VERSION ""

NS_ :

BS_:

BU_: Vector__XXX

BO_ 2365402110 EJM6: 8 Vector__XXX
SG_ Jystck6GrpXAxsNtrlPositionStatus : 0|2@1+ (1,0) [0|3] "" Vector__XXX
SG_ Jystck6GrpXAxsLvrLftNegPosStatus : 2|2@1+ (1,0) [0|3] "" Vector__XXX
SG_ Jystck6GrpXAxsLvrRghtPstvPosStat : 4|2@1+ (1,0) [0|3] "" Vector__XXX
SG_ Joystick6GripXAxisPosition : 6|10@1+ (0.1,0) [0|102] "%" Vector__XXX
SG_ Jystck6GrpYAxsNtrlPositionStatus : 16|2@1+ (1,0) [0|3] "" Vector__XXX
SG_ Jystck6GrpYAxsLvrBackNegPosStat : 18|2@1+ (1,0) [0|3] "" Vector__XXX
SG_ Jystck6GrpYAxsLvrFrwdPstvPosStat : 20|2@1+ (1,0) [0|3] "" Vector__XXX
SG_ Joystick6GripYAxisPosition : 22|10@1+ (0.1,0) [0|102] "%" Vector__XXX
SG_ Jystck6ThetaAxsNtrlPosStatus : 32|2@1+ (1,0) [0|3] "" Vector__XXX
SG_ Jystck6ThtAxsCntrClckwsNegPsStat : 34|2@1+ (1,0) [0|3] "" Vector__XXX
SG_ Jystck6ThetaAxsClckwsPstvPosStat : 36|2@1+ (1,0) [0|3] "" Vector__XXX
SG_ Joystick6ThetaAxisPosition : 38|10@1+ (0.1,0) [0|102] "%" Vector__XXX
SG_ Jystck6ThetaAxsDetentPosStatus : 50|2@1+ (1,0) [0|3] "" Vector__XXX
SG_ Jystck6GrpYAxsDetentPosStatus : 52|2@1+ (1,0) [0|3] "" Vector__XXX
SG_ Jystck6GrpXAxsDetentPosStatus : 54|2@1+ (1,0) [0|3] "" Vector__XXX
SG_ Joystick6Button16PressedStatus : 56|2@1+ (1,0) [0|3] "" Vector__XXX
SG_ Joystick6Button15PressedStatus : 58|2@1+ (1,0) [0|3] "" Vector__XXX
SG_ Joystick6Button14PressedStatus : 60|2@1+ (1,0) [0|3] "" Vector__XXX
SG_ Joystick6Button13PressedStatus : 62|2@1+ (1,0) [0|3] "" Vector__XXX

BO_ 2365402366 BJM6: 8 Vector__XXX
SG_ Jystck6XAxsNeutralPositionStatus : 0|2@1+ (1,0) [0|3] "" Vector__XXX
SG_ Jystck6XAxsLvrLftNegPosStatus : 2|2@1+ (1,0) [0|3] "" Vector__XXX
SG_ Jystck6XAxsLvrRightPstvPosStatus : 4|2@1+ (1,0) [0|3] "" Vector__XXX
SG_ Joystick6XAxisPosition : 6|10@1+ (0.1,0) [0|102] "%" Vector__XXX
SG_ Jystck6YAxsNeutralPositionStatus : 16|2@1+ (1,0) [0|3] "" Vector__XXX
SG_ Jystck6YAxsLvrBackNegPosStatus : 18|2@1+ (1,0) [0|3] "" Vector__XXX
SG_ Jystck6YAxsLvrFrwdPstvPosStatus : 20|2@1+ (1,0) [0|3] "" Vector__XXX
SG_ Joystick6YAxisPosition : 22|10@1+ (0.1,0) [0|102] "%" Vector__XXX
SG_ Jystck6YAxsDetentPositionStatus : 36|2@1+ (1,0) [0|3] "" Vector__XXX
SG_ Jystck6XAxsDetentPositionStatus : 38|2@1+ (1,0) [0|3] "" Vector__XXX
SG_ Joystick6Button4PressedStatus : 40|2@1+ (1,0) [0|3] "" Vector__XXX
SG_ Joystick6Button3PressedStatus : 42|2@1+ (1,0) [0|3] "" Vector__XXX
SG_ Joystick6Button2PressedStatus : 44|2@1+ (1,0) [0|3] "" Vector__XXX
SG_ Joystick6Button1PressedStatus : 46|2@1+ (1,0) [0|3] "" Vector__XXX
SG_ Joystick6Button8PressedStatus : 48|2@1+ (1,0) [0|3] "" Vector__XXX
SG_ Joystick6Button7PressedStatus : 50|2@1+ (1,0) [0|3] "" Vector__XXX
SG_ Joystick6Button6PressedStatus : 52|2@1+ (1,0) [0|3] "" Vector__XXX
SG_ Joystick6Button5PressedStatus : 54|2@1+ (1,0) [0|3] "" Vector__XXX
SG_ Joystick6Button12PressedStatus : 56|2@1+ (1,0) [0|3] "" Vector__XXX
SG_ Joystick6Button11PressedStatus : 58|2@1+ (1,0) [0|3] "" Vector__XXX
SG_ Joystick6Button10PressedStatus : 60|2@1+ (1,0) [0|3] "" Vector__XXX
SG_ Joystick6Button9PressedStatus : 62|2@1+ (1,0) [0|3] "" Vector__XXX

BO_ 2365402622 EJM5: 8 Vector__XXX
SG_ Jystck5GrpXAxsNtrlPositionStatus : 0|2@1+ (1,0) [0|3] "" Vector__XXX
SG_ Jystck5GrpXAxsLvrLftNegPosStatus : 2|2@1+ (1,0) [0|3] "" Vector__XXX
SG_ Jystck5GrpXAxsLvrRghtPstvPosStat : 4|2@1+ (1,0) [0|3] "" Vector__XXX
SG_ Joystick5GripXAxisPosition : 6|10@1+ (0.1,0) [0|102] "%" Vector__XXX
SG_ Jystck5GrpYAxsNtrlPositionStatus : 16|2@1+ (1,0) [0|3] "" Vector__XXX
SG_ Jystck5GrpYAxsLvrBackNegPosStat : 18|2@1+ (1,0) [0|3] "" Vector__XXX
SG_ Jystck5GrpYAxsLvrFrwdPstvPosStat : 20|2@1+ (1,0) [0|3] "" Vector__XXX
SG_ Joystick5GripYAxisPosition : 22|10@1+ (0.1,0) [0|102] "%" Vector__XXX
SG_ Jystck5ThetaAxsNtrlPosStatus : 32|2@1+ (1,0) [0|3] "" Vector__XXX
SG_ Jystck5ThtAxsCntrClckwsNegPsStat : 34|2@1+ (1,0) [0|3] "" Vector__XXX
SG_ Jystck5ThetaAxsClckwsPstvPosStat : 36|2@1+ (1,0) [0|3] "" Vector__XXX
SG_ Joystick5ThetaAxisPosition : 38|10@1+ (0.1,0) [0|102] "%" Vector__XXX
SG_ Jystck5ThetaAxsDetentPosStatus : 50|2@1+ (1,0) [0|3] "" Vector__XXX
SG_ Jystck5GrpYAxsDetentPosStatus : 52|2@1+ (1,0) [0|3] "" Vector__XXX
SG_ Jystck5GrpXAxsDetentPosStatus : 54|2@1+ (1,0) [0|3] "" Vector__XXX
SG_ Joystick5Button16PressedStatus : 56|2@1+ (1,0) [0|3] "" Vector__XXX
SG_ Joystick5Button15PressedStatus : 58|2@1+ (1,0) [0|3] "" Vector__XXX
SG_ Joystick5Button14PressedStatus : 60|2@1+ (1,0) [0|3] "" Vector__XXX
SG_ Joystick5Button13PressedStatus : 62|2@1+ (1,0) [0|3] "" Vector__XXX

BO_ 2365402878 BJM5: 8 Vector__XXX
SG_ Jystck5XAxsNeutralPositionStatus : 0|2@1+ (1,0) [0|3] "" Vector__XXX
SG_ Jystck5XAxsLvrLftNegPosStatus : 2|2@1+ (1,0) [0|3] "" Vector__XXX
SG_ Jystck5XAxsLvrRightPstvPosStatus : 4|2@1+ (1,0) [0|3] "" Vector__XXX
SG_ Joystick5XAxisPosition : 6|10@1+ (0.1,0) [0|102] "%" Vector__XXX
SG_ Jystck5YAxsNeutralPositionStatus : 16|2@1+ (1,0) [0|3] "" Vector__XXX
SG_ Jystck5YAxsLvrBackNegPosStatus : 18|2@1+ (1,0) [0|3] "" Vector__XXX
SG_ Jystck5YAxsLvrFrwdPstvPosStatus : 20|2@1+ (1,0) [0|3] "" Vector__XXX
SG_ Joystick5YAxisPosition : 22|10@1+ (0.1,0) [0|102] "%" Vector__XXX
SG_ Jystck5YAxsDetentPositionStatus : 36|2@1+ (1,0) [0|3] "" Vector__XXX
SG_ Jystck5XAxsDetentPositionStatus : 38|2@1+ (1,0) [0|3] "" Vector__XXX
SG_ Joystick5Button4PressedStatus : 40|2@1+ (1,0) [0|3] "" Vector__XXX
SG_ Joystick5Button3PressedStatus : 42|2@1+ (1,0) [0|3] "" Vector__XXX
SG_ Joystick5Button2PressedStatus : 44|2@1+ (1,0) [0|3] "" Vector__XXX
SG_ Joystick5Button1PressedStatus : 46|2@1+ (1,0) [0|3] "" Vector__XXX
SG_ Joystick5Button8PressedStatus : 48|2@1+ (1,0) [0|3] "" Vector__XXX
SG_ Joystick5Button7PressedStatus : 50|2@1+ (1,0) [0|3] "" Vector__XXX
SG_ Joystick5Button6PressedStatus : 52|2@1+ (1,0) [0|3] "" Vector__XXX
SG_ Joystick5Button5PressedStatus : 54|2@1+ (1,0) [0|3] "" Vector__XXX
SG_ Joystick5Button12PressedStatus : 56|2@1+ (1,0) [0|3] "" Vector__XXX
SG_ Joystick5Button11PressedStatus : 58|2@1+ (1,0) [0|3] "" Vector__XXX
SG_ Joystick5Button10PressedStatus : 60|2@1+ (1,0) [0|3] "" Vector__XXX
SG_ Joystick5Button9PressedStatus : 62|2@1+ (1,0) [0|3] "" Vector__XXX

BO_ 2365403134 EJM4: 8 Vector__XXX
SG_ Jystck4GrpXAxsNtrlPositionStatus : 0|2@1+ (1,0) [0|3] "" Vector__XXX
SG_ Jystck4GrpXAxsLvrLftNegPosStatus : 2|2@1+ (1,0) [0|3] "" Vector__XXX
SG_ Jystck4GrpXAxsLvrRghtPstvPosStat : 4|2@1+ (1,0) [0|3] "" Vector__XXX
SG_ Joystick4GripXAxisPosition : 6|10@1+ (0.1,0) [0|102] "%" Vector__XXX
SG_ Jystck4GrpYAxsNtrlPositionStatus : 16|2@1+ (1,0) [0|3] "" Vector__XXX
SG_ Jystck4GrpYAxsLvrBackNegPosStat : 18|2@1+ (1,0) [0|3] "" Vector__XXX
SG_ Jystck4GrpYAxsLvrFrwdPstvPosStat : 20|2@1+ (1,0) [0|3] "" Vector__XXX
SG_ Joystick4GripYAxisPosition : 22|10@1+ (0.1,0) [0|102] "%" Vector__XXX
SG_ Jystck4ThetaAxsNtrlPosStatus : 32|2@1+ (1,0) [0|3] "" Vector__XXX
SG_ Jystck4ThtAxsCntrClckwsNegPsStat : 34|2@1+ (1,0) [0|3] "" Vector__XXX
SG_ Jystck4ThetaAxsClckwsPstvPosStat : 36|2@1+ (1,0) [0|3] "" Vector__XXX
SG_ Joystick4ThetaAxisPosition : 38|10@1+ (0.1,0) [0|102] "%" Vector__XXX
SG_ Jystck4ThetaAxsDetentPosStatus : 50|2@1+ (1,0) [0|3] "" Vector__XXX
SG_ Jystck4GrpYAxsDetentPosStatus : 52|2@1+ (1,0) [0|3] "" Vector__XXX
SG_ Jystck4GrpXAxsDetentPosStatus : 54|2@1+ (1,0) [0|3] "" Vector__XXX
SG_ Joystick4Button16PressedStatus : 56|2@1+ (1,0) [0|3] "" Vector__XXX
SG_ Joystick4Button15PressedStatus : 58|2@1+ (1,0) [0|3] "" Vector__XXX
SG_ Joystick4Button14PressedStatus : 60|2@1+ (1,0) [0|3] "" Vector__XXX
SG_ Joystick4Button13PressedStatus : 62|2@1+ (1,0) [0|3] "" Vector__XXX

BO_ 2365403390 BJM4: 8 Vector__XXX
SG_ Jystck4XAxsNeutralPositionStatus : 0|2@1+ (1,0) [0|3] "" Vector__XXX
SG_ Jystck4XAxsLvrLftNegPosStatus : 2|2@1+ (1,0) [0|3] "" Vector__XXX
SG_ Jystck4XAxsLvrRightPstvPosStatus : 4|2@1+ (1,0) [0|3] "" Vector__XXX
SG_ Joystick4XAxisPosition : 6|10@1+ (0.1,0) [0|102] "%" Vector__XXX
SG_ Jystck4YAxsNeutralPositionStatus : 16|2@1+ (1,0) [0|3] "" Vector__XXX
SG_ Jystck4YAxsLvrBackNegPosStatus : 18|2@1+ (1,0) [0|3] "" Vector__XXX
SG_ Jystck4YAxsLvrFrwdPstvPosStatus : 20|2@1+ (1,0) [0|3] "" Vector__XXX
SG_ Joystick4YAxisPosition : 22|10@1+ (0.1,0) [0|102] "%" Vector__XXX
SG_ Jystck4YAxsDetentPositionStatus : 36|2@1+ (1,0) [0|3] "" Vector__XXX
SG_ Jystck4XAxsDetentPositionStatus : 38|2@1+ (1,0) [0|3] "" Vector__XXX
SG_ Joystick4Button4PressedStatus : 40|2@1+ (1,0) [0|3] "" Vector__XXX
SG_ Joystick4Button3PressedStatus : 42|2@1+ (1,0) [0|3] "" Vector__XXX
SG_ Joystick4Button2PressedStatus : 44|2@1+ (1,0) [0|3] "" Vector__XXX
SG_ Joystick4Button1PressedStatus : 46|2@1+ (1,0) [0|3] "" Vector__XXX
SG_ Joystick4Button8PressedStatus : 48|2@1+ (1,0) [0|3] "" Vector__XXX
SG_ Joystick4Button7PressedStatus : 50|2@1+ (1,0) [0|3] "" Vector__XXX
SG_ Joystick4Button6PressedStatus : 52|2@1+ (1,0) [0|3] "" Vector__XXX
SG_ Joystick4Button5PressedStatus : 54|2@1+ (1,0) [0|3] "" Vector__XXX
SG_ Joystick4Button12PressedStatus : 56|2@1+ (1,0) [0|3] "" Vector__XXX
SG_ Joystick4Button11PressedStatus : 58|2@1+ (1,0) [0|3] "" Vector__XXX
SG_ Joystick4Button10PressedStatus : 60|2@1+ (1,0) [0|3] "" Vector__XXX
SG_ Joystick4Button9PressedStatus : 62|2@1+ (1,0) [0|3] "" Vector__XXX

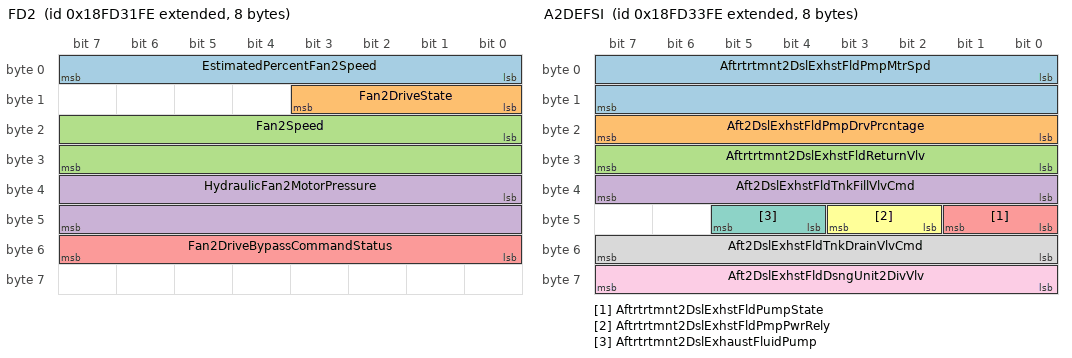
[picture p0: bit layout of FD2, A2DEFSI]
BO_ 2566730238 FD2: 8 Vector__XXX
SG_ EstimatedPercentFan2Speed : 0|8@1+ (0.4,0) [0|100] "%" Vector__XXX
SG_ Fan2DriveState : 8|4@1+ (1,0) [0|15] "" Vector__XXX
SG_ Fan2Speed : 16|16@1+ (0.125,0) [0|8031.875] "rpm" Vector__XXX
SG_ HydraulicFan2MotorPressure : 32|16@1+ (0.5,0) [0|32127.5] "kPa" Vector__XXX
SG_ Fan2DriveBypassCommandStatus : 48|8@1+ (0.4,0) [0|100] "%" Vector__XXX

BO_ 2566730750 A2DEFSI: 8 Vector__XXX
SG_ Aftrtrtmnt2DslExhstFldPmpMtrSpd : 0|16@1+ (0.5,0) [0|32127.5] "rpm" Vector__XXX
SG_ Aft2DslExhstFldPmpDrvPrcntage : 16|8@1+ (0.4,0) [0|100] "%" Vector__XXX
SG_ Aftrtrtmnt2DslExhstFldReturnVlv : 24|8@1+ (0.4,0) [0|100] "%" Vector__XXX
SG_ Aft2DslExhstFldTnkFillVlvCmd : 32|8@1+ (0.4,0) [0|100] "%" Vector__XXX
SG_ Aftrtrtmnt2DslExhstFldPumpState : 40|2@1+ (1,0) [0|3] "" Vector__XXX
SG_ Aftrtrtmnt2DslExhstFldPmpPwrRely : 42|2@1+ (1,0) [0|3] "" Vector__XXX
SG_ Aftrtrtmnt2DslExhaustFluidPump : 44|2@1+ (1,0) [0|3] "" Vector__XXX
SG_ Aft2DslExhstFldTnkDrainVlvCmd : 48|8@1+ (0.4,0) [0|100] "%" Vector__XXX
SG_ Aft2DslExhstFldDsngUnit2DivVlv : 56|8@1+ (0.4,0) [0|100] "%" Vector__XXX

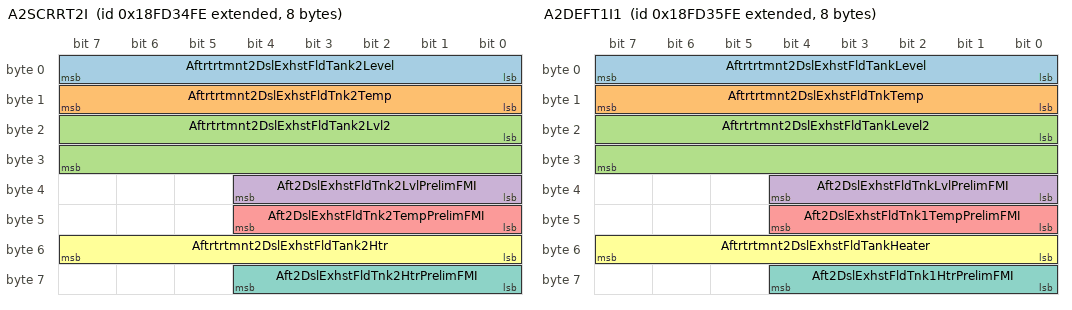
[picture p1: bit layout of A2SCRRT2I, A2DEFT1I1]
BO_ 2566731006 A2SCRRT2I: 8 Vector__XXX
SG_ Aftrtrtmnt2DslExhstFldTank2Level : 0|8@1+ (0.4,0) [0|100] "%" Vector__XXX
SG_ Aftrtrtmnt2DslExhstFldTnk2Temp : 8|8@1+ (1,-40) [-40|210] "deg C" Vector__XXX
SG_ Aftrtrtmnt2DslExhstFldTank2Lvl2 : 16|16@1+ (0.1,0) [0|6425.5] "mm" Vector__XXX
SG_ Aft2DslExhstFldTnk2LvlPrelimFMI : 32|5@1+ (1,0) [0|31] "" Vector__XXX
SG_ Aft2DslExhstFldTnk2TempPrelimFMI : 40|5@1+ (1,0) [0|31] "" Vector__XXX
SG_ Aftrtrtmnt2DslExhstFldTank2Htr : 48|8@1+ (0.4,0) [0|100] "%" Vector__XXX
SG_ Aft2DslExhstFldTnk2HtrPrelimFMI : 56|5@1+ (1,0) [0|31] "" Vector__XXX

BO_ 2566731262 A2DEFT1I1: 8 Vector__XXX
SG_ Aftrtrtmnt2DslExhstFldTankLevel : 0|8@1+ (0.4,0) [0|100] "%" Vector__XXX
SG_ Aftrtrtmnt2DslExhstFldTnkTemp : 8|8@1+ (1,-40) [-40|210] "deg C" Vector__XXX
SG_ Aftrtrtmnt2DslExhstFldTankLevel2 : 16|16@1+ (0.1,0) [0|6425.5] "mm" Vector__XXX
SG_ Aft2DslExhstFldTnkLvlPrelimFMI : 32|5@1+ (1,0) [0|31] "" Vector__XXX
SG_ Aft2DslExhstFldTnk1TempPrelimFMI : 40|5@1+ (1,0) [0|31] "" Vector__XXX
SG_ Aftrtrtmnt2DslExhstFldTankHeater : 48|8@1+ (0.4,0) [0|100] "%" Vector__XXX
SG_ Aft2DslExhstFldTnk1HtrPrelimFMI : 56|5@1+ (1,0) [0|31] "" Vector__XXX

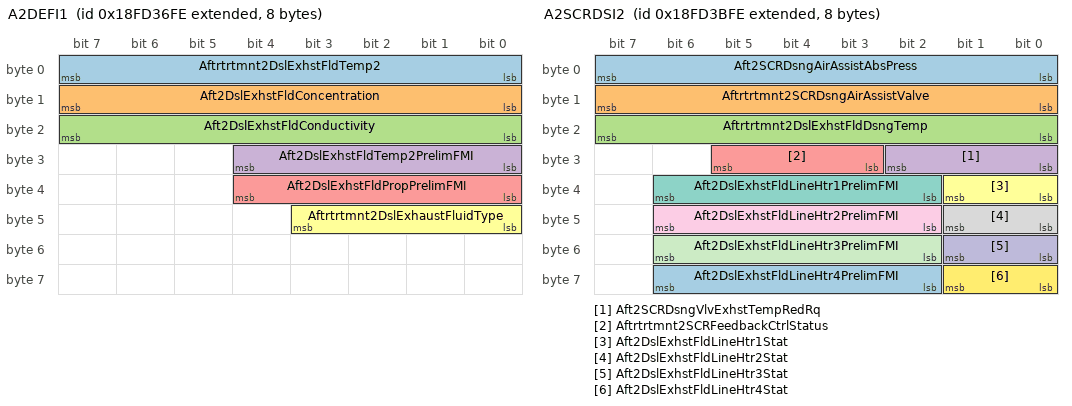
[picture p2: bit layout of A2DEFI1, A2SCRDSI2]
BO_ 2566731518 A2DEFI1: 8 Vector__XXX
SG_ Aftrtrtmnt2DslExhstFldTemp2 : 0|8@1+ (1,-40) [-40|210] "deg C" Vector__XXX
SG_ Aft2DslExhstFldConcentration : 8|8@1+ (0.25,0) [0|62.5] "%" Vector__XXX
SG_ Aft2DslExhstFldConductivity : 16|8@1+ (5,0) [0|1250] "uSiemens/mm" Vector__XXX
SG_ Aft2DslExhstFldTemp2PrelimFMI : 24|5@1+ (1,0) [0|31] "" Vector__XXX
SG_ Aft2DslExhstFldPropPrelimFMI : 32|5@1+ (1,0) [0|31] "" Vector__XXX
SG_ Aftrtrtmnt2DslExhaustFluidType : 40|4@1+ (1,0) [0|15] "" Vector__XXX

BO_ 2566731774 A2SCRSI1: 8 Vector__XXX
SG_ Aft2DslExhstFldAvrgCnsmptn : 0|16@1+ (0.05,0) [0|3212.75] "l/h" Vector__XXX
SG_ Aft2SCRCmdedDslExhstFldCnsmptn : 16|16@1+ (0.05,0) [0|3212.75] "l/h" Vector__XXX
SG_ Aftrtrtmnt2SCRCnvrsnEfficiency : 32|8@1+ (0.4,0) [0|100] "%" Vector__XXX
SG_ Aftrtrtmnt2SCRSystemSulfationLvl : 40|8@1+ (1,0) [0|250] "%" Vector__XXX

BO_ 2566732030 A2SCREGT1: 8 Vector__XXX
SG_ Aftrtrtmnt2SCRIntakeTemperature : 0|16@1+ (0.03125,-273) [-273|1734.96875] "deg C" Vector__XXX
SG_ Aftrtrtmnt2SCRIntkTempPrelimFMI : 16|5@1+ (1,0) [0|31] "" Vector__XXX
SG_ Aftrtrtmnt2SCROutletTemperature : 24|16@1+ (0.03125,-273) [-273|1734.96875] "deg C" Vector__XXX
SG_ Aftrtrtmnt2SCROtltTempPrelimFMI : 40|5@1+ (1,0) [0|31] "" Vector__XXX

BO_ 2566732286 A2SCREGP: 8 Vector__XXX
SG_ Aftrtrtmnt2SCRDiffPressure : 0|16@1+ (0.1,0) [0|6425.5] "kPa" Vector__XXX
SG_ Aftrtrtmnt2SCRDiffPressPrelimFMI : 16|5@1+ (1,0) [0|31] "" Vector__XXX
SG_ Aftertreatment2SCRIntakePressure : 24|16@1+ (0.1,-3212.7) [-3212.7|3212.8] "kPa" Vector__XXX
SG_ Aftrtrtmnt2SCRIntakeAbsPressure : 40|16@1+ (0.1,0) [0|6425.5] "kPa" Vector__XXX

BO_ 2566732542 A2SCRDSR2: 8 Vector__XXX
SG_ Aft2DslExhstFldDsrFltSupPrsionRq : 2|2@1+ (1,0) [0|3] "" Vector__XXX
SG_ Aft2DslExhstFldDoserHeatingMdeRq : 4|3@1+ (1,0) [0|7] "" Vector__XXX
SG_ Aftrtrtmnt2DslExhstFldLineHtr1 : 8|2@1+ (1,0) [0|3] "" Vector__XXX
SG_ Aftrtrtmnt2DslExhstFldLineHtr2 : 10|2@1+ (1,0) [0|3] "" Vector__XXX
SG_ Aftrtrtmnt2DslExhstFldLineHtr3 : 12|2@1+ (1,0) [0|3] "" Vector__XXX
SG_ Aftrtrtmnt2DslExhstFldLineHtr4 : 14|2@1+ (1,0) [0|3] "" Vector__XXX
SG_ Aftrtrtmnt2DslExhstFldTankHtrCmd : 16|8@1+ (0.4,0) [0|100] "%" Vector__XXX
SG_ Aftrtrtmnt2DslExhstFldTnk2HtrCmd : 24|8@1+ (0.4,0) [0|100] "%" Vector__XXX
SG_ Aft2DslExhstFldLineHtrRely1 : 32|2@1+ (1,0) [0|3] "" Vector__XXX
SG_ Aft2DslExhstFldLineHtrRely2 : 34|2@1+ (1,0) [0|3] "" Vector__XXX
SG_ Aft2DslExhstFldLineHtrRely3 : 36|2@1+ (1,0) [0|3] "" Vector__XXX
SG_ Aftrtrtmnt2DslExhstFldLineHtr5 : 38|2@1+ (1,0) [0|3] "" Vector__XXX
SG_ Aftrtrtmnt2DslExhstFldLineHtr6 : 40|2@1+ (1,0) [0|3] "" Vector__XXX
SG_ Aftrtrtmnt2DslExhstFldLineHtr7 : 42|2@1+ (1,0) [0|3] "" Vector__XXX
SG_ Aftrtrtmnt2DslExhstFldLineHtr8 : 44|2@1+ (1,0) [0|3] "" Vector__XXX
SG_ Aftrtrtmnt2DslExhstFldLineHtr9 : 46|2@1+ (1,0) [0|3] "" Vector__XXX
SG_ Aftrtrtmnt2DslExhstFldLineHtr10 : 48|2@1+ (1,0) [0|3] "" Vector__XXX

BO_ 2566732798 A2SCRDSI2: 8 Vector__XXX
SG_ Aft2SCRDsngAirAssistAbsPress : 0|8@1+ (8,0) [0|2000] "kPa" Vector__XXX
SG_ Aftrtrtmnt2SCRDsngAirAssistValve : 8|8@1+ (0.4,0) [0|100] "%" Vector__XXX
SG_ Aftrtrtmnt2DslExhstFldDsngTemp : 16|8@1+ (1,-40) [-40|210] "deg C" Vector__XXX
SG_ Aft2SCRDsngVlvExhstTempRedRq : 24|3@1+ (1,0) [0|7] "" Vector__XXX
SG_ Aftrtrtmnt2SCRFeedbackCtrlStatus : 27|3@1+ (1,0) [0|7] "" Vector__XXX
SG_ Aft2DslExhstFldLineHtr1Stat : 32|2@1+ (1,0) [0|3] "" Vector__XXX
SG_ Aft2DslExhstFldLineHtr1PrelimFMI : 34|5@1+ (1,0) [0|31] "" Vector__XXX
SG_ Aft2DslExhstFldLineHtr2Stat : 40|2@1+ (1,0) [0|3] "" Vector__XXX
SG_ Aft2DslExhstFldLineHtr2PrelimFMI : 42|5@1+ (1,0) [0|31] "" Vector__XXX
SG_ Aft2DslExhstFldLineHtr3Stat : 48|2@1+ (1,0) [0|3] "" Vector__XXX
SG_ Aft2DslExhstFldLineHtr3PrelimFMI : 50|5@1+ (1,0) [0|31] "" Vector__XXX
SG_ Aft2DslExhstFldLineHtr4Stat : 56|2@1+ (1,0) [0|3] "" Vector__XXX
SG_ Aft2DslExhstFldLineHtr4PrelimFMI : 58|5@1+ (1,0) [0|31] "" Vector__XXX

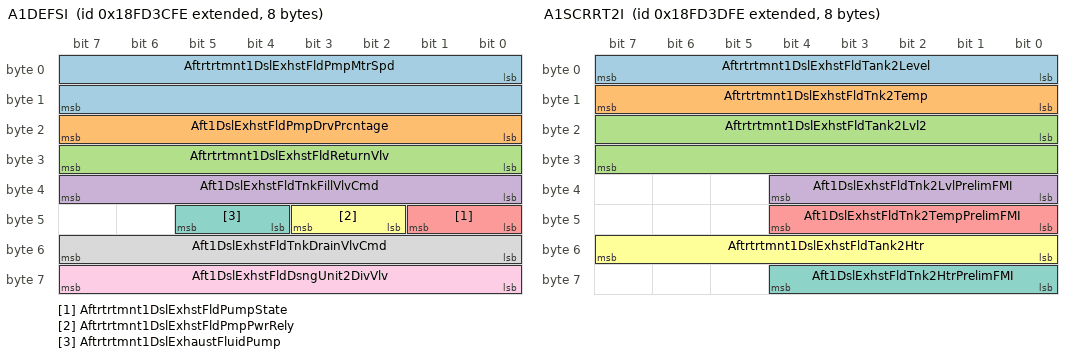
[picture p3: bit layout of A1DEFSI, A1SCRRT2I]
BO_ 2566733054 A1DEFSI: 8 Vector__XXX
SG_ Aftrtrtmnt1DslExhstFldPmpMtrSpd : 0|16@1+ (0.5,0) [0|32127.5] "rpm" Vector__XXX
SG_ Aft1DslExhstFldPmpDrvPrcntage : 16|8@1+ (0.4,0) [0|100] "%" Vector__XXX
SG_ Aftrtrtmnt1DslExhstFldReturnVlv : 24|8@1+ (0.4,0) [0|100] "%" Vector__XXX
SG_ Aft1DslExhstFldTnkFillVlvCmd : 32|8@1+ (0.4,0) [0|100] "%" Vector__XXX
SG_ Aftrtrtmnt1DslExhstFldPumpState : 40|2@1+ (1,0) [0|3] "" Vector__XXX
SG_ Aftrtrtmnt1DslExhstFldPmpPwrRely : 42|2@1+ (1,0) [0|3] "" Vector__XXX
SG_ Aftrtrtmnt1DslExhaustFluidPump : 44|2@1+ (1,0) [0|3] "" Vector__XXX
SG_ Aft1DslExhstFldTnkDrainVlvCmd : 48|8@1+ (0.4,0) [0|100] "%" Vector__XXX
SG_ Aft1DslExhstFldDsngUnit2DivVlv : 56|8@1+ (0.4,0) [0|100] "%" Vector__XXX

BO_ 2566733310 A1SCRRT2I: 8 Vector__XXX
SG_ Aftrtrtmnt1DslExhstFldTank2Level : 0|8@1+ (0.4,0) [0|100] "%" Vector__XXX
SG_ Aftrtrtmnt1DslExhstFldTnk2Temp : 8|8@1+ (1,-40) [-40|210] "deg C" Vector__XXX
SG_ Aftrtrtmnt1DslExhstFldTank2Lvl2 : 16|16@1+ (0.1,0) [0|6425.5] "mm" Vector__XXX
SG_ Aft1DslExhstFldTnk2LvlPrelimFMI : 32|5@1+ (1,0) [0|31] "" Vector__XXX
SG_ Aft1DslExhstFldTnk2TempPrelimFMI : 40|5@1+ (1,0) [0|31] "" Vector__XXX
SG_ Aftrtrtmnt1DslExhstFldTank2Htr : 48|8@1+ (0.4,0) [0|100] "%" Vector__XXX
SG_ Aft1DslExhstFldTnk2HtrPrelimFMI : 56|5@1+ (1,0) [0|31] "" Vector__XXX

BO_ 2499624702 A1SCREGT1: 8 Vector__XXX
SG_ Aftrtrtmnt1SCRIntakeTemperature : 0|16@1+ (0.03125,-273) [-273|1734.96875] "deg C" Vector__XXX
SG_ Aftrtrtmnt1SCRIntkTempPrelimFMI : 16|5@1+ (1,0) [0|31] "" Vector__XXX
SG_ Aftrtrtmnt1SCROutletTemperature : 24|16@1+ (0.03125,-273) [-273|1734.96875] "deg C" Vector__XXX
SG_ Aftrtrtmnt1SCROtltTempPrelimFMI : 40|5@1+ (1,0) [0|31] "" Vector__XXX

BO_ 2566733822 A1SCREGP: 8 Vector__XXX
SG_ Aftrtrtmnt1SCRDiffPressure : 0|16@1+ (0.1,0) [0|6425.5] "kPa" Vector__XXX
SG_ Aftrtrtmnt1SCRDiffPressPrelimFMI : 16|5@1+ (1,0) [0|31] "" Vector__XXX
SG_ Aftertreatment1SCRIntakePressure : 24|16@1+ (0.1,-3212.7) [-3212.7|3212.8] "kPa" Vector__XXX
SG_ Aftrtrtmnt1SCRIntakeAbsPressure : 40|16@1+ (0.1,0) [0|6425.5] "kPa" Vector__XXX

BO_ 2566734078 A1SCRDSR2: 8 Vector__XXX
SG_ Aft1DslExhstFldDsrFltSupPrsionRq : 2|2@1+ (1,0) [0|3] "" Vector__XXX
SG_ Aft1DslExhstFldDoserHeatingMdeRq : 4|3@1+ (1,0) [0|7] "" Vector__XXX
SG_ Aftrtrtmnt1DslExhstFldLineHtr1 : 8|2@1+ (1,0) [0|3] "" Vector__XXX
SG_ Aftrtrtmnt1DslExhstFldLineHtr2 : 10|2@1+ (1,0) [0|3] "" Vector__XXX
SG_ Aftrtrtmnt1DslExhstFldLineHtr3 : 12|2@1+ (1,0) [0|3] "" Vector__XXX
SG_ Aftrtrtmnt1DslExhstFldLineHtr4 : 14|2@1+ (1,0) [0|3] "" Vector__XXX
SG_ Aftrtrtmnt1DslExhstFldTankHtrCmd : 16|8@1+ (0.4,0) [0|100] "%" Vector__XXX
SG_ Aftrtrtmnt1DslExhstFldTnk2HtrCmd : 24|8@1+ (0.4,0) [0|100] "%" Vector__XXX
SG_ Aftrtrtmnt1DslExhstFldPumpHtrCmd : 32|8@1+ (0.4,0) [0|100] "%" Vector__XXX
SG_ Aft1DslExhstFldLineHtrRely1 : 40|2@1+ (1,0) [0|3] "" Vector__XXX
SG_ Aft1DslExhstFldLineHtrRely2 : 42|2@1+ (1,0) [0|3] "" Vector__XXX
SG_ Aft1DslExhstFldLineHtrRely3 : 44|2@1+ (1,0) [0|3] "" Vector__XXX
SG_ Aftrtrtmnt1DslExhstFldLineHtr5 : 46|2@1+ (1,0) [0|3] "" Vector__XXX
SG_ Aftrtrtmnt1DslExhstFldLineHtr6 : 48|2@1+ (1,0) [0|3] "" Vector__XXX
SG_ Aftrtrtmnt1DslExhstFldLineHtr7 : 50|2@1+ (1,0) [0|3] "" Vector__XXX
SG_ Aftrtrtmnt1DslExhstFldLineHtr8 : 52|2@1+ (1,0) [0|3] "" Vector__XXX
SG_ Aftrtrtmnt1DslExhstFldLineHtr9 : 54|2@1+ (1,0) [0|3] "" Vector__XXX
SG_ Aftrtrtmnt1DslExhstFldLineHtr10 : 56|2@1+ (1,0) [0|3] "" Vector__XXX

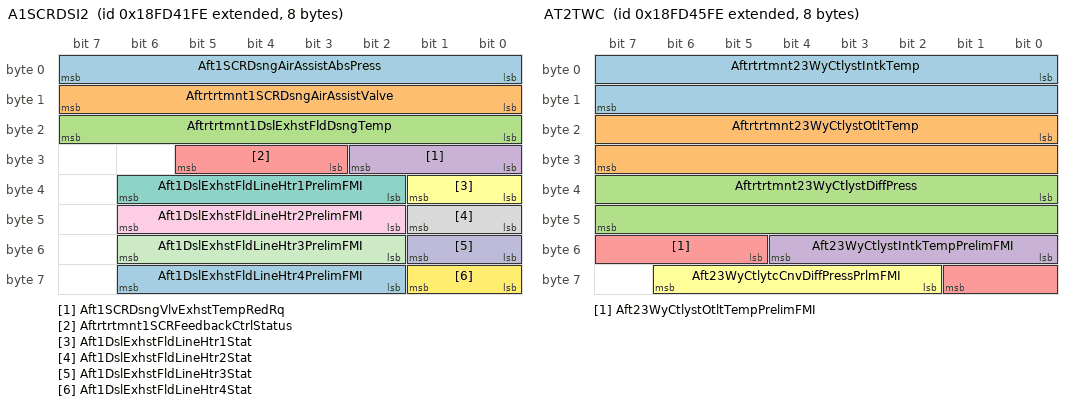
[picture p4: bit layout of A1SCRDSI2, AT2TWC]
BO_ 2566734334 A1SCRDSI2: 8 Vector__XXX
SG_ Aft1SCRDsngAirAssistAbsPress : 0|8@1+ (8,0) [0|2000] "kPa" Vector__XXX
SG_ Aftrtrtmnt1SCRDsngAirAssistValve : 8|8@1+ (0.4,0) [0|100] "%" Vector__XXX
SG_ Aftrtrtmnt1DslExhstFldDsngTemp : 16|8@1+ (1,-40) [-40|210] "deg C" Vector__XXX
SG_ Aft1SCRDsngVlvExhstTempRedRq : 24|3@1+ (1,0) [0|7] "" Vector__XXX
SG_ Aftrtrtmnt1SCRFeedbackCtrlStatus : 27|3@1+ (1,0) [0|7] "" Vector__XXX
SG_ Aft1DslExhstFldLineHtr1Stat : 32|2@1+ (1,0) [0|3] "" Vector__XXX
SG_ Aft1DslExhstFldLineHtr1PrelimFMI : 34|5@1+ (1,0) [0|31] "" Vector__XXX
SG_ Aft1DslExhstFldLineHtr2Stat : 40|2@1+ (1,0) [0|3] "" Vector__XXX
SG_ Aft1DslExhstFldLineHtr2PrelimFMI : 42|5@1+ (1,0) [0|31] "" Vector__XXX
SG_ Aft1DslExhstFldLineHtr3Stat : 48|2@1+ (1,0) [0|3] "" Vector__XXX
SG_ Aft1DslExhstFldLineHtr3PrelimFMI : 50|5@1+ (1,0) [0|31] "" Vector__XXX
SG_ Aft1DslExhstFldLineHtr4Stat : 56|2@1+ (1,0) [0|3] "" Vector__XXX
SG_ Aft1DslExhstFldLineHtr4PrelimFMI : 58|5@1+ (1,0) [0|31] "" Vector__XXX

BO_ 2566735102 AT2FC2: 8 Vector__XXX
SG_ Aftertreatment2FuelPressure2 : 0|16@1+ (0.1,0) [0|6425.5] "kPa" Vector__XXX
SG_ Aftrtrtmnt2FuelPumpRelayControl : 16|2@1+ (1,0) [0|3] "" Vector__XXX
SG_ Aft2FuelFlwDiverterVlvCtrl : 18|2@1+ (1,0) [0|3] "" Vector__XXX
SG_ Aftrtrtmnt2FuelPressure2Control : 24|16@1+ (0.0025,0) [0|160.6375] "%" Vector__XXX

BO_ 2566735358 AT2TWC: 8 Vector__XXX
SG_ Aftrtrtmnt23WyCtlystIntkTemp : 0|16@1+ (0.03125,-273) [-273|1734.96875] "deg C" Vector__XXX
SG_ Aftrtrtmnt23WyCtlystOtltTemp : 16|16@1+ (0.03125,-273) [-273|1734.96875] "deg C" Vector__XXX
SG_ Aftrtrtmnt23WyCtlystDiffPress : 32|16@1+ (0.1,0) [0|6425.5] "kPa" Vector__XXX
SG_ Aft23WyCtlystIntkTempPrelimFMI : 48|5@1+ (1,0) [0|31] "" Vector__XXX
SG_ Aft23WyCtlystOtltTempPrelimFMI : 53|5@1+ (1,0) [0|31] "" Vector__XXX
SG_ Aft23WyCtlytcCnvDiffPressPrlmFMI : 58|5@1+ (1,0) [0|31] "" Vector__XXX

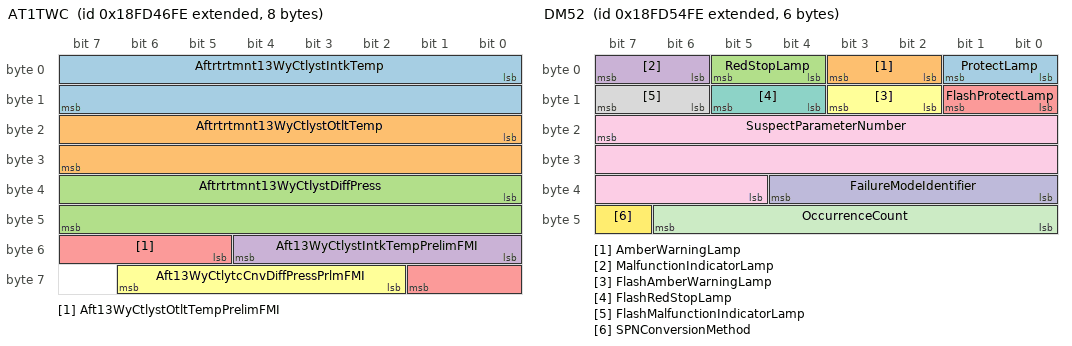
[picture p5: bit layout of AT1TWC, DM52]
BO_ 2566735614 AT1TWC: 8 Vector__XXX
SG_ Aftrtrtmnt13WyCtlystIntkTemp : 0|16@1+ (0.03125,-273) [-273|1734.96875] "deg C" Vector__XXX
SG_ Aftrtrtmnt13WyCtlystOtltTemp : 16|16@1+ (0.03125,-273) [-273|1734.96875] "deg C" Vector__XXX
SG_ Aftrtrtmnt13WyCtlystDiffPress : 32|16@1+ (0.1,0) [0|6425.5] "kPa" Vector__XXX
SG_ Aft13WyCtlystIntkTempPrelimFMI : 48|5@1+ (1,0) [0|31] "" Vector__XXX
SG_ Aft13WyCtlystOtltTempPrelimFMI : 53|5@1+ (1,0) [0|31] "" Vector__XXX
SG_ Aft13WyCtlytcCnvDiffPressPrlmFMI : 58|5@1+ (1,0) [0|31] "" Vector__XXX

BO_ 2633844734 TML: 8 Vector__XXX

BO_ 2566736126 O2FT2: 8 Vector__XXX
SG_ LongTermFuelTrimBank2 : 0|16@1+ (0.1,-100) [-100|100] "%" Vector__XXX
SG_ ShortTermFuelTrimBank2 : 16|16@1+ (0.1,-100) [-100|100] "%" Vector__XXX
SG_ EngExhstBnk2O2SensorClsdLpOp : 32|4@1+ (1,0) [0|15] "" Vector__XXX

BO_ 2566736382 O2FT1: 8 Vector__XXX
SG_ LongTermFuelTrimBank1 : 0|16@1+ (0.1,-100) [-100|100] "%" Vector__XXX
SG_ ShortTermFuelTrimBank1 : 16|16@1+ (0.1,-100) [-100|100] "%" Vector__XXX
SG_ EngExhstBnk1O2SensorClsdLpOp : 32|4@1+ (1,0) [0|15] "" Vector__XXX

BO_ 2432520702 ACCVC: 8 Vector__XXX
SG_ AftercoolerCoolantThermostatMode : 0|2@1+ (1,0) [0|3] "" Vector__XXX
SG_ DsrdAftrclrCoolntIntkTemperature : 8|8@1+ (1,-40) [-40|210] "deg C" Vector__XXX
SG_ DsrdAftrclrCoolntThrmsttOpening : 16|8@1+ (0.4,0) [0|100] "%" Vector__XXX
SG_ EngineChrgAirCoolBypssValve1Cmd : 24|16@1+ (0.0025,0) [0|160.6375] "%" Vector__XXX
SG_ EngineChrgAirCoolBypssValve2Cmd : 40|16@1+ (0.0025,0) [0|160.6375] "%" Vector__XXX

BO_ 2432520958 ECCVC: 8 Vector__XXX
SG_ EngineCoolantThermostatMode : 0|2@1+ (1,0) [0|3] "" Vector__XXX
SG_ DsrdEngCoolntPumpOtltTemperature : 8|8@1+ (1,-40) [-40|210] "deg C" Vector__XXX
SG_ DsrdEngCoolntThermostatOpening : 16|8@1+ (0.4,0) [0|100] "%" Vector__XXX
SG_ EngineAuxCoolSupplyValve1ActrCmd : 24|8@1+ (0.4,0) [0|100] "%" Vector__XXX
SG_ EngineAuxCoolSupplyValve2ActrCmd : 32|8@1+ (0.4,0) [0|100] "%" Vector__XXX

BO_ 2499630078 EAI: 8 Vector__XXX
SG_ EngineExhaustTemperatureAverage : 0|16@1+ (0.03125,-273) [-273|1734.96875] "deg C" Vector__XXX
SG_ EngineExhaustBnk1TemperatureAvrg : 16|16@1+ (0.03125,-273) [-273|1734.96875] "deg C" Vector__XXX
SG_ EngineExhaustBnk2TemperatureAvrg : 32|16@1+ (0.03125,-273) [-273|1734.96875] "deg C" Vector__XXX

BO_ 2566739198 DM52: 6 Vector__XXX
SG_ ProtectLamp : 0|2@1+ (1,0) [0|3] "" Vector__XXX
SG_ AmberWarningLamp : 2|2@1+ (1,0) [0|3] "" Vector__XXX
SG_ RedStopLamp : 4|2@1+ (1,0) [0|3] "" Vector__XXX
SG_ MalfunctionIndicatorLamp : 6|2@1+ (1,0) [0|3] "" Vector__XXX
SG_ FlashProtectLamp : 8|2@1+ (1,0) [0|3] "" Vector__XXX
SG_ FlashAmberWarningLamp : 10|2@1+ (1,0) [0|3] "" Vector__XXX
SG_ FlashRedStopLamp : 12|2@1+ (1,0) [0|3] "" Vector__XXX
SG_ FlashMalfunctionIndicatorLamp : 14|2@1+ (1,0) [0|3] "" Vector__XXX
SG_ SuspectParameterNumber : 23|19@0+ (1,0) [0|524287] "" Vector__XXX
SG_ FailureModeIdentifier : 32|5@1+ (1,0) [0|31] "" Vector__XXX
SG_ OccurrenceCount : 40|7@1+ (1,0) [0|127] "" Vector__XXX
SG_ SPNConversionMethod : 47|1@1+ (1,0) [0|1] "" Vector__XXX

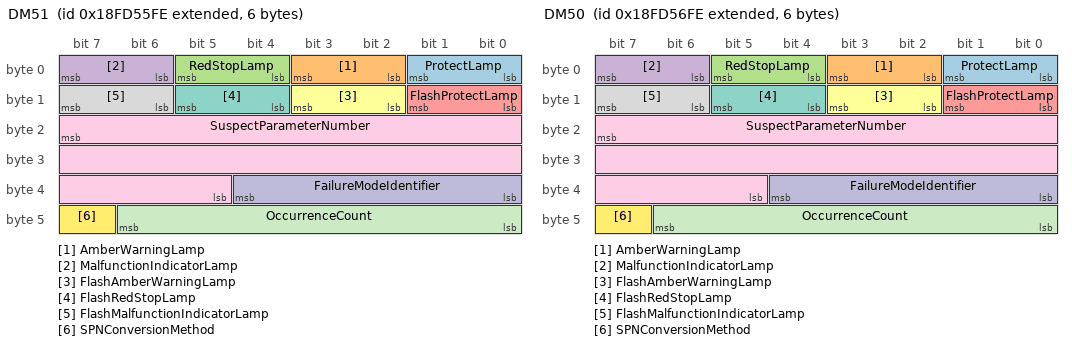
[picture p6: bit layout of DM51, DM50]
BO_ 2566739454 DM51: 6 Vector__XXX
SG_ ProtectLamp : 0|2@1+ (1,0) [0|3] "" Vector__XXX
SG_ AmberWarningLamp : 2|2@1+ (1,0) [0|3] "" Vector__XXX
SG_ RedStopLamp : 4|2@1+ (1,0) [0|3] "" Vector__XXX
SG_ MalfunctionIndicatorLamp : 6|2@1+ (1,0) [0|3] "" Vector__XXX
SG_ FlashProtectLamp : 8|2@1+ (1,0) [0|3] "" Vector__XXX
SG_ FlashAmberWarningLamp : 10|2@1+ (1,0) [0|3] "" Vector__XXX
SG_ FlashRedStopLamp : 12|2@1+ (1,0) [0|3] "" Vector__XXX
SG_ FlashMalfunctionIndicatorLamp : 14|2@1+ (1,0) [0|3] "" Vector__XXX
SG_ SuspectParameterNumber : 23|19@0+ (1,0) [0|524287] "" Vector__XXX
SG_ FailureModeIdentifier : 32|5@1+ (1,0) [0|31] "" Vector__XXX
SG_ OccurrenceCount : 40|7@1+ (1,0) [0|127] "" Vector__XXX
SG_ SPNConversionMethod : 47|1@1+ (1,0) [0|1] "" Vector__XXX

BO_ 2566739710 DM50: 6 Vector__XXX
SG_ ProtectLamp : 0|2@1+ (1,0) [0|3] "" Vector__XXX
SG_ AmberWarningLamp : 2|2@1+ (1,0) [0|3] "" Vector__XXX
SG_ RedStopLamp : 4|2@1+ (1,0) [0|3] "" Vector__XXX
SG_ MalfunctionIndicatorLamp : 6|2@1+ (1,0) [0|3] "" Vector__XXX
SG_ FlashProtectLamp : 8|2@1+ (1,0) [0|3] "" Vector__XXX
SG_ FlashAmberWarningLamp : 10|2@1+ (1,0) [0|3] "" Vector__XXX
SG_ FlashRedStopLamp : 12|2@1+ (1,0) [0|3] "" Vector__XXX
SG_ FlashMalfunctionIndicatorLamp : 14|2@1+ (1,0) [0|3] "" Vector__XXX
SG_ SuspectParameterNumber : 23|19@0+ (1,0) [0|524287] "" Vector__XXX
SG_ FailureModeIdentifier : 32|5@1+ (1,0) [0|31] "" Vector__XXX
SG_ OccurrenceCount : 40|7@1+ (1,0) [0|127] "" Vector__XXX
SG_ SPNConversionMethod : 47|1@1+ (1,0) [0|1] "" Vector__XXX

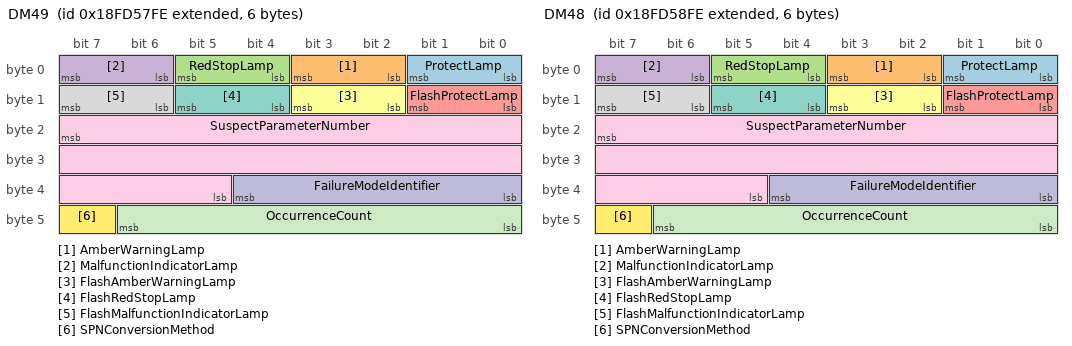
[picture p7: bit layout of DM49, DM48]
BO_ 2566739966 DM49: 6 Vector__XXX
SG_ ProtectLamp : 0|2@1+ (1,0) [0|3] "" Vector__XXX
SG_ AmberWarningLamp : 2|2@1+ (1,0) [0|3] "" Vector__XXX
SG_ RedStopLamp : 4|2@1+ (1,0) [0|3] "" Vector__XXX
SG_ MalfunctionIndicatorLamp : 6|2@1+ (1,0) [0|3] "" Vector__XXX
SG_ FlashProtectLamp : 8|2@1+ (1,0) [0|3] "" Vector__XXX
SG_ FlashAmberWarningLamp : 10|2@1+ (1,0) [0|3] "" Vector__XXX
SG_ FlashRedStopLamp : 12|2@1+ (1,0) [0|3] "" Vector__XXX
SG_ FlashMalfunctionIndicatorLamp : 14|2@1+ (1,0) [0|3] "" Vector__XXX
SG_ SuspectParameterNumber : 23|19@0+ (1,0) [0|524287] "" Vector__XXX
SG_ FailureModeIdentifier : 32|5@1+ (1,0) [0|31] "" Vector__XXX
SG_ OccurrenceCount : 40|7@1+ (1,0) [0|127] "" Vector__XXX
SG_ SPNConversionMethod : 47|1@1+ (1,0) [0|1] "" Vector__XXX

BO_ 2566740222 DM48: 6 Vector__XXX
SG_ ProtectLamp : 0|2@1+ (1,0) [0|3] "" Vector__XXX
SG_ AmberWarningLamp : 2|2@1+ (1,0) [0|3] "" Vector__XXX
SG_ RedStopLamp : 4|2@1+ (1,0) [0|3] "" Vector__XXX
SG_ MalfunctionIndicatorLamp : 6|2@1+ (1,0) [0|3] "" Vector__XXX
SG_ FlashProtectLamp : 8|2@1+ (1,0) [0|3] "" Vector__XXX
SG_ FlashAmberWarningLamp : 10|2@1+ (1,0) [0|3] "" Vector__XXX
SG_ FlashRedStopLamp : 12|2@1+ (1,0) [0|3] "" Vector__XXX
SG_ FlashMalfunctionIndicatorLamp : 14|2@1+ (1,0) [0|3] "" Vector__XXX
SG_ SuspectParameterNumber : 23|19@0+ (1,0) [0|524287] "" Vector__XXX
SG_ FailureModeIdentifier : 32|5@1+ (1,0) [0|31] "" Vector__XXX
SG_ OccurrenceCount : 40|7@1+ (1,0) [0|127] "" Vector__XXX
SG_ SPNConversionMethod : 47|1@1+ (1,0) [0|1] "" Vector__XXX

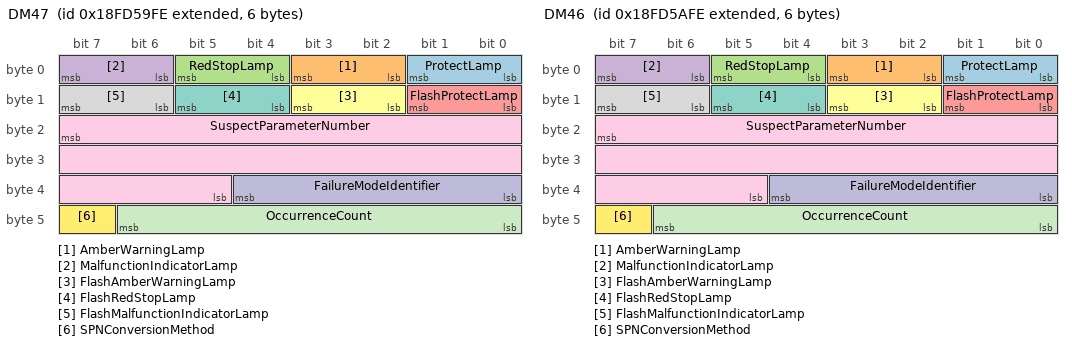
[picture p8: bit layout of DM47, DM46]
BO_ 2566740478 DM47: 6 Vector__XXX
SG_ ProtectLamp : 0|2@1+ (1,0) [0|3] "" Vector__XXX
SG_ AmberWarningLamp : 2|2@1+ (1,0) [0|3] "" Vector__XXX
SG_ RedStopLamp : 4|2@1+ (1,0) [0|3] "" Vector__XXX
SG_ MalfunctionIndicatorLamp : 6|2@1+ (1,0) [0|3] "" Vector__XXX
SG_ FlashProtectLamp : 8|2@1+ (1,0) [0|3] "" Vector__XXX
SG_ FlashAmberWarningLamp : 10|2@1+ (1,0) [0|3] "" Vector__XXX
SG_ FlashRedStopLamp : 12|2@1+ (1,0) [0|3] "" Vector__XXX
SG_ FlashMalfunctionIndicatorLamp : 14|2@1+ (1,0) [0|3] "" Vector__XXX
SG_ SuspectParameterNumber : 23|19@0+ (1,0) [0|524287] "" Vector__XXX
SG_ FailureModeIdentifier : 32|5@1+ (1,0) [0|31] "" Vector__XXX
SG_ OccurrenceCount : 40|7@1+ (1,0) [0|127] "" Vector__XXX
SG_ SPNConversionMethod : 47|1@1+ (1,0) [0|1] "" Vector__XXX

BO_ 2566740734 DM46: 6 Vector__XXX
SG_ ProtectLamp : 0|2@1+ (1,0) [0|3] "" Vector__XXX
SG_ AmberWarningLamp : 2|2@1+ (1,0) [0|3] "" Vector__XXX
SG_ RedStopLamp : 4|2@1+ (1,0) [0|3] "" Vector__XXX
SG_ MalfunctionIndicatorLamp : 6|2@1+ (1,0) [0|3] "" Vector__XXX
SG_ FlashProtectLamp : 8|2@1+ (1,0) [0|3] "" Vector__XXX
SG_ FlashAmberWarningLamp : 10|2@1+ (1,0) [0|3] "" Vector__XXX
SG_ FlashRedStopLamp : 12|2@1+ (1,0) [0|3] "" Vector__XXX
SG_ FlashMalfunctionIndicatorLamp : 14|2@1+ (1,0) [0|3] "" Vector__XXX
SG_ SuspectParameterNumber : 23|19@0+ (1,0) [0|524287] "" Vector__XXX
SG_ FailureModeIdentifier : 32|5@1+ (1,0) [0|31] "" Vector__XXX
SG_ OccurrenceCount : 40|7@1+ (1,0) [0|127] "" Vector__XXX
SG_ SPNConversionMethod : 47|1@1+ (1,0) [0|1] "" Vector__XXX

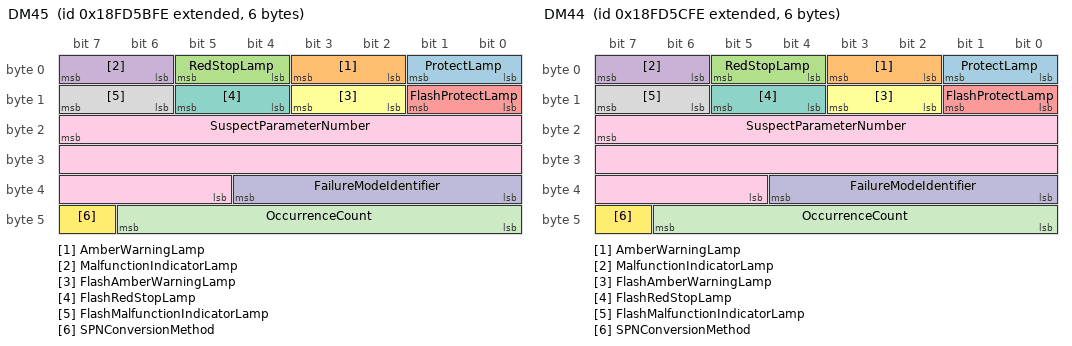
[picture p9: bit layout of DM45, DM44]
BO_ 2566740990 DM45: 6 Vector__XXX
SG_ ProtectLamp : 0|2@1+ (1,0) [0|3] "" Vector__XXX
SG_ AmberWarningLamp : 2|2@1+ (1,0) [0|3] "" Vector__XXX
SG_ RedStopLamp : 4|2@1+ (1,0) [0|3] "" Vector__XXX
SG_ MalfunctionIndicatorLamp : 6|2@1+ (1,0) [0|3] "" Vector__XXX
SG_ FlashProtectLamp : 8|2@1+ (1,0) [0|3] "" Vector__XXX
SG_ FlashAmberWarningLamp : 10|2@1+ (1,0) [0|3] "" Vector__XXX
SG_ FlashRedStopLamp : 12|2@1+ (1,0) [0|3] "" Vector__XXX
SG_ FlashMalfunctionIndicatorLamp : 14|2@1+ (1,0) [0|3] "" Vector__XXX
SG_ SuspectParameterNumber : 23|19@0+ (1,0) [0|524287] "" Vector__XXX
SG_ FailureModeIdentifier : 32|5@1+ (1,0) [0|31] "" Vector__XXX
SG_ OccurrenceCount : 40|7@1+ (1,0) [0|127] "" Vector__XXX
SG_ SPNConversionMethod : 47|1@1+ (1,0) [0|1] "" Vector__XXX

BO_ 2566741246 DM44: 6 Vector__XXX
SG_ ProtectLamp : 0|2@1+ (1,0) [0|3] "" Vector__XXX
SG_ AmberWarningLamp : 2|2@1+ (1,0) [0|3] "" Vector__XXX
SG_ RedStopLamp : 4|2@1+ (1,0) [0|3] "" Vector__XXX
SG_ MalfunctionIndicatorLamp : 6|2@1+ (1,0) [0|3] "" Vector__XXX
SG_ FlashProtectLamp : 8|2@1+ (1,0) [0|3] "" Vector__XXX
SG_ FlashAmberWarningLamp : 10|2@1+ (1,0) [0|3] "" Vector__XXX
SG_ FlashRedStopLamp : 12|2@1+ (1,0) [0|3] "" Vector__XXX
SG_ FlashMalfunctionIndicatorLamp : 14|2@1+ (1,0) [0|3] "" Vector__XXX
SG_ SuspectParameterNumber : 23|19@0+ (1,0) [0|524287] "" Vector__XXX
SG_ FailureModeIdentifier : 32|5@1+ (1,0) [0|31] "" Vector__XXX
SG_ OccurrenceCount : 40|7@1+ (1,0) [0|127] "" Vector__XXX
SG_ SPNConversionMethod : 47|1@1+ (1,0) [0|1] "" Vector__XXX

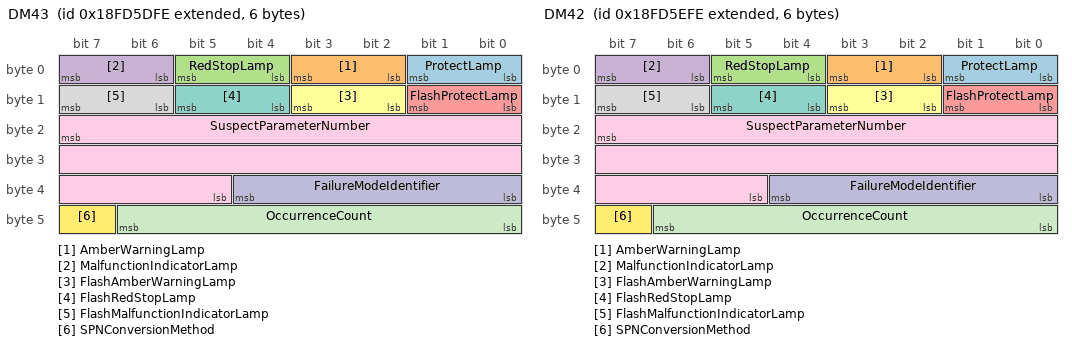
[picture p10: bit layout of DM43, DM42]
BO_ 2566741502 DM43: 6 Vector__XXX
SG_ ProtectLamp : 0|2@1+ (1,0) [0|3] "" Vector__XXX
SG_ AmberWarningLamp : 2|2@1+ (1,0) [0|3] "" Vector__XXX
SG_ RedStopLamp : 4|2@1+ (1,0) [0|3] "" Vector__XXX
SG_ MalfunctionIndicatorLamp : 6|2@1+ (1,0) [0|3] "" Vector__XXX
SG_ FlashProtectLamp : 8|2@1+ (1,0) [0|3] "" Vector__XXX
SG_ FlashAmberWarningLamp : 10|2@1+ (1,0) [0|3] "" Vector__XXX
SG_ FlashRedStopLamp : 12|2@1+ (1,0) [0|3] "" Vector__XXX
SG_ FlashMalfunctionIndicatorLamp : 14|2@1+ (1,0) [0|3] "" Vector__XXX
SG_ SuspectParameterNumber : 23|19@0+ (1,0) [0|524287] "" Vector__XXX
SG_ FailureModeIdentifier : 32|5@1+ (1,0) [0|31] "" Vector__XXX
SG_ OccurrenceCount : 40|7@1+ (1,0) [0|127] "" Vector__XXX
SG_ SPNConversionMethod : 47|1@1+ (1,0) [0|1] "" Vector__XXX

BO_ 2566741758 DM42: 6 Vector__XXX
SG_ ProtectLamp : 0|2@1+ (1,0) [0|3] "" Vector__XXX
SG_ AmberWarningLamp : 2|2@1+ (1,0) [0|3] "" Vector__XXX
SG_ RedStopLamp : 4|2@1+ (1,0) [0|3] "" Vector__XXX
SG_ MalfunctionIndicatorLamp : 6|2@1+ (1,0) [0|3] "" Vector__XXX
SG_ FlashProtectLamp : 8|2@1+ (1,0) [0|3] "" Vector__XXX
SG_ FlashAmberWarningLamp : 10|2@1+ (1,0) [0|3] "" Vector__XXX
SG_ FlashRedStopLamp : 12|2@1+ (1,0) [0|3] "" Vector__XXX
SG_ FlashMalfunctionIndicatorLamp : 14|2@1+ (1,0) [0|3] "" Vector__XXX
SG_ SuspectParameterNumber : 23|19@0+ (1,0) [0|524287] "" Vector__XXX
SG_ FailureModeIdentifier : 32|5@1+ (1,0) [0|31] "" Vector__XXX
SG_ OccurrenceCount : 40|7@1+ (1,0) [0|127] "" Vector__XXX
SG_ SPNConversionMethod : 47|1@1+ (1,0) [0|1] "" Vector__XXX

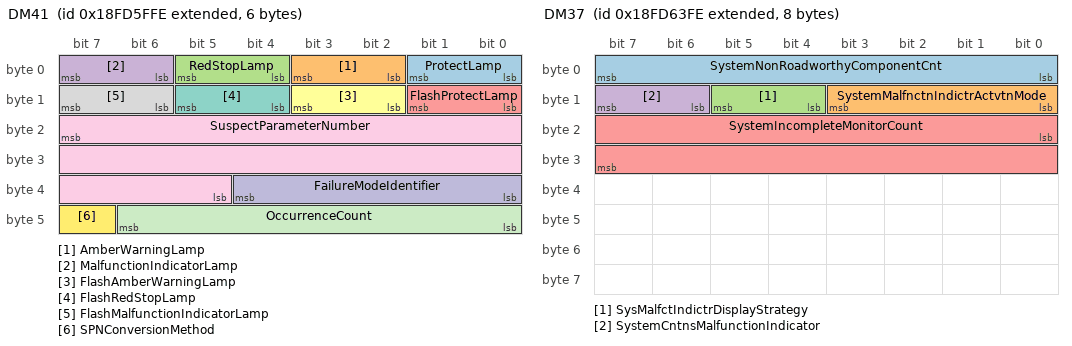
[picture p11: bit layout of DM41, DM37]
BO_ 2566742014 DM41: 6 Vector__XXX
SG_ ProtectLamp : 0|2@1+ (1,0) [0|3] "" Vector__XXX
SG_ AmberWarningLamp : 2|2@1+ (1,0) [0|3] "" Vector__XXX
SG_ RedStopLamp : 4|2@1+ (1,0) [0|3] "" Vector__XXX
SG_ MalfunctionIndicatorLamp : 6|2@1+ (1,0) [0|3] "" Vector__XXX
SG_ FlashProtectLamp : 8|2@1+ (1,0) [0|3] "" Vector__XXX
SG_ FlashAmberWarningLamp : 10|2@1+ (1,0) [0|3] "" Vector__XXX
SG_ FlashRedStopLamp : 12|2@1+ (1,0) [0|3] "" Vector__XXX
SG_ FlashMalfunctionIndicatorLamp : 14|2@1+ (1,0) [0|3] "" Vector__XXX
SG_ SuspectParameterNumber : 23|19@0+ (1,0) [0|524287] "" Vector__XXX
SG_ FailureModeIdentifier : 32|5@1+ (1,0) [0|31] "" Vector__XXX
SG_ OccurrenceCount : 40|7@1+ (1,0) [0|127] "" Vector__XXX
SG_ SPNConversionMethod : 47|1@1+ (1,0) [0|1] "" Vector__XXX

BO_ 2566742270 DM40: 8 Vector__XXX
SG_ SuspectParameterNumber : 7|19@0+ (1,0) [0|524287] "" Vector__XXX
SG_ FailureModeIdentifier : 16|5@1+ (1,0) [0|31] "" Vector__XXX
SG_ FailureSpecificB1Counter : 24|16@1+ (0.1,0) [0|6425.5] "h" Vector__XXX

BO_ 2566742526 DM39: 8 Vector__XXX
SG_ SystemCumulativeContinuousMITime : 0|32@1+ (0.05,0) [0|210554060.75] "h" Vector__XXX
SG_ SystemGreatestB1Counter : 32|16@1+ (0.1,0) [0|6425.5] "h" Vector__XXX

BO_ 2566742782 DM38: 25 Vector__XXX
SG_ GloblTechnicalRegulationDescript : 7|200@0+ (1,0) [0|0] "" Vector__XXX

BO_ 2566743038 DM37: 8 Vector__XXX
SG_ SystemNonRoadworthyComponentCnt : 0|8@1+ (1,0) [0|250] "" Vector__XXX
SG_ SystemMalfnctnIndictrActvtnMode : 8|4@1+ (1,0) [0|15] "" Vector__XXX
SG_ SysMalfctIndictrDisplayStrategy : 12|2@1+ (1,0) [0|3] "" Vector__XXX
SG_ SystemCntnsMalfunctionIndicator : 14|2@1+ (1,0) [0|3] "" Vector__XXX
SG_ SystemIncompleteMonitorCount : 16|16@1+ (1,0) [0|64255] "" Vector__XXX

BO_ 2566743294 DM36: 8 Vector__XXX
SG_ VehicleCurrentMIAccumulatedTime : 32|16@1+ (1,0) [0|64255] "min" Vector__XXX

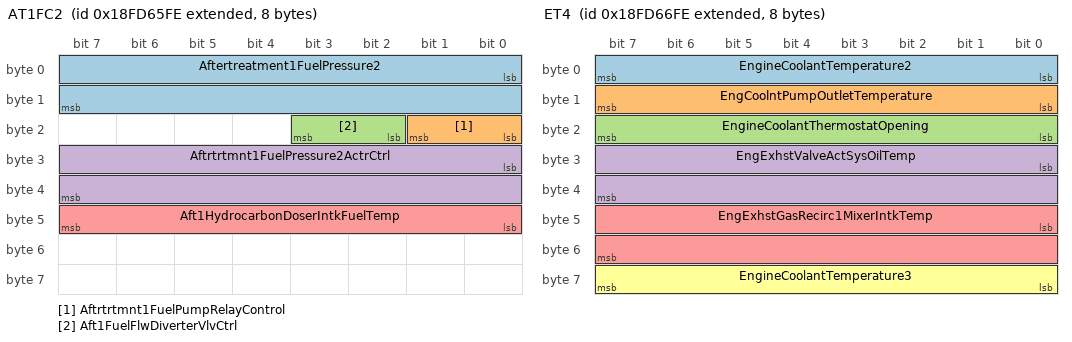
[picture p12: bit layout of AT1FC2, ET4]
BO_ 2566743550 AT1FC2: 8 Vector__XXX
SG_ Aftertreatment1FuelPressure2 : 0|16@1+ (0.1,0) [0|6425.5] "kPa" Vector__XXX
SG_ Aftrtrtmnt1FuelPumpRelayControl : 16|2@1+ (1,0) [0|3] "" Vector__XXX
SG_ Aft1FuelFlwDiverterVlvCtrl : 18|2@1+ (1,0) [0|3] "" Vector__XXX
SG_ Aftrtrtmnt1FuelPressure2ActrCtrl : 24|16@1+ (0.0025,0) [0|160.6375] "%" Vector__XXX
SG_ Aft1HydrocarbonDoserIntkFuelTemp : 40|8@1+ (1,-40) [-40|210] "deg C" Vector__XXX

BO_ 2566743806 ET4: 8 Vector__XXX
SG_ EngineCoolantTemperature2 : 0|8@1+ (1,-40) [-40|210] "deg C" Vector__XXX
SG_ EngCoolntPumpOutletTemperature : 8|8@1+ (1,-40) [-40|210] "deg C" Vector__XXX
SG_ EngineCoolantThermostatOpening : 16|8@1+ (0.4,0) [0|100] "%" Vector__XXX
SG_ EngExhstValveActSysOilTemp : 24|16@1+ (0.03125,-273) [-273|1734.96875] "deg C" Vector__XXX
SG_ EngExhstGasRecirc1MixerIntkTemp : 40|16@1+ (0.03125,-273) [-273|1734.96875] "deg C" Vector__XXX
SG_ EngineCoolantTemperature3 : 56|8@1+ (1,-40) [-40|210] "deg C" Vector__XXX

BO_ 2566744062 ZNVW: 8 Vector__XXX
SG_ ZeroNetVehicleWeightChange : 0|2@1+ (1,0) [0|3] "" Vector__XXX

BO_ 2499635454 GCVW: 8 Vector__XXX
SG_ GrossCombinationWeight : 0|24@1+ (2,0) [0|32899070] "kg" Vector__XXX
SG_ NetVehicleWeightChange : 24|24@1+ (2,-16449535) [-16449535|16449535] "kg" Vector__XXX

BO_ 2633853438 AGCW: 8 Vector__XXX
SG_ AxleGroupLocation : 0|4@1+ (1,0) [0|15] "" Vector__XXX
SG_ AdditionalAxleGroupLocation : 4|4@1+ (1,0) [0|15] "" Vector__XXX
SG_ AxleGroupEmptyWeightCalibration : 8|16@1+ (2,0) [0|128510] "kg" Vector__XXX
SG_ AxleGroupFullWeightCalibration : 24|16@1+ (2,0) [0|128510] "kg" Vector__XXX

BO_ 2499635966 AGW: 8 Vector__XXX
SG_ AxleGroupLocation : 0|4@1+ (1,0) [0|15] "" Vector__XXX
SG_ AdditionalAxleGroupLocation : 4|4@1+ (1,0) [0|15] "" Vector__XXX
SG_ AxleGroupWeight : 8|16@1+ (2,0) [0|128510] "kg" Vector__XXX

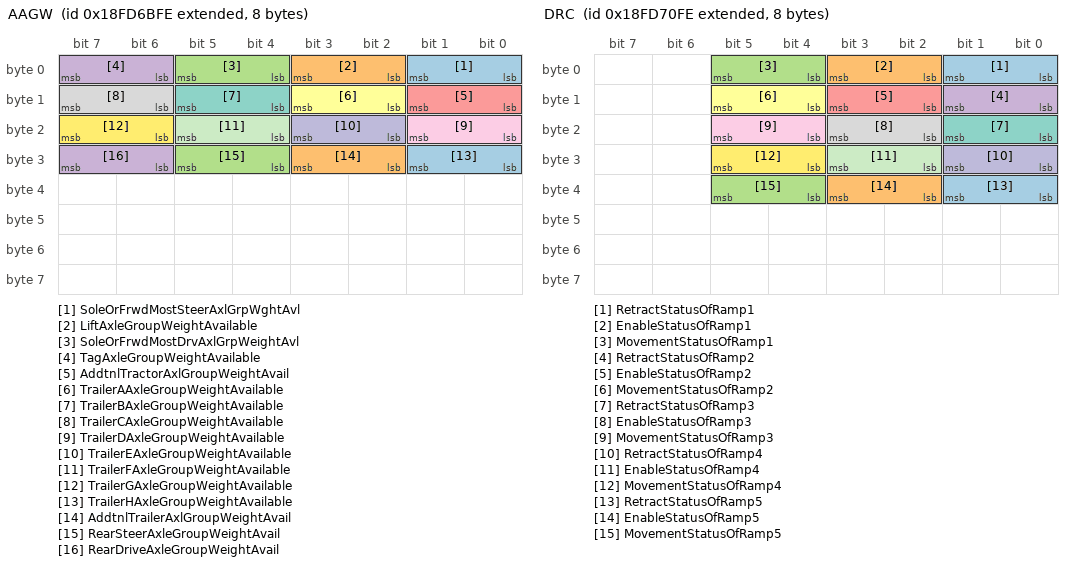
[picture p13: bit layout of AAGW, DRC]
BO_ 2566745086 AAGW: 8 Vector__XXX
SG_ SoleOrFrwdMostSteerAxlGrpWghtAvl : 0|2@1+ (1,0) [0|3] "" Vector__XXX
SG_ LiftAxleGroupWeightAvailable : 2|2@1+ (1,0) [0|3] "" Vector__XXX
SG_ SoleOrFrwdMostDrvAxlGrpWeightAvl : 4|2@1+ (1,0) [0|3] "" Vector__XXX
SG_ TagAxleGroupWeightAvailable : 6|2@1+ (1,0) [0|3] "" Vector__XXX
SG_ AddtnlTractorAxlGroupWeightAvail : 8|2@1+ (1,0) [0|3] "" Vector__XXX
SG_ TrailerAAxleGroupWeightAvailable : 10|2@1+ (1,0) [0|3] "" Vector__XXX
SG_ TrailerBAxleGroupWeightAvailable : 12|2@1+ (1,0) [0|3] "" Vector__XXX
SG_ TrailerCAxleGroupWeightAvailable : 14|2@1+ (1,0) [0|3] "" Vector__XXX
SG_ TrailerDAxleGroupWeightAvailable : 16|2@1+ (1,0) [0|3] "" Vector__XXX
SG_ TrailerEAxleGroupWeightAvailable : 18|2@1+ (1,0) [0|3] "" Vector__XXX
SG_ TrailerFAxleGroupWeightAvailable : 20|2@1+ (1,0) [0|3] "" Vector__XXX
SG_ TrailerGAxleGroupWeightAvailable : 22|2@1+ (1,0) [0|3] "" Vector__XXX
SG_ TrailerHAxleGroupWeightAvailable : 24|2@1+ (1,0) [0|3] "" Vector__XXX
SG_ AddtnlTrailerAxlGroupWeightAvail : 26|2@1+ (1,0) [0|3] "" Vector__XXX
SG_ RearSteerAxleGroupWeightAvail : 28|2@1+ (1,0) [0|3] "" Vector__XXX
SG_ RearDriveAxleGroupWeightAvail : 30|2@1+ (1,0) [0|3] "" Vector__XXX

BO_ 2566745342 AT2AC2: 8 Vector__XXX
SG_ Aftrtrtmnt2SecondaryAirDiffPress : 0|16@1+ (0.0078125,-250) [-250|251.99] "kPa" Vector__XXX
SG_ Aftrtrtmnt2SecAirTemperature : 16|16@1+ (0.03125,-273) [-273|1734.96875] "deg C" Vector__XXX
SG_ Aftrtrtmnt2SecAirMassFlwRate : 32|16@1+ (0.2,0) [0|12851] "kg/h" Vector__XXX
SG_ Aftrtrtmnt2SecondaryAirPressure : 48|16@1+ (0.1,0) [0|6425.5] "kPa" Vector__XXX

BO_ 2566745598 AT1AC2: 8 Vector__XXX
SG_ Aftrtrtmnt1SecondaryAirDiffPress : 0|16@1+ (0.0078125,-250) [-250|251.99] "kPa" Vector__XXX
SG_ Aftrtrtmnt1SecAirTemperature : 16|16@1+ (0.03125,-273) [-273|1734.96875] "deg C" Vector__XXX
SG_ Aftrtrtmnt1SecAirMassFlwRate : 32|16@1+ (0.2,0) [0|12851] "kg/h" Vector__XXX
SG_ Aftrtrtmnt1SecondaryAirPressure : 48|16@1+ (0.1,0) [0|6425.5] "kPa" Vector__XXX

BO_ 2566745854 A1SCRSI1: 8 Vector__XXX
SG_ Aft1DslExhstFldAvrgCnsmptn : 0|16@1+ (0.05,0) [0|3212.75] "l/h" Vector__XXX
SG_ Aft1SCRCmdedDslExhstFldCnsmptn : 16|16@1+ (0.05,0) [0|3212.75] "l/h" Vector__XXX
SG_ Aftrtrtmnt1SCRCnvrsnEfficiency : 32|8@1+ (0.4,0) [0|100] "%" Vector__XXX
SG_ AftSCROprtrIndcmntActvTrvledDist : 40|16@1+ (1,0) [0|64255] "km" Vector__XXX
SG_ Aftrtrtmnt1SCRSystemSulfationLvl : 56|8@1+ (1,0) [0|250] "%" Vector__XXX

BO_ 2566746110 EEC8: 8 Vector__XXX
SG_ EngExhstGasRecirc1Valve2Ctrl : 0|16@1+ (0.0025,0) [0|160.6375] "%" Vector__XXX
SG_ EngExhstGasRecirc1CoolIntkTemp : 16|16@1+ (0.03125,-273) [-273|1734.96875] "deg C" Vector__XXX
SG_ EngExhstGasRecirc1ClIntkAbsPress : 32|16@1+ (0.5,0) [0|32127.5] "kPa" Vector__XXX
SG_ EngExhstGasRecirculation1CoolEff : 48|8@1+ (0.4,0) [0|100] "%" Vector__XXX

BO_ 2566746366 DRC: 8 Vector__XXX
SG_ RetractStatusOfRamp1 : 0|2@1+ (1,0) [0|3] "" Vector__XXX
SG_ EnableStatusOfRamp1 : 2|2@1+ (1,0) [0|3] "" Vector__XXX
SG_ MovementStatusOfRamp1 : 4|2@1+ (1,0) [0|3] "" Vector__XXX
SG_ RetractStatusOfRamp2 : 8|2@1+ (1,0) [0|3] "" Vector__XXX
SG_ EnableStatusOfRamp2 : 10|2@1+ (1,0) [0|3] "" Vector__XXX
SG_ MovementStatusOfRamp2 : 12|2@1+ (1,0) [0|3] "" Vector__XXX
SG_ RetractStatusOfRamp3 : 16|2@1+ (1,0) [0|3] "" Vector__XXX
SG_ EnableStatusOfRamp3 : 18|2@1+ (1,0) [0|3] "" Vector__XXX
SG_ MovementStatusOfRamp3 : 20|2@1+ (1,0) [0|3] "" Vector__XXX
SG_ RetractStatusOfRamp4 : 24|2@1+ (1,0) [0|3] "" Vector__XXX
SG_ EnableStatusOfRamp4 : 26|2@1+ (1,0) [0|3] "" Vector__XXX
SG_ MovementStatusOfRamp4 : 28|2@1+ (1,0) [0|3] "" Vector__XXX
SG_ RetractStatusOfRamp5 : 32|2@1+ (1,0) [0|3] "" Vector__XXX
SG_ EnableStatusOfRamp5 : 34|2@1+ (1,0) [0|3] "" Vector__XXX
SG_ MovementStatusOfRamp5 : 36|2@1+ (1,0) [0|3] "" Vector__XXX

BO_ 2566746622 BSA: 8 Vector__XXX
SG_ TractorBrakeStrokeAxle1Left : 0|3@1+ (1,0) [0|7] "" Vector__XXX
SG_ TractorBrakeStrokeAxle1Right : 3|3@1+ (1,0) [0|7] "" Vector__XXX
SG_ TractorBrakeStrokeAxle2Left : 6|3@1+ (1,0) [0|7] "" Vector__XXX
SG_ TractorBrakeStrokeAxle2Right : 9|3@1+ (1,0) [0|7] "" Vector__XXX
SG_ TractorBrakeStrokeAxle3Left : 12|3@1+ (1,0) [0|7] "" Vector__XXX
SG_ TractorBrakeStrokeAxle3Right : 15|3@1+ (1,0) [0|7] "" Vector__XXX
SG_ TractorBrakeStrokeAxle4Left : 18|3@1+ (1,0) [0|7] "" Vector__XXX
SG_ TractorBrakeStrokeAxle4Right : 21|3@1+ (1,0) [0|7] "" Vector__XXX
SG_ TractorBrakeStrokeAxle5Left : 24|3@1+ (1,0) [0|7] "" Vector__XXX
SG_ TractorBrakeStrokeAxle5Right : 27|3@1+ (1,0) [0|7] "" Vector__XXX
SG_ TrailerBrakeStrokeAxle1Left : 30|3@1+ (1,0) [0|7] "" Vector__XXX
SG_ TrailerBrakeStrokeAxle1Right : 33|3@1+ (1,0) [0|7] "" Vector__XXX
SG_ TrailerBrakeStrokeAxle2Left : 36|3@1+ (1,0) [0|7] "" Vector__XXX
SG_ TrailerBrakeStrokeAxle2Right : 39|3@1+ (1,0) [0|7] "" Vector__XXX
SG_ TrailerBrakeStrokeAxle3Left : 42|3@1+ (1,0) [0|7] "" Vector__XXX
SG_ TrailerBrakeStrokeAxle3Right : 45|3@1+ (1,0) [0|7] "" Vector__XXX
SG_ TrailerBrakeStrokeAxle4Left : 48|3@1+ (1,0) [0|7] "" Vector__XXX
SG_ TrailerBrakeStrokeAxle4Right : 51|3@1+ (1,0) [0|7] "" Vector__XXX
SG_ TrailerBrakeStrokeAxle5Left : 54|3@1+ (1,0) [0|7] "" Vector__XXX
SG_ TrailerBrakeStrokeAxle5Right : 57|3@1+ (1,0) [0|7] "" Vector__XXX

BO_ 2566746878 ESV6: 8 Vector__XXX
SG_ EngineSparkPlug21 : 0|16@1+ (1,0) [0|64255] "V" Vector__XXX
SG_ EngineSparkPlug22 : 16|16@1+ (1,0) [0|64255] "V" Vector__XXX
SG_ EngineSparkPlug23 : 32|16@1+ (1,0) [0|64255] "V" Vector__XXX
SG_ EngineSparkPlug24 : 48|16@1+ (1,0) [0|64255] "V" Vector__XXX

BO_ 2566747134 ESV5: 8 Vector__XXX
SG_ EngineSparkPlug17 : 0|16@1+ (1,0) [0|64255] "V" Vector__XXX
SG_ EngineSparkPlug18 : 16|16@1+ (1,0) [0|64255] "V" Vector__XXX
SG_ EngineSparkPlug19 : 32|16@1+ (1,0) [0|64255] "V" Vector__XXX
SG_ EngineSparkPlug20 : 48|16@1+ (1,0) [0|64255] "V" Vector__XXX

BO_ 2566747390 ESV4: 8 Vector__XXX
SG_ EngineSparkPlug13 : 0|16@1+ (1,0) [0|64255] "V" Vector__XXX
SG_ EngineSparkPlug14 : 16|16@1+ (1,0) [0|64255] "V" Vector__XXX
SG_ EngineSparkPlug15 : 32|16@1+ (1,0) [0|64255] "V" Vector__XXX
SG_ EngineSparkPlug16 : 48|16@1+ (1,0) [0|64255] "V" Vector__XXX

BO_ 2566747646 ESV3: 8 Vector__XXX
SG_ EngineSparkPlug9 : 0|16@1+ (1,0) [0|64255] "V" Vector__XXX
SG_ EngineSparkPlug10 : 16|16@1+ (1,0) [0|64255] "V" Vector__XXX
SG_ EngineSparkPlug11 : 32|16@1+ (1,0) [0|64255] "V" Vector__XXX
SG_ EngineSparkPlug12 : 48|16@1+ (1,0) [0|64255] "V" Vector__XXX

BO_ 2566747902 ESV2: 8 Vector__XXX
SG_ EngineSparkPlug5 : 0|16@1+ (1,0) [0|64255] "V" Vector__XXX
SG_ EngineSparkPlug6 : 16|16@1+ (1,0) [0|64255] "V" Vector__XXX
SG_ EngineSparkPlug7 : 32|16@1+ (1,0) [0|64255] "V" Vector__XXX
SG_ EngineSparkPlug8 : 48|16@1+ (1,0) [0|64255] "V" Vector__XXX

BO_ 2566748158 ESV1: 8 Vector__XXX
SG_ EngineSparkPlug1 : 0|16@1+ (1,0) [0|64255] "V" Vector__XXX
SG_ EngineSparkPlug2 : 16|16@1+ (1,0) [0|64255] "V" Vector__XXX
SG_ EngineSparkPlug3 : 32|16@1+ (1,0) [0|64255] "V" Vector__XXX
SG_ EngineSparkPlug4 : 48|16@1+ (1,0) [0|64255] "V" Vector__XXX

BO_ 2566748414 AT2TI: 32 Vector__XXX
SG_ Aftrtrtmnt2DslPFTripFuelUsed : 0|32@1+ (0.5,0) [0|2105540607.5] "l" Vector__XXX
SG_ Aftrtrtmnt2DslPFTripActvRegenTme : 32|32@1+ (1,0) [0|4211081215] "s" Vector__XXX
SG_ Aftrtrtmnt2DslPFTripDisabledTime : 64|32@1+ (1,0) [0|4211081215] "s" Vector__XXX
SG_ Aft2DslPFTrpNoOfActvRegens : 96|32@1+ (1,0) [0|4211081215] "" Vector__XXX
SG_ Aft2DslPFTrpPassiveRegenTme : 128|32@1+ (1,0) [0|4211081215] "s" Vector__XXX
SG_ Aft2DslPFTrpNoOfPassiveRegens : 160|32@1+ (1,0) [0|4211081215] "" Vector__XXX
SG_ Aft2DslPFTrpNoOfActRegenInhbtRqs : 192|32@1+ (1,0) [0|4211081215] "" Vector__XXX
SG_ Aft2DslPFTrpNoOfActvRegenManRqs : 224|32@1+ (1,0) [0|4211081215] "" Vector__XXX

BO_ 2566748670 AT1TI: 32 Vector__XXX
SG_ Aftrtrtmnt1DslPFTripFuelUsed : 0|32@1+ (0.5,0) [0|2105540607.5] "l" Vector__XXX
SG_ Aftrtrtmnt1DslPFTripActvRegenTme : 32|32@1+ (1,0) [0|4211081215] "s" Vector__XXX
SG_ Aftrtrtmnt1DslPFTripDisabledTime : 64|32@1+ (1,0) [0|4211081215] "s" Vector__XXX
SG_ Aft1DslPFTrpNoOfActvRegens : 96|32@1+ (1,0) [0|4211081215] "" Vector__XXX
SG_ Aft1DslPFTrpPassiveRegenTme : 128|32@1+ (1,0) [0|4211081215] "s" Vector__XXX
SG_ Aft1DslPFTrpNoOfPassiveRegens : 160|32@1+ (1,0) [0|4211081215] "" Vector__XXX
SG_ Aft1DslPFTrpNoOfActRegenInhbtRqs : 192|32@1+ (1,0) [0|4211081215] "" Vector__XXX
SG_ Aft1DslPFTrpNoOfActvRegenManRqs : 224|32@1+ (1,0) [0|4211081215] "" Vector__XXX

BO_ 2566748926 AT2S1: 8 Vector__XXX
SG_ Aftrtrtmnt2DslPFSootLoadPercent : 0|8@1+ (1,0) [0|250] "%" Vector__XXX
SG_ Aftrtrtmnt2DslPFAshLoadPercent : 8|8@1+ (1,0) [0|250] "%" Vector__XXX
SG_ Aft2DslPFTmeSncLastActvRegen : 16|32@1+ (1,0) [0|4211081215] "s" Vector__XXX
SG_ Aft2DslPFSootLoadRegenTrshld : 48|16@1+ (0.0025,0) [0|160.6375] "%" Vector__XXX

BO_ 2566749182 AT1S1: 8 Vector__XXX
SG_ Aftrtrtmnt1DslPFSootLoadPercent : 0|8@1+ (1,0) [0|250] "%" Vector__XXX
SG_ Aftrtrtmnt1DslPFAshLoadPercent : 8|8@1+ (1,0) [0|250] "%" Vector__XXX
SG_ Aft1DslPFTmeSncLastActvRegen : 16|32@1+ (1,0) [0|4211081215] "s" Vector__XXX
SG_ Aft1DslPFSootLoadRegenTrshld : 48|16@1+ (0.0025,0) [0|160.6375] "%" Vector__XXX

BO_ 2566749438 DPFC1: 8 Vector__XXX
SG_ DieselParticulateFilterLampCmd : 0|3@1+ (1,0) [0|7] "" Vector__XXX
SG_ DslPFActvRegenAvailabilityStatus : 3|2@1+ (1,0) [0|3] "" Vector__XXX
SG_ AftrtrtmntDslPFPassiveRegenStat : 8|2@1+ (1,0) [0|3] "" Vector__XXX
SG_ AftrtrtmntDslPFActvRegenStatus : 10|2@1+ (1,0) [0|3] "" Vector__XXX
SG_ AftrtrtmntDslPFStatus : 12|3@1+ (1,0) [0|7] "" Vector__XXX
SG_ DslPFActvRegenInhbtdStatus : 16|2@1+ (1,0) [0|3] "" Vector__XXX
SG_ DslPFActvRegenInhbtdDTInhbtSw : 18|2@1+ (1,0) [0|3] "" Vector__XXX
SG_ DslPFActRegenInhbtdDTCltchDiseng : 20|2@1+ (1,0) [0|3] "" Vector__XXX
SG_ DslPFActRegenInhbtdDTSrvcBrkActv : 22|2@1+ (1,0) [0|3] "" Vector__XXX
SG_ DslPFActvRegenInhbtdDTPTOActv : 24|2@1+ (1,0) [0|3] "" Vector__XXX
SG_ DPFActRegenInhbtdDTAcclPdlOffIdl : 26|2@1+ (1,0) [0|3] "" Vector__XXX
SG_ DslPFActvRegenInhbtdDTOutOfNtrl : 28|2@1+ (1,0) [0|3] "" Vector__XXX
SG_ DPFActRegInhDTVhclSpdAbvAllwdSpd : 30|2@1+ (1,0) [0|3] "" Vector__XXX
SG_ DPFActRegenInhbtdDTPrkBrkNotSet : 32|2@1+ (1,0) [0|3] "" Vector__XXX
SG_ DPFActRegenInhbtdDTLowExhstTemp : 34|2@1+ (1,0) [0|3] "" Vector__XXX
SG_ DslPFActRegenInhbtdDTSysFaultAct : 36|2@1+ (1,0) [0|3] "" Vector__XXX
SG_ DslPFActvRegenInhbtdDTSysTimeout : 38|2@1+ (1,0) [0|3] "" Vector__XXX
SG_ DPFActRegenInhbtdDTTmprySysLckt : 40|2@1+ (1,0) [0|3] "" Vector__XXX
SG_ DPFActRegenInhbtdDTPrmntSysLckt : 42|2@1+ (1,0) [0|3] "" Vector__XXX
SG_ DPFActRegInhbtdDTEngNotWarmedUp : 44|2@1+ (1,0) [0|3] "" Vector__XXX
SG_ DPFActRegInhDTVhclSpdBlwAllwdSpd : 46|2@1+ (1,0) [0|3] "" Vector__XXX
SG_ DslPFAutoActvRegenInitConf : 48|2@1+ (1,0) [0|3] "" Vector__XXX
SG_ ExhstSystemHghTemperatureLampCmd : 50|3@1+ (1,0) [0|7] "" Vector__XXX
SG_ DslPFActvRegenForcedStatus : 53|3@1+ (1,0) [0|7] "" Vector__XXX
SG_ HydrocarbonDoserPurgingEnable : 56|2@1+ (1,0) [0|3] "" Vector__XXX
SG_ DPFActRegenInhbtdDTLowExhstPress : 58|2@1+ (1,0) [0|3] "" Vector__XXX
SG_ Aft1DPFConditionsNotMetForActReg : 60|2@1+ (1,0) [0|3] "" Vector__XXX

BO_ 2566749694 FMS1: 0 Vector__XXX

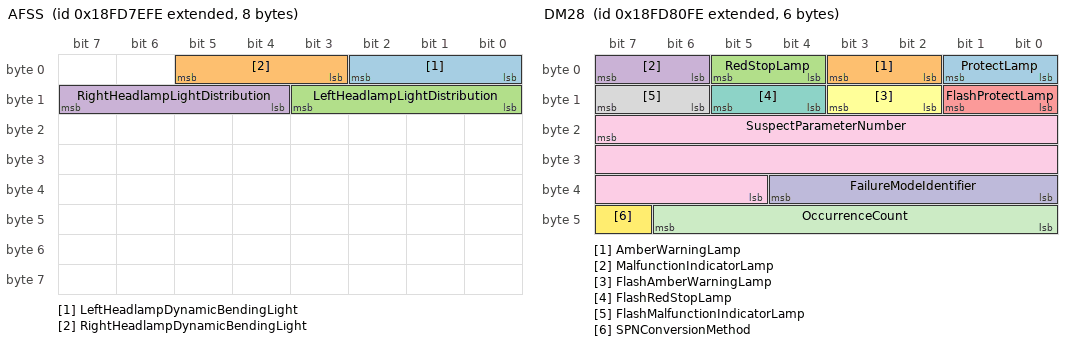
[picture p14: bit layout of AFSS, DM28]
BO_ 2566749950 AFSS: 8 Vector__XXX
SG_ LeftHeadlampDynamicBendingLight : 0|3@1+ (1,0) [0|7] "" Vector__XXX
SG_ RightHeadlampDynamicBendingLight : 3|3@1+ (1,0) [0|7] "" Vector__XXX
SG_ LeftHeadlampLightDistribution : 8|4@1+ (1,0) [0|15] "" Vector__XXX
SG_ RightHeadlampLightDistribution : 12|4@1+ (1,0) [0|15] "" Vector__XXX

BO_ 2566750206 EC2: 8 Vector__XXX
SG_ MaxCrankAttmptsPerStartAttmpt : 0|8@1+ (1,0) [0|250] "" Vector__XXX
SG_ NoOfCombustionCyclesForAveraging : 8|8@1+ (1,0) [0|250] "" Vector__XXX
SG_ EngineConfIdentification : 16|16@1+ (1,0) [0|64255] "" Vector__XXX
SG_ TrnsmIdlGvrnrFuelngInhbtSupp : 32|2@1+ (1,0) [0|3] "" Vector__XXX

BO_ 2566750462 DM28: 6 Vector__XXX
SG_ ProtectLamp : 0|2@1+ (1,0) [0|3] "" Vector__XXX
SG_ AmberWarningLamp : 2|2@1+ (1,0) [0|3] "" Vector__XXX
SG_ RedStopLamp : 4|2@1+ (1,0) [0|3] "" Vector__XXX
SG_ MalfunctionIndicatorLamp : 6|2@1+ (1,0) [0|3] "" Vector__XXX
SG_ FlashProtectLamp : 8|2@1+ (1,0) [0|3] "" Vector__XXX
SG_ FlashAmberWarningLamp : 10|2@1+ (1,0) [0|3] "" Vector__XXX
SG_ FlashRedStopLamp : 12|2@1+ (1,0) [0|3] "" Vector__XXX
SG_ FlashMalfunctionIndicatorLamp : 14|2@1+ (1,0) [0|3] "" Vector__XXX
SG_ SuspectParameterNumber : 23|19@0+ (1,0) [0|524287] "" Vector__XXX
SG_ FailureModeIdentifier : 32|5@1+ (1,0) [0|31] "" Vector__XXX
SG_ OccurrenceCount : 40|7@1+ (1,0) [0|127] "" Vector__XXX
SG_ SPNConversionMethod : 47|1@1+ (1,0) [0|1] "" Vector__XXX

BO_ 2499641854 EGRBV: 8 Vector__XXX
SG_ EGR1CoolerBypassActuatorPostion : 0|8@1+ (0.4,0) [0|100] "%" Vector__XXX

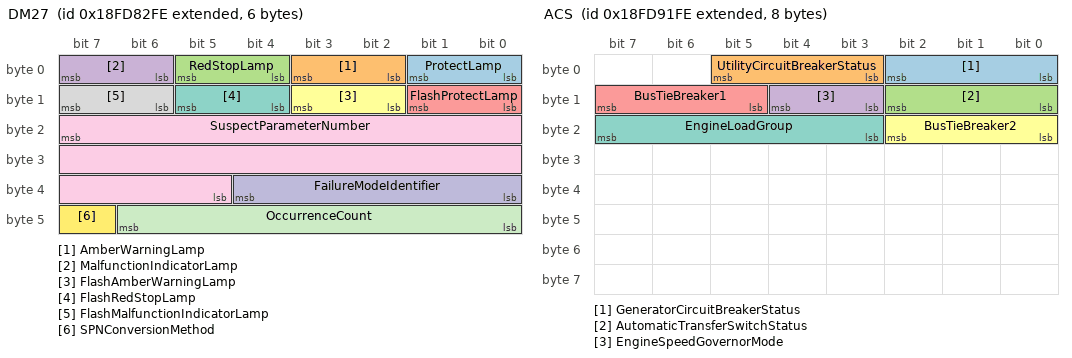
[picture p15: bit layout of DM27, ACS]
BO_ 2566750974 DM27: 6 Vector__XXX
SG_ ProtectLamp : 0|2@1+ (1,0) [0|3] "" Vector__XXX
SG_ AmberWarningLamp : 2|2@1+ (1,0) [0|3] "" Vector__XXX
SG_ RedStopLamp : 4|2@1+ (1,0) [0|3] "" Vector__XXX
SG_ MalfunctionIndicatorLamp : 6|2@1+ (1,0) [0|3] "" Vector__XXX
SG_ FlashProtectLamp : 8|2@1+ (1,0) [0|3] "" Vector__XXX
SG_ FlashAmberWarningLamp : 10|2@1+ (1,0) [0|3] "" Vector__XXX
SG_ FlashRedStopLamp : 12|2@1+ (1,0) [0|3] "" Vector__XXX
SG_ FlashMalfunctionIndicatorLamp : 14|2@1+ (1,0) [0|3] "" Vector__XXX
SG_ SuspectParameterNumber : 23|19@0+ (1,0) [0|524287] "" Vector__XXX
SG_ FailureModeIdentifier : 32|5@1+ (1,0) [0|31] "" Vector__XXX
SG_ OccurrenceCount : 40|7@1+ (1,0) [0|127] "" Vector__XXX
SG_ SPNConversionMethod : 47|1@1+ (1,0) [0|1] "" Vector__XXX

BO_ 2566751230 TCI: 8 Vector__XXX
SG_ TransferCaseStatus : 0|3@1+ (1,0) [0|7] "" Vector__XXX
SG_ TransferCaseDirectionStatus : 3|2@1+ (1,0) [0|3] "" Vector__XXX

BO_ 2566751486 EFL_P9: 8 Vector__XXX
SG_ EngIntkValveActOilPressForCyl17 : 0|16@1+ (0.1,0) [0|6425.5] "kPa" Vector__XXX
SG_ EngIntkValveActOilPressForCyl18 : 16|16@1+ (0.1,0) [0|6425.5] "kPa" Vector__XXX
SG_ EngIntkValveActOilPressForCyl19 : 32|16@1+ (0.1,0) [0|6425.5] "kPa" Vector__XXX
SG_ EngIntkValveActOilPressForCyl20 : 48|16@1+ (0.1,0) [0|6425.5] "kPa" Vector__XXX

BO_ 2566751742 EFL_P8: 8 Vector__XXX
SG_ EngIntkValveActOilPressForCyl13 : 0|16@1+ (0.1,0) [0|6425.5] "kPa" Vector__XXX
SG_ EngIntkValveActOilPressForCyl14 : 16|16@1+ (0.1,0) [0|6425.5] "kPa" Vector__XXX
SG_ EngIntkValveActOilPressForCyl15 : 32|16@1+ (0.1,0) [0|6425.5] "kPa" Vector__XXX
SG_ EngIntkValveActOilPressForCyl16 : 48|16@1+ (0.1,0) [0|6425.5] "kPa" Vector__XXX

BO_ 2566751998 EFL_P7: 8 Vector__XXX
SG_ EngIntkValveActOilPressForCyl9 : 0|16@1+ (0.1,0) [0|6425.5] "kPa" Vector__XXX
SG_ EngIntkValveActOilPressForCyl10 : 16|16@1+ (0.1,0) [0|6425.5] "kPa" Vector__XXX
SG_ EngIntkValveActOilPressForCyl11 : 32|16@1+ (0.1,0) [0|6425.5] "kPa" Vector__XXX
SG_ EngIntkValveActOilPressForCyl12 : 48|16@1+ (0.1,0) [0|6425.5] "kPa" Vector__XXX

BO_ 2566752254 EFL_P6: 8 Vector__XXX
SG_ EngIntkValveActOilPressForCyl5 : 0|16@1+ (0.1,0) [0|6425.5] "kPa" Vector__XXX
SG_ EngIntkValveActOilPressForCyl6 : 16|16@1+ (0.1,0) [0|6425.5] "kPa" Vector__XXX
SG_ EngIntkValveActOilPressForCyl7 : 32|16@1+ (0.1,0) [0|6425.5] "kPa" Vector__XXX
SG_ EngIntkValveActOilPressForCyl8 : 48|16@1+ (0.1,0) [0|6425.5] "kPa" Vector__XXX

BO_ 2566752510 EFL_P5: 8 Vector__XXX
SG_ EngIntkValveActOilPressForCyl1 : 0|16@1+ (0.1,0) [0|6425.5] "kPa" Vector__XXX
SG_ EngIntkValveActOilPressForCyl2 : 16|16@1+ (0.1,0) [0|6425.5] "kPa" Vector__XXX
SG_ EngIntkValveActOilPressForCyl3 : 32|16@1+ (0.1,0) [0|6425.5] "kPa" Vector__XXX
SG_ EngIntkValveActOilPressForCyl4 : 48|16@1+ (0.1,0) [0|6425.5] "kPa" Vector__XXX

BO_ 2566752766 VDS2: 8 Vector__XXX
SG_ VehicleRoll : 0|16@1+ (0.0078125,-200) [-200|301.99] "deg" Vector__XXX

BO_ 2633861886 J2012: 8 Vector__XXX
SG_ NumberOfJ2012DTCs : 0|8@1+ (1,0) [0|250] "" Vector__XXX
SG_ J2012DTC : 15|40@0+ (1,0) [0|0] "ASCII" Vector__XXX
SG_ J2012DTCStatus : 48|1@1+ (1,0) [0|1] "" Vector__XXX
SG_ J2012DTCOccurrenceCount : 49|7@1+ (1,0) [0|127] "" Vector__XXX

BO_ 2566753278 AT2GP: 8 Vector__XXX
SG_ Aftrtrtmnt2DslPFIntkPressure : 0|16@1+ (0.1,0) [0|6425.5] "kPa" Vector__XXX
SG_ Aftrtrtmnt2DslPFOtltPressure : 16|16@1+ (0.1,0) [0|6425.5] "kPa" Vector__XXX

BO_ 2566753534 AT1GP: 8 Vector__XXX
SG_ Aftrtrtmnt1DslPFIntkPressure : 0|16@1+ (0.1,0) [0|6425.5] "kPa" Vector__XXX
SG_ Aftrtrtmnt1DslPFOtltPressure : 16|16@1+ (0.1,0) [0|6425.5] "kPa" Vector__XXX

BO_ 2566753790 UTACER: 8 Vector__XXX
SG_ UtilityTotalKVArHoursExport : 0|32@1+ (1,0) [0|4211081215] "kVArh" Vector__XXX
SG_ UtilityTotalKVArHoursImport : 32|32@1+ (1,0) [0|4211081215] "kVArh" Vector__XXX

BO_ 2566754046 GTACER: 8 Vector__XXX
SG_ GeneratorTotalKVArHoursExport : 0|32@1+ (1,0) [0|4211081215] "kVArh" Vector__XXX
SG_ GeneratorTotalKVArHoursImport : 32|32@1+ (1,0) [0|4211081215] "kVArh" Vector__XXX

BO_ 2566754302 GTACPP: 8 Vector__XXX
SG_ GeneratorTotalPercentKW : 0|16@1+ (0.0078125,-251) [-251|250.99] "%" Vector__XXX
SG_ GeneratorTotalPercentKVA : 16|16@1+ (0.0078125,-251) [-251|250.99] "%" Vector__XXX
SG_ GeneratorTotalPercentKVAr : 32|16@1+ (0.0078125,-251) [-251|250.99] "%" Vector__XXX

BO_ 2566754558 AETC: 8 Vector__XXX
SG_ AETCDataCollectionStandard : 0|4@1+ (1,0) [0|15] "" Vector__XXX
SG_ NumberOfAETCDataPoints : 4|4@1+ (1,0) [0|15] "" Vector__XXX

BO_ 2566754814 ACS: 8 Vector__XXX
SG_ GeneratorCircuitBreakerStatus : 0|3@1+ (1,0) [0|7] "" Vector__XXX
SG_ UtilityCircuitBreakerStatus : 3|3@1+ (1,0) [0|7] "" Vector__XXX
SG_ AutomaticTransferSwitchStatus : 8|3@1+ (1,0) [0|7] "" Vector__XXX
SG_ EngineSpeedGovernorMode : 11|2@1+ (1,0) [0|3] "" Vector__XXX
SG_ BusTieBreaker1 : 13|3@1+ (1,0) [0|7] "" Vector__XXX
SG_ BusTieBreaker2 : 16|3@1+ (1,0) [0|7] "" Vector__XXX
SG_ EngineLoadGroup : 19|5@1+ (1,0) [0|31] "" Vector__XXX

BO_ 2365428478 EOI: 8 Vector__XXX
SG_ EngineOperatingState : 0|4@1+ (1,0) [0|15] "" Vector__XXX
SG_ FuelPumpPrimerControl : 4|2@1+ (1,0) [0|3] "" Vector__XXX
SG_ EngineStarterMotorRelayControl : 6|2@1+ (1,0) [0|3] "" Vector__XXX
SG_ TimeRemainingInEngOperatingState : 8|16@1+ (1,0) [0|64255] "s" Vector__XXX
SG_ EngineFuelShutoffVentControl : 24|2@1+ (1,0) [0|3] "" Vector__XXX
SG_ EngineFuelShutoff1Control : 26|2@1+ (1,0) [0|3] "" Vector__XXX
SG_ EngineFuelShutoff2Control : 28|2@1+ (1,0) [0|3] "" Vector__XXX
SG_ EngFuelShutoffValveLeakTestCtrl : 30|2@1+ (1,0) [0|3] "" Vector__XXX
SG_ EngineOilPrimingPumpControl : 32|2@1+ (1,0) [0|3] "" Vector__XXX
SG_ EngineOilPreHeaterControl : 34|2@1+ (1,0) [0|3] "" Vector__XXX
SG_ EngElectrclSystemPwrConservCtrl : 36|2@1+ (1,0) [0|3] "" Vector__XXX
SG_ EnginePreHeaterControl : 38|2@1+ (1,0) [0|3] "" Vector__XXX
SG_ EngineCoolantPumpControl : 40|2@1+ (1,0) [0|3] "" Vector__XXX
SG_ EngineControlledShutdownRequest : 42|2@1+ (1,0) [0|3] "" Vector__XXX
SG_ EngineEmrgncyShutdownIndication : 44|2@1+ (1,0) [0|3] "" Vector__XXX
SG_ EngColdAmbientElevatedIdleStatus : 46|2@1+ (1,0) [0|3] "" Vector__XXX
SG_ EngineDesiredTorqueRequest : 48|8@1+ (1,-125) [-125|125] "%" Vector__XXX
SG_ EngineDerateRequest : 56|8@1+ (0.4,0) [0|100] "%" Vector__XXX

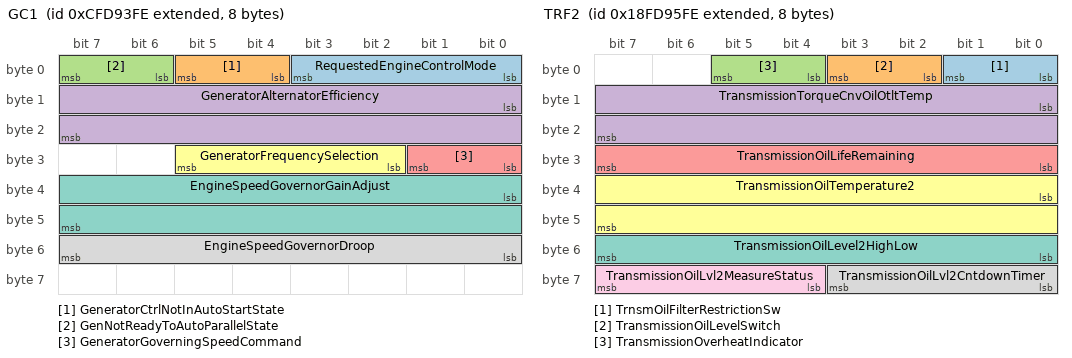
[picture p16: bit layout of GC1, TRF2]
BO_ 2365428734 GC1: 8 Vector__XXX
SG_ RequestedEngineControlMode : 0|4@1+ (1,0) [0|15] "" Vector__XXX
SG_ GeneratorCtrlNotInAutoStartState : 4|2@1+ (1,0) [0|3] "" Vector__XXX
SG_ GenNotReadyToAutoParallelState : 6|2@1+ (1,0) [0|3] "" Vector__XXX
SG_ GeneratorAlternatorEfficiency : 8|16@1+ (0.0025,0) [0|160.6375] "%" Vector__XXX
SG_ GeneratorGoverningSpeedCommand : 24|2@1+ (1,0) [0|3] "" Vector__XXX
SG_ GeneratorFrequencySelection : 26|4@1+ (1,0) [0|15] "" Vector__XXX
SG_ EngineSpeedGovernorGainAdjust : 32|16@1+ (1,-32128) [-32128|32127] "" Vector__XXX
SG_ EngineSpeedGovernorDroop : 48|8@1+ (0.04,0) [0|10] "%" Vector__XXX

BO_ 2566755582 EEC7: 8 Vector__XXX
SG_ EngExhstGasRecirc1ValvePos : 0|16@1+ (0.0025,0) [0|160.6375] "%" Vector__XXX
SG_ EngExhstGasRecirc1Valve2Pos : 16|16@1+ (0.0025,0) [0|160.6375] "%" Vector__XXX
SG_ EngCrankCsBrearOilSeparatorSpd : 32|16@1+ (1,0) [0|64255] "rpm" Vector__XXX
SG_ EngIntakeManifoldCmdedPressure : 48|16@1+ (0.125,0) [0|8031.875] "kPa" Vector__XXX

BO_ 2566755838 TRF2: 8 Vector__XXX
SG_ TrnsmOilFilterRestrictionSw : 0|2@1+ (1,0) [0|3] "" Vector__XXX
SG_ TransmissionOilLevelSwitch : 2|2@1+ (1,0) [0|3] "" Vector__XXX
SG_ TransmissionOverheatIndicator : 4|2@1+ (1,0) [0|3] "" Vector__XXX
SG_ TransmissionTorqueCnvOilOtltTemp : 8|16@1+ (0.03125,-273) [-273|1734.96875] "deg C" Vector__XXX
SG_ TransmissionOilLifeRemaining : 24|8@1+ (0.4,0) [0|100] "%" Vector__XXX
SG_ TransmissionOilTemperature2 : 32|16@1+ (0.03125,-273) [-273|1734.96875] "deg C" Vector__XXX
SG_ TransmissionOilLevel2HighLow : 48|8@1+ (0.5,-62.5) [-62.5|62.5] "l" Vector__XXX
SG_ TransmissionOilLvl2CntdownTimer : 56|4@1+ (1,0) [0|15] "" Vector__XXX
SG_ TransmissionOilLvl2MeasureStatus : 60|4@1+ (1,0) [0|15] "" Vector__XXX

BO_ 2566756094 LFI2: 8 Vector__XXX
SG_ EngineFuelSupplyFlowRate : 0|32@1+ (0.001,0) [0|4211081.215] "l/h" Vector__XXX
SG_ EngineFuelReturnFlowRate : 32|32@1+ (0.001,0) [0|4211081.215] "l/h" Vector__XXX

BO_ 2566756350 LFI3: 8 Vector__XXX
SG_ EngineFuelSupplyTemperature : 0|8@1+ (1,-40) [-40|210] "deg C" Vector__XXX
SG_ EngineFuelReturnTemperature : 8|8@1+ (1,-40) [-40|210] "deg C" Vector__XXX

BO_ 2566756606 AT1HI1: 40 Vector__XXX
SG_ Aftertreatment1TotalFuelUsed : 0|32@1+ (0.5,0) [0|2105540607.5] "l" Vector__XXX
SG_ Aftrtrtmnt1TotalRegenerationTime : 32|32@1+ (1,0) [0|4211081215] "s" Vector__XXX
SG_ Aftertreatment1TotalDisabledTime : 64|32@1+ (1,0) [0|4211081215] "s" Vector__XXX
SG_ Aftrtrtmnt1TotalNoOfActvRegens : 96|32@1+ (1,0) [0|4211081215] "" Vector__XXX
SG_ Aft1DslPFTotalPassiveRegenTme : 128|32@1+ (1,0) [0|4211081215] "s" Vector__XXX
SG_ Aft1DslPFTotalNoOfPassiveRegens : 160|32@1+ (1,0) [0|4211081215] "" Vector__XXX
SG_ Aft1DPFTotalNoOfActRegenInhbtRqs : 192|32@1+ (1,0) [0|4211081215] "" Vector__XXX
SG_ Aft1DslPFTotalNoOfActRegenManRqs : 224|32@1+ (1,0) [0|4211081215] "" Vector__XXX
SG_ Aft1DPFAvrgTmeBetweenActvRegens : 256|32@1+ (1,0) [0|4211081215] "s" Vector__XXX
SG_ Aft1DPFAvrgDistBetweenActvRegens : 288|32@1+ (0.125,0) [0|526385151.875] "km" Vector__XXX

BO_ 2566756862 AT2HI1: 40 Vector__XXX
SG_ Aftertreatment2TotalFuelUsed : 0|32@1+ (0.5,0) [0|2105540607.5] "l" Vector__XXX
SG_ Aftrtrtmnt2TotalRegenerationTime : 32|32@1+ (1,0) [0|4211081215] "s" Vector__XXX
SG_ Aftertreatment2TotalDisabledTime : 64|32@1+ (1,0) [0|4211081215] "s" Vector__XXX
SG_ Aftrtrtmnt2TotalNoOfActvRegens : 96|32@1+ (1,0) [0|4211081215] "" Vector__XXX
SG_ Aft2DslPFTotalPassiveRegenTme : 128|32@1+ (1,0) [0|4211081215] "s" Vector__XXX
SG_ Aft2DslPFTotalNoOfPassiveRegens : 160|32@1+ (1,0) [0|4211081215] "" Vector__XXX
SG_ Aft2DPFTotalNoOfActRegenInhbtRqs : 192|32@1+ (1,0) [0|4211081215] "" Vector__XXX
SG_ Aft2DslPFTotalNoOfActRegenManRqs : 224|32@1+ (1,0) [0|4211081215] "" Vector__XXX
SG_ Aft2DPFAvrgTmeBetweenActvRegens : 256|32@1+ (1,0) [0|4211081215] "s" Vector__XXX
SG_ Aft2DPFAvrgDistBetweenActvRegens : 288|32@1+ (0.125,0) [0|526385151.875] "km" Vector__XXX

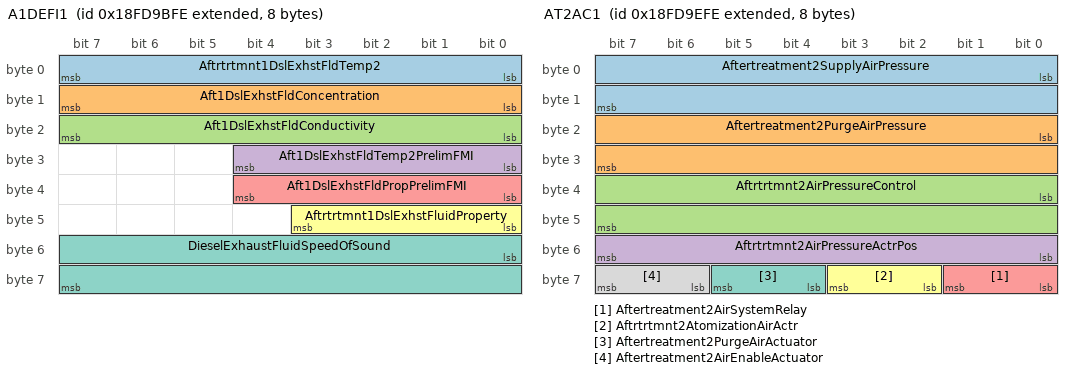
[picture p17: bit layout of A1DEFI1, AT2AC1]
BO_ 2566757374 A1DEFI1: 8 Vector__XXX
SG_ Aftrtrtmnt1DslExhstFldTemp2 : 0|8@1+ (1,-40) [-40|210] "deg C" Vector__XXX
SG_ Aft1DslExhstFldConcentration : 8|8@1+ (0.25,0) [0|62.5] "%" Vector__XXX
SG_ Aft1DslExhstFldConductivity : 16|8@1+ (5,0) [0|1250] "uSiemens/mm" Vector__XXX
SG_ Aft1DslExhstFldTemp2PrelimFMI : 24|5@1+ (1,0) [0|31] "" Vector__XXX
SG_ Aft1DslExhstFldPropPrelimFMI : 32|5@1+ (1,0) [0|31] "" Vector__XXX
SG_ Aftrtrtmnt1DslExhstFluidProperty : 40|4@1+ (1,0) [0|15] "" Vector__XXX
SG_ DieselExhaustFluidSpeedOfSound : 48|16@1+ (0.1,0) [0|6425.5] "m/s" Vector__XXX

BO_ 2566757630 SEP2: 8 Vector__XXX
SG_ SensorSupplyVoltage5 : 0|16@1+ (0.05,0) [0|3212.75] "V" Vector__XXX
SG_ SensorSupplyVoltage6 : 16|16@1+ (0.05,0) [0|3212.75] "V" Vector__XXX
SG_ SensorSupplyVoltage7 : 32|16@1+ (0.05,0) [0|3212.75] "V" Vector__XXX
SG_ SensorSupplyVoltage8 : 48|16@1+ (0.05,0) [0|3212.75] "V" Vector__XXX

BO_ 2566757886 SEP1: 8 Vector__XXX
SG_ SensorSupplyVoltage1 : 0|16@1+ (0.05,0) [0|3212.75] "V" Vector__XXX
SG_ SensorSupplyVoltage2 : 16|16@1+ (0.05,0) [0|3212.75] "V" Vector__XXX
SG_ SensorSupplyVoltage3 : 32|16@1+ (0.05,0) [0|3212.75] "V" Vector__XXX
SG_ SensorSupplyVoltage4 : 48|16@1+ (0.05,0) [0|3212.75] "V" Vector__XXX

BO_ 2566758142 AT2AC1: 8 Vector__XXX
SG_ Aftertreatment2SupplyAirPressure : 0|16@1+ (0.1,0) [0|6425.5] "kPa" Vector__XXX
SG_ Aftertreatment2PurgeAirPressure : 16|16@1+ (0.1,0) [0|6425.5] "kPa" Vector__XXX
SG_ Aftrtrtmnt2AirPressureControl : 32|16@1+ (0.0025,0) [0|160.6375] "%" Vector__XXX
SG_ Aftrtrtmnt2AirPressureActrPos : 48|8@1+ (0.4,0) [0|100] "%" Vector__XXX
SG_ Aftertreatment2AirSystemRelay : 56|2@1+ (1,0) [0|3] "" Vector__XXX
SG_ Aftrtrtmnt2AtomizationAirActr : 58|2@1+ (1,0) [0|3] "" Vector__XXX
SG_ Aftertreatment2PurgeAirActuator : 60|2@1+ (1,0) [0|3] "" Vector__XXX
SG_ Aftertreatment2AirEnableActuator : 62|2@1+ (1,0) [0|3] "" Vector__XXX

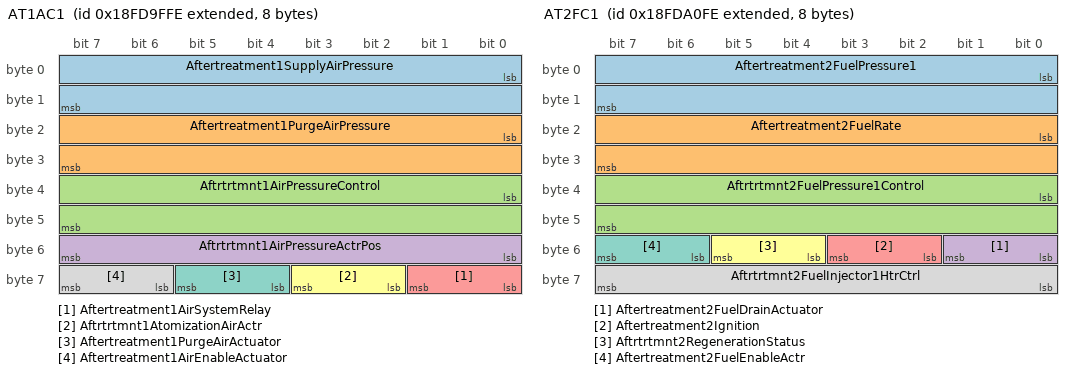
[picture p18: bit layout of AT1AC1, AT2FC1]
BO_ 2566758398 AT1AC1: 8 Vector__XXX
SG_ Aftertreatment1SupplyAirPressure : 0|16@1+ (0.1,0) [0|6425.5] "kPa" Vector__XXX
SG_ Aftertreatment1PurgeAirPressure : 16|16@1+ (0.1,0) [0|6425.5] "kPa" Vector__XXX
SG_ Aftrtrtmnt1AirPressureControl : 32|16@1+ (0.0025,0) [0|160.6375] "%" Vector__XXX
SG_ Aftrtrtmnt1AirPressureActrPos : 48|8@1+ (0.4,0) [0|100] "%" Vector__XXX
SG_ Aftertreatment1AirSystemRelay : 56|2@1+ (1,0) [0|3] "" Vector__XXX
SG_ Aftrtrtmnt1AtomizationAirActr : 58|2@1+ (1,0) [0|3] "" Vector__XXX
SG_ Aftertreatment1PurgeAirActuator : 60|2@1+ (1,0) [0|3] "" Vector__XXX
SG_ Aftertreatment1AirEnableActuator : 62|2@1+ (1,0) [0|3] "" Vector__XXX

BO_ 2566758654 AT2FC1: 8 Vector__XXX
SG_ Aftertreatment2FuelPressure1 : 0|16@1+ (0.1,0) [0|6425.5] "kPa" Vector__XXX
SG_ Aftertreatment2FuelRate : 16|16@1+ (0.05,0) [0|3212.75] "l/h" Vector__XXX
SG_ Aftrtrtmnt2FuelPressure1Control : 32|16@1+ (0.0025,0) [0|160.6375] "%" Vector__XXX
SG_ Aftertreatment2FuelDrainActuator : 48|2@1+ (1,0) [0|3] "" Vector__XXX
SG_ Aftertreatment2Ignition : 50|2@1+ (1,0) [0|3] "" Vector__XXX
SG_ Aftrtrtmnt2RegenerationStatus : 52|2@1+ (1,0) [0|3] "" Vector__XXX
SG_ Aftertreatment2FuelEnableActr : 54|2@1+ (1,0) [0|3] "" Vector__XXX
SG_ Aftrtrtmnt2FuelInjector1HtrCtrl : 56|8@1+ (0.4,0) [0|100] "%" Vector__XXX

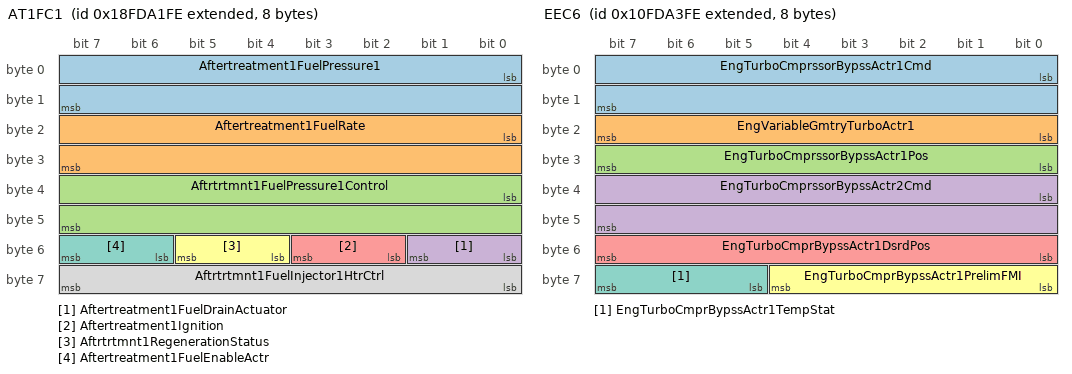
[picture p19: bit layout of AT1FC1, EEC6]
BO_ 2566758910 AT1FC1: 8 Vector__XXX
SG_ Aftertreatment1FuelPressure1 : 0|16@1+ (0.1,0) [0|6425.5] "kPa" Vector__XXX
SG_ Aftertreatment1FuelRate : 16|16@1+ (0.05,0) [0|3212.75] "l/h" Vector__XXX
SG_ Aftrtrtmnt1FuelPressure1Control : 32|16@1+ (0.0025,0) [0|160.6375] "%" Vector__XXX
SG_ Aftertreatment1FuelDrainActuator : 48|2@1+ (1,0) [0|3] "" Vector__XXX
SG_ Aftertreatment1Ignition : 50|2@1+ (1,0) [0|3] "" Vector__XXX
SG_ Aftrtrtmnt1RegenerationStatus : 52|2@1+ (1,0) [0|3] "" Vector__XXX
SG_ Aftertreatment1FuelEnableActr : 54|2@1+ (1,0) [0|3] "" Vector__XXX
SG_ Aftrtrtmnt1FuelInjector1HtrCtrl : 56|8@1+ (0.4,0) [0|100] "%" Vector__XXX

BO_ 2432541438 GFI3: 8 Vector__XXX
SG_ EngFuelValve2IntakeAbsPressure : 0|16@1+ (0.1,0) [0|6425.5] "kPa" Vector__XXX
SG_ EngineFuelSystem2GasMassFlowRate : 16|16@1+ (0.05,0) [0|3212.75] "kg/h" Vector__XXX
SG_ EngineFuelTemperature2 : 32|8@1+ (1,-40) [-40|210] "deg C" Vector__XXX
SG_ EngFuelValve2OutletAbsPressure : 48|16@1+ (0.1,0) [0|6425.5] "kPa" Vector__XXX

BO_ 2432541694 EEC6: 8 Vector__XXX
SG_ EngTurboCmprssorBypssActr1Cmd : 0|16@1+ (0.0025,0) [0|160.6375] "%" Vector__XXX
SG_ EngVariableGmtryTurboActr1 : 16|8@1+ (0.4,0) [0|100] "%" Vector__XXX
SG_ EngTurboCmprssorBypssActr1Pos : 24|8@1+ (0.4,0) [0|100] "%" Vector__XXX
SG_ EngTurboCmprssorBypssActr2Cmd : 32|16@1+ (0.0025,0) [0|160.6375] "%" Vector__XXX
SG_ EngTurboCmprBypssActr1DsrdPos : 48|8@1+ (0.4,0) [0|100] "%" Vector__XXX
SG_ EngTurboCmprBypssActr1PrelimFMI : 56|5@1+ (1,0) [0|31] "" Vector__XXX
SG_ EngTurboCmprBypssActr1TempStat : 61|3@1+ (1,0) [0|7] "" Vector__XXX

BO_ 2566759678 PTODE: 8 Vector__XXX
SG_ EnblSwitchTransferCsOutptShftPTO : 0|2@1+ (1,0) [0|3] "" Vector__XXX
SG_ EnblSwTransmissionOutptShftPTO : 2|2@1+ (1,0) [0|3] "" Vector__XXX
SG_ EnblSwTransmissionInputShftPTO2 : 4|2@1+ (1,0) [0|3] "" Vector__XXX
SG_ EnblSwTransmissionInputShftPTO1 : 6|2@1+ (1,0) [0|3] "" Vector__XXX
SG_ EnableSwitchPTOEngineFlywheel : 8|2@1+ (1,0) [0|3] "" Vector__XXX
SG_ EnableSwitchPTOEngineAccssryDrv1 : 10|2@1+ (1,0) [0|3] "" Vector__XXX
SG_ EnableSwitchPTOEngineAccssryDrv2 : 12|2@1+ (1,0) [0|3] "" Vector__XXX
SG_ EngmntConsntTrnsfrCsOutptShftPTO : 16|2@1+ (1,0) [0|3] "" Vector__XXX
SG_ EngmntConsntTrnsmOutptShftPTO : 18|2@1+ (1,0) [0|3] "" Vector__XXX
SG_ EngmntConsntTrnsmInputShftPTO2 : 20|2@1+ (1,0) [0|3] "" Vector__XXX
SG_ EngmntConsntTrnsmInputShftPTO1 : 22|2@1+ (1,0) [0|3] "" Vector__XXX
SG_ EngmntConsntPTOEngineFlywheel : 24|2@1+ (1,0) [0|3] "" Vector__XXX
SG_ EngmntConsntPTOEngineAccssryDrv1 : 26|2@1+ (1,0) [0|3] "" Vector__XXX
SG_ EngmntConsntPTOEngineAccssryDrv2 : 28|2@1+ (1,0) [0|3] "" Vector__XXX
SG_ EngmntStatTransferCsOutptShftPTO : 32|2@1+ (1,0) [0|3] "" Vector__XXX
SG_ EngmntStatTrnsmOutptShftPTO : 34|2@1+ (1,0) [0|3] "" Vector__XXX
SG_ EngmntStatTrnsmInputShftPTO2 : 36|2@1+ (1,0) [0|3] "" Vector__XXX
SG_ EngmntStatTrnsmInputShftPTO1 : 38|2@1+ (1,0) [0|3] "" Vector__XXX
SG_ EngmntStatusPTOEngineFlywheel : 40|2@1+ (1,0) [0|3] "" Vector__XXX
SG_ EngmntStatusPTOEngineAccssryDrv1 : 42|2@1+ (1,0) [0|3] "" Vector__XXX
SG_ EngmntStatusPTOEngineAccssryDrv2 : 44|2@1+ (1,0) [0|3] "" Vector__XXX
SG_ AtLeastOnePTOEngaged : 48|2@1+ (1,0) [0|3] "" Vector__XXX

CM_ BO_ 2365402110 "Extended Joystick Message 6";
CM_ BO_ 2365402366 "Basic Joystick Message 6";
CM_ BO_ 2365402622 "Extended Joystick Message 5";
CM_ BO_ 2365402878 "Basic Joystick Message 5";
CM_ BO_ 2365403134 "Extended Joystick Message 4";
CM_ BO_ 2365403390 "Basic Joystick Message 4";
CM_ BO_ 2566730238 "Fan Drive #2";
CM_ BO_ 2566730750 "Aftertreatment 2 Diesel Exhaust Fluid Supply Information";
CM_ BO_ 2566731006 "Aftertreatment 2 SCR Reagant Tank 2 Information";
CM_ BO_ 2566731262 "Aftertreatment 2 Diesel Exhaust Fluid Tank 1 Information 1";
CM_ BO_ 2566731518 "Aftertreatment 2 Diesel Exhaust Fluid Information 1";
CM_ BO_ 2566731774 "Aftertreatment 2 SCR Service Information 1";
CM_ BO_ 2566732030 "Aftertreatment 2 SCR Exhaust Gas Temperature 1";
CM_ BO_ 2566732286 "Aftertreatment 2 SCR Exhaust Gas Pressures";
CM_ BO_ 2566732542 "Aftertreatment 2 SCR Dosing System Requests 2";
CM_ BO_ 2566732798 "Aftertreatment 2 SCR Dosing System Information 2";
CM_ BO_ 2566733054 "Aftertreatment 1 Diesel Exhaust Fluid Supply Information";
CM_ BO_ 2566733310 "Aftertreatment 1 SCR Reagant Tank 2 Information";
CM_ BO_ 2499624702 "Aftertreatment 1 SCR Exhaust Gas Temperature 1";
CM_ BO_ 2566733822 "Aftertreatment 1 SCR Exhaust Gas Pressures";
CM_ BO_ 2566734078 "Aftertreatment 1 SCR Dosing System Requests 2";
CM_ BO_ 2566734334 "Aftertreatment 1 SCR Dosing System Information 2";
CM_ BO_ 2566735102 "Aftertreatment 2 Fuel Control 2";
CM_ BO_ 2566735358 "Aftertreatment 2 Three Way Catalyst";
CM_ BO_ 2566735614 "Aftertreatment 1 Three Way Catalyst";
CM_ BO_ 2633844734 "Transmission Mode Labels";
CM_ BO_ 2566736126 "Engine Exhaust Bank 2 O2 Fuel Trim";
CM_ BO_ 2566736382 "Engine Exhaust Bank 1 O2 Fuel Trim";
CM_ BO_ 2432520702 "Aftercooler Coolant Control Valve Command";
CM_ BO_ 2432520958 "Engine Coolant Control Valve Command";
CM_ BO_ 2499630078 "Engine Average Information";
CM_ BO_ 2566739198 "DTCs - C, Previously Active";
CM_ BO_ 2566739454 "DTCs - C, Confirmed and Active";
CM_ BO_ 2566739710 "DTCs - C, Pending";
CM_ BO_ 2566739966 "DTCs - B2, Previously Active";
CM_ BO_ 2566740222 "DTCs - B2, Confirmed and Active";
CM_ BO_ 2566740478 "DTCs - B2, Pending";
CM_ BO_ 2566740734 "DTCs - B1, Previously Active";
CM_ BO_ 2566740990 "DTCs - B1, Confirmed and Active";
CM_ BO_ 2566741246 "DTCs - B1, Pending";
CM_ BO_ 2566741502 "DTCs - A, Previously Active";
CM_ BO_ 2566741758 "DTCs - A, Confirmed and Active";
CM_ BO_ 2566742014 "DTCs - A, Pending";
CM_ BO_ 2566742270 "Harmonized B1 Failure Counts";
CM_ BO_ 2566742526 "Harmonized Cumulative Continuous Malfunction Indicator – System";
CM_ BO_ 2566742782 "Harmonized Global Regulation Description";
CM_ BO_ 2566743038 "Harmonized Roadworthiness – System";
CM_ BO_ 2566743294 "Harmonized Roadworthiness - Vehicle";
CM_ BO_ 2566743550 "Aftertreatment 1 Fuel Control 2";
CM_ BO_ 2566743806 "Engine Temperature 4";
CM_ BO_ 2566744062 "Zero Net Vehicle Weight Change";
CM_ BO_ 2499635454 "Gross Combination Vehicle Weight";
CM_ BO_ 2633853438 "Axle Group Calibration Weights";
CM_ BO_ 2499635966 "Axle Group Weight";
CM_ BO_ 2566745086 "Available Axle Group Weights";
CM_ BO_ 2566745342 "Aftertreatment 2 Air Control 2";
CM_ BO_ 2566745598 "Aftertreatment 1 Air Control 2";
CM_ BO_ 2566745854 "Aftertreatment 1 SCR Service Information 1";
CM_ BO_ 2566746110 "Electronic Engine Controller 8";
CM_ BO_ 2566746366 "Door ramp control";
CM_ BO_ 2566746622 "Brake actuator stroke status";
CM_ BO_ 2566746878 "Engine Spark Voltage 6";
CM_ BO_ 2566747134 "Engine Spark Voltage 5";
CM_ BO_ 2566747390 "Engine Spark Voltage 4";
CM_ BO_ 2566747646 "Engine Spark Voltage 3";
CM_ BO_ 2566747902 "Engine Spark Voltage 2";
CM_ BO_ 2566748158 "Engine Spark Voltage 1";
CM_ BO_ 2566748414 "Aftertreatment 2 Trip Information";
CM_ BO_ 2566748670 "Aftertreatment 1 Trip Information";
CM_ BO_ 2566748926 "Aftertreatment 2 Service 1";
CM_ BO_ 2566749182 "Aftertreatment 1 Service 1";
CM_ BO_ 2566749438 "Diesel Particulate Filter Control 1";
CM_ BO_ 2566749694 "Reserved for FMS Telltale status";
CM_ BO_ 2566749950 "Adaptive Front-Lighting System Status";
CM_ BO_ 2566750206 "Engine Configuration 2";
CM_ BO_ 2566750462 "Emission-Related Permanent Diagnostic Trouble Codes";
CM_ BO_ 2499641854 "EGR Cooler Bypass";
CM_ BO_ 2566750974 "All Pending DTCs";
CM_ BO_ 2566751230 "Transfer Case Information";
CM_ BO_ 2566751486 "Engine Fluid Level/Pressure 9";
CM_ BO_ 2566751742 "Engine Fluid Level/Pressure 8";
CM_ BO_ 2566751998 "Engine Fluid Level/Pressure 7";
CM_ BO_ 2566752254 "Engine Fluid Level/Pressure 6";
CM_ BO_ 2566752510 "Engine Fluid Level/Pressure 5";
CM_ BO_ 2566752766 "Vehicle Direction/Speed 2";
CM_ BO_ 2633861886 "SAE J2012 DTC Display";
CM_ BO_ 2566753278 "Aftertreatment 2 Gas Parameters";
CM_ BO_ 2566753534 "Aftertreatment 1 Gas Parameters";
CM_ BO_ 2566753790 "Utility Total AC Reactive Energy";
CM_ BO_ 2566754046 "Generator Total AC Reactive Energy";
CM_ BO_ 2566754302 "Generator Total AC Percent Power";
CM_ BO_ 2566754558 "Advertised Engine Torque Curve";
CM_ BO_ 2566754814 "AC Switching Device Status";
CM_ BO_ 2365428478 "Engine Operating Information";
CM_ BO_ 2365428734 "Generator Control 1";
CM_ BO_ 2566755582 "Electronic Engine Controller 7";
CM_ BO_ 2566755838 "Transmission Fluids 2";
CM_ BO_ 2566756094 "Fuel Information 2 (Liquid)";
CM_ BO_ 2566756350 "Fuel Information 3 (Liquid)";
CM_ BO_ 2566756606 "Aftertreatment 1 Historical Information 1";
CM_ BO_ 2566756862 "Aftertreatment 2 Historical information 1";
CM_ BO_ 2566757374 "Aftertreatment 1 Diesel Exhaust Fluid Information 1";
CM_ BO_ 2566757630 "Sensor Electrical Power #2";
CM_ BO_ 2566757886 "Sensor Electrical Power #1";
CM_ BO_ 2566758142 "Aftertreatment 2 Air Control 1";
CM_ BO_ 2566758398 "Aftertreatment 1 Air Control 1";
CM_ BO_ 2566758654 "Aftertreatment 2 Fuel Control 1";
CM_ BO_ 2566758910 "Aftertreatment 1 Fuel Control 1";
CM_ BO_ 2432541438 "Fuel Information 3 (Gaseous)";
CM_ BO_ 2432541694 "Electronic Engine Controller 6";
CM_ BO_ 2566759678 "PTO Drive Engagement";
BA_DEF_ BO_  "VFrameFormat" ENUM  "StandardCAN","ExtendedCAN","reserved","J1939PG";
BA_DEF_ BO_  "GenMsgCycleTime" INT 0 65535;
BA_DEF_ SG_  "GenSigStartValue" FLOAT -3.4E+038 3.4E+038;
BA_DEF_ SG_  "SPN" INT ;
BA_DEF_ SG_  "SigType" ENUM "Default","Range","RangeSigned","ASCII","Discrete","Control","ReferencePGN","DTC","StringDelimiter","StringLength","StringLengthControl","MessageCounter","MessageChecksum";
BA_DEF_DEF_  "VFrameFormat" "J1939PG";
BA_DEF_DEF_  "GenMsgCycleTime" 0;
BA_DEF_DEF_  "GenSigStartValue" 0;
BA_DEF_DEF_  "SPN" 0;
BA_DEF_DEF_  "SigType" "Default";
BA_ "GenMsgCycleTime" BO_ 2365402110 100;
BA_ "GenMsgCycleTime" BO_ 2365402366 100;
BA_ "GenMsgCycleTime" BO_ 2365402622 100;
BA_ "GenMsgCycleTime" BO_ 2365402878 100;
BA_ "GenMsgCycleTime" BO_ 2365403134 100;
BA_ "GenMsgCycleTime" BO_ 2365403390 100;
BA_ "GenMsgCycleTime" BO_ 2566730238 1000;
BA_ "GenMsgCycleTime" BO_ 2566730750 1000;
BA_ "GenMsgCycleTime" BO_ 2566731006 1000;
BA_ "GenMsgCycleTime" BO_ 2566731262 1000;
BA_ "GenMsgCycleTime" BO_ 2566731518 1000;
BA_ "GenMsgCycleTime" BO_ 2566732030 500;
BA_ "GenMsgCycleTime" BO_ 2566732286 500;
BA_ "GenMsgCycleTime" BO_ 2566732542 500;
BA_ "GenMsgCycleTime" BO_ 2566732798 500;
BA_ "GenMsgCycleTime" BO_ 2566733054 1000;
BA_ "GenMsgCycleTime" BO_ 2566733310 1000;
BA_ "GenMsgCycleTime" BO_ 2499624702 500;
BA_ "GenMsgCycleTime" BO_ 2566733822 500;
BA_ "GenMsgCycleTime" BO_ 2566734078 500;
BA_ "GenMsgCycleTime" BO_ 2566734334 500;
BA_ "GenMsgCycleTime" BO_ 2566735102 500;
BA_ "GenMsgCycleTime" BO_ 2566735358 500;
BA_ "GenMsgCycleTime" BO_ 2566735614 500;
BA_ "GenMsgCycleTime" BO_ 2432520702 1000;
BA_ "GenMsgCycleTime" BO_ 2432520958 1000;
BA_ "GenMsgCycleTime" BO_ 2499630078 500;
BA_ "GenMsgCycleTime" BO_ 2566743038 10000;
BA_ "GenMsgCycleTime" BO_ 2566743550 500;
BA_ "GenMsgCycleTime" BO_ 2566743806 1000;
BA_ "GenMsgCycleTime" BO_ 2499635454 10000;
BA_ "GenMsgCycleTime" BO_ 2499635966 20;
BA_ "GenMsgCycleTime" BO_ 2566745342 500;
BA_ "GenMsgCycleTime" BO_ 2566745598 500;
BA_ "GenMsgCycleTime" BO_ 2566746366 1000;
BA_ "GenMsgCycleTime" BO_ 2566746622 1000;
BA_ "GenMsgCycleTime" BO_ 2566749438 1000;
BA_ "GenMsgCycleTime" BO_ 2499641854 500;
BA_ "GenMsgCycleTime" BO_ 2566751230 1000;
BA_ "GenMsgCycleTime" BO_ 2566751486 500;
BA_ "GenMsgCycleTime" BO_ 2566751742 500;
BA_ "GenMsgCycleTime" BO_ 2566751998 500;
BA_ "GenMsgCycleTime" BO_ 2566752254 500;
BA_ "GenMsgCycleTime" BO_ 2566752510 500;
BA_ "GenMsgCycleTime" BO_ 2566753278 500;
BA_ "GenMsgCycleTime" BO_ 2566753534 500;
BA_ "GenMsgCycleTime" BO_ 2566753790 250;
BA_ "GenMsgCycleTime" BO_ 2566754046 250;
BA_ "GenMsgCycleTime" BO_ 2566754302 250;
BA_ "GenMsgCycleTime" BO_ 2566754814 250;
BA_ "GenMsgCycleTime" BO_ 2365428478 250;
BA_ "GenMsgCycleTime" BO_ 2365428734 100;
BA_ "GenMsgCycleTime" BO_ 2566755582 100;
BA_ "GenMsgCycleTime" BO_ 2566755838 1000;
BA_ "GenMsgCycleTime" BO_ 2566756094 1000;
BA_ "GenMsgCycleTime" BO_ 2566756350 1000;
BA_ "GenMsgCycleTime" BO_ 2566757374 1000;
BA_ "GenMsgCycleTime" BO_ 2566757630 1000;
BA_ "GenMsgCycleTime" BO_ 2566757886 1000;
BA_ "GenMsgCycleTime" BO_ 2566758142 500;
BA_ "GenMsgCycleTime" BO_ 2566758398 500;
BA_ "GenMsgCycleTime" BO_ 2566758654 500;
BA_ "GenMsgCycleTime" BO_ 2566758910 500;
BA_ "GenMsgCycleTime" BO_ 2432541438 500;
BA_ "GenMsgCycleTime" BO_ 2432541694 100;
BA_ "GenMsgCycleTime" BO_ 2566759678 100;
BA_ "SPN" SG_ 2365402110 Jystck6GrpXAxsNtrlPositionStatus 4587;
BA_ "SPN" SG_ 2365402110 Jystck6GrpXAxsLvrLftNegPosStatus 4588;
BA_ "SPN" SG_ 2365402110 Jystck6GrpXAxsLvrRghtPstvPosStat 4589;
BA_ "SPN" SG_ 2365402110 Joystick6GripXAxisPosition 4590;
BA_ "SPN" SG_ 2365402110 Jystck6GrpYAxsNtrlPositionStatus 4591;
BA_ "SPN" SG_ 2365402110 Jystck6GrpYAxsLvrBackNegPosStat 4592;
BA_ "SPN" SG_ 2365402110 Jystck6GrpYAxsLvrFrwdPstvPosStat 4593;
BA_ "SPN" SG_ 2365402110 Joystick6GripYAxisPosition 4594;
BA_ "SPN" SG_ 2365402110 Jystck6ThetaAxsNtrlPosStatus 4595;
BA_ "SPN" SG_ 2365402110 Jystck6ThtAxsCntrClckwsNegPsStat 4596;
BA_ "SPN" SG_ 2365402110 Jystck6ThetaAxsClckwsPstvPosStat 4597;
BA_ "SPN" SG_ 2365402110 Joystick6ThetaAxisPosition 4598;
BA_ "SPN" SG_ 2365402110 Jystck6ThetaAxsDetentPosStatus 4599;
BA_ "SPN" SG_ 2365402110 Jystck6GrpYAxsDetentPosStatus 4600;
BA_ "SPN" SG_ 2365402110 Jystck6GrpXAxsDetentPosStatus 4601;
BA_ "SPN" SG_ 2365402110 Joystick6Button16PressedStatus 6754;
BA_ "SPN" SG_ 2365402110 Joystick6Button15PressedStatus 6753;
BA_ "SPN" SG_ 2365402110 Joystick6Button14PressedStatus 6752;
BA_ "SPN" SG_ 2365402110 Joystick6Button13PressedStatus 6751;
BA_ "SPN" SG_ 2365402366 Jystck6XAxsNeutralPositionStatus 4565;
BA_ "SPN" SG_ 2365402366 Jystck6XAxsLvrLftNegPosStatus 4566;
BA_ "SPN" SG_ 2365402366 Jystck6XAxsLvrRightPstvPosStatus 4567;
BA_ "SPN" SG_ 2365402366 Joystick6XAxisPosition 4568;
BA_ "SPN" SG_ 2365402366 Jystck6YAxsNeutralPositionStatus 4569;
BA_ "SPN" SG_ 2365402366 Jystck6YAxsLvrBackNegPosStatus 4570;
BA_ "SPN" SG_ 2365402366 Jystck6YAxsLvrFrwdPstvPosStatus 4571;
BA_ "SPN" SG_ 2365402366 Joystick6YAxisPosition 4572;
BA_ "SPN" SG_ 2365402366 Jystck6YAxsDetentPositionStatus 4573;
BA_ "SPN" SG_ 2365402366 Jystck6XAxsDetentPositionStatus 4574;
BA_ "SPN" SG_ 2365402366 Joystick6Button4PressedStatus 4575;
BA_ "SPN" SG_ 2365402366 Joystick6Button3PressedStatus 4576;
BA_ "SPN" SG_ 2365402366 Joystick6Button2PressedStatus 4577;
BA_ "SPN" SG_ 2365402366 Joystick6Button1PressedStatus 4578;
BA_ "SPN" SG_ 2365402366 Joystick6Button8PressedStatus 4579;
BA_ "SPN" SG_ 2365402366 Joystick6Button7PressedStatus 4580;
BA_ "SPN" SG_ 2365402366 Joystick6Button6PressedStatus 4581;
BA_ "SPN" SG_ 2365402366 Joystick6Button5PressedStatus 4582;
BA_ "SPN" SG_ 2365402366 Joystick6Button12PressedStatus 4583;
BA_ "SPN" SG_ 2365402366 Joystick6Button11PressedStatus 4584;
BA_ "SPN" SG_ 2365402366 Joystick6Button10PressedStatus 4585;
BA_ "SPN" SG_ 2365402366 Joystick6Button9PressedStatus 4586;
BA_ "SPN" SG_ 2365402622 Jystck5GrpXAxsNtrlPositionStatus 4550;
BA_ "SPN" SG_ 2365402622 Jystck5GrpXAxsLvrLftNegPosStatus 4551;
BA_ "SPN" SG_ 2365402622 Jystck5GrpXAxsLvrRghtPstvPosStat 4552;
BA_ "SPN" SG_ 2365402622 Joystick5GripXAxisPosition 4553;
BA_ "SPN" SG_ 2365402622 Jystck5GrpYAxsNtrlPositionStatus 4554;
BA_ "SPN" SG_ 2365402622 Jystck5GrpYAxsLvrBackNegPosStat 4555;
BA_ "SPN" SG_ 2365402622 Jystck5GrpYAxsLvrFrwdPstvPosStat 4556;
BA_ "SPN" SG_ 2365402622 Joystick5GripYAxisPosition 4557;
BA_ "SPN" SG_ 2365402622 Jystck5ThetaAxsNtrlPosStatus 4558;
BA_ "SPN" SG_ 2365402622 Jystck5ThtAxsCntrClckwsNegPsStat 4559;
BA_ "SPN" SG_ 2365402622 Jystck5ThetaAxsClckwsPstvPosStat 4560;
BA_ "SPN" SG_ 2365402622 Joystick5ThetaAxisPosition 4561;
BA_ "SPN" SG_ 2365402622 Jystck5ThetaAxsDetentPosStatus 4562;
BA_ "SPN" SG_ 2365402622 Jystck5GrpYAxsDetentPosStatus 4563;
BA_ "SPN" SG_ 2365402622 Jystck5GrpXAxsDetentPosStatus 4564;
BA_ "SPN" SG_ 2365402622 Joystick5Button16PressedStatus 6750;
BA_ "SPN" SG_ 2365402622 Joystick5Button15PressedStatus 6749;
BA_ "SPN" SG_ 2365402622 Joystick5Button14PressedStatus 6748;
BA_ "SPN" SG_ 2365402622 Joystick5Button13PressedStatus 6747;
BA_ "SPN" SG_ 2365402878 Jystck5XAxsNeutralPositionStatus 4528;
BA_ "SPN" SG_ 2365402878 Jystck5XAxsLvrLftNegPosStatus 4529;
BA_ "SPN" SG_ 2365402878 Jystck5XAxsLvrRightPstvPosStatus 4530;
BA_ "SPN" SG_ 2365402878 Joystick5XAxisPosition 4531;
BA_ "SPN" SG_ 2365402878 Jystck5YAxsNeutralPositionStatus 4532;
BA_ "SPN" SG_ 2365402878 Jystck5YAxsLvrBackNegPosStatus 4533;
BA_ "SPN" SG_ 2365402878 Jystck5YAxsLvrFrwdPstvPosStatus 4534;
BA_ "SPN" SG_ 2365402878 Joystick5YAxisPosition 4535;
BA_ "SPN" SG_ 2365402878 Jystck5YAxsDetentPositionStatus 4536;
BA_ "SPN" SG_ 2365402878 Jystck5XAxsDetentPositionStatus 4537;
BA_ "SPN" SG_ 2365402878 Joystick5Button4PressedStatus 4538;
BA_ "SPN" SG_ 2365402878 Joystick5Button3PressedStatus 4539;
BA_ "SPN" SG_ 2365402878 Joystick5Button2PressedStatus 4540;
BA_ "SPN" SG_ 2365402878 Joystick5Button1PressedStatus 4541;
BA_ "SPN" SG_ 2365402878 Joystick5Button8PressedStatus 4542;
BA_ "SPN" SG_ 2365402878 Joystick5Button7PressedStatus 4543;
BA_ "SPN" SG_ 2365402878 Joystick5Button6PressedStatus 4544;
BA_ "SPN" SG_ 2365402878 Joystick5Button5PressedStatus 4545;
BA_ "SPN" SG_ 2365402878 Joystick5Button12PressedStatus 4546;
BA_ "SPN" SG_ 2365402878 Joystick5Button11PressedStatus 4547;
BA_ "SPN" SG_ 2365402878 Joystick5Button10PressedStatus 4548;
BA_ "SPN" SG_ 2365402878 Joystick5Button9PressedStatus 4549;
BA_ "SPN" SG_ 2365403134 Jystck4GrpXAxsNtrlPositionStatus 4513;
BA_ "SPN" SG_ 2365403134 Jystck4GrpXAxsLvrLftNegPosStatus 4514;
BA_ "SPN" SG_ 2365403134 Jystck4GrpXAxsLvrRghtPstvPosStat 4515;
BA_ "SPN" SG_ 2365403134 Joystick4GripXAxisPosition 4516;
BA_ "SPN" SG_ 2365403134 Jystck4GrpYAxsNtrlPositionStatus 4517;
BA_ "SPN" SG_ 2365403134 Jystck4GrpYAxsLvrBackNegPosStat 4518;
BA_ "SPN" SG_ 2365403134 Jystck4GrpYAxsLvrFrwdPstvPosStat 4519;
BA_ "SPN" SG_ 2365403134 Joystick4GripYAxisPosition 4520;
BA_ "SPN" SG_ 2365403134 Jystck4ThetaAxsNtrlPosStatus 4521;
BA_ "SPN" SG_ 2365403134 Jystck4ThtAxsCntrClckwsNegPsStat 4522;
BA_ "SPN" SG_ 2365403134 Jystck4ThetaAxsClckwsPstvPosStat 4523;
BA_ "SPN" SG_ 2365403134 Joystick4ThetaAxisPosition 4524;
BA_ "SPN" SG_ 2365403134 Jystck4ThetaAxsDetentPosStatus 4525;
BA_ "SPN" SG_ 2365403134 Jystck4GrpYAxsDetentPosStatus 4526;
BA_ "SPN" SG_ 2365403134 Jystck4GrpXAxsDetentPosStatus 4527;
BA_ "SPN" SG_ 2365403134 Joystick4Button16PressedStatus 6746;
BA_ "SPN" SG_ 2365403134 Joystick4Button15PressedStatus 6745;
BA_ "SPN" SG_ 2365403134 Joystick4Button14PressedStatus 6744;
BA_ "SPN" SG_ 2365403134 Joystick4Button13PressedStatus 6743;
BA_ "SPN" SG_ 2365403390 Jystck4XAxsNeutralPositionStatus 4491;
BA_ "SPN" SG_ 2365403390 Jystck4XAxsLvrLftNegPosStatus 4492;
BA_ "SPN" SG_ 2365403390 Jystck4XAxsLvrRightPstvPosStatus 4493;
BA_ "SPN" SG_ 2365403390 Joystick4XAxisPosition 4494;
BA_ "SPN" SG_ 2365403390 Jystck4YAxsNeutralPositionStatus 4495;
BA_ "SPN" SG_ 2365403390 Jystck4YAxsLvrBackNegPosStatus 4496;
BA_ "SPN" SG_ 2365403390 Jystck4YAxsLvrFrwdPstvPosStatus 4497;
BA_ "SPN" SG_ 2365403390 Joystick4YAxisPosition 4498;
BA_ "SPN" SG_ 2365403390 Jystck4YAxsDetentPositionStatus 4499;
BA_ "SPN" SG_ 2365403390 Jystck4XAxsDetentPositionStatus 4500;
BA_ "SPN" SG_ 2365403390 Joystick4Button4PressedStatus 4501;
BA_ "SPN" SG_ 2365403390 Joystick4Button3PressedStatus 4502;
BA_ "SPN" SG_ 2365403390 Joystick4Button2PressedStatus 4503;
BA_ "SPN" SG_ 2365403390 Joystick4Button1PressedStatus 4504;
BA_ "SPN" SG_ 2365403390 Joystick4Button8PressedStatus 4505;
BA_ "SPN" SG_ 2365403390 Joystick4Button7PressedStatus 4506;
BA_ "SPN" SG_ 2365403390 Joystick4Button6PressedStatus 4507;
BA_ "SPN" SG_ 2365403390 Joystick4Button5PressedStatus 4508;
BA_ "SPN" SG_ 2365403390 Joystick4Button12PressedStatus 4509;
BA_ "SPN" SG_ 2365403390 Joystick4Button11PressedStatus 4510;
BA_ "SPN" SG_ 2365403390 Joystick4Button10PressedStatus 4511;
BA_ "SPN" SG_ 2365403390 Joystick4Button9PressedStatus 4512;
BA_ "SPN" SG_ 2566730238 EstimatedPercentFan2Speed 1550;
BA_ "SPN" SG_ 2566730238 Fan2DriveState 1557;
BA_ "SPN" SG_ 2566730238 Fan2Speed 1598;
BA_ "SPN" SG_ 2566730238 HydraulicFan2MotorPressure 1707;
BA_ "SPN" SG_ 2566730238 Fan2DriveBypassCommandStatus 1708;
BA_ "SPN" SG_ 2566730750 Aftrtrtmnt2DslExhstFldPmpMtrSpd 4440;
BA_ "SPN" SG_ 2566730750 Aft2DslExhstFldPmpDrvPrcntage 4441;
BA_ "SPN" SG_ 2566730750 Aftrtrtmnt2DslExhstFldReturnVlv 4442;
BA_ "SPN" SG_ 2566730750 Aft2DslExhstFldTnkFillVlvCmd 5437;
BA_ "SPN" SG_ 2566730750 Aftrtrtmnt2DslExhstFldPumpState 5438;
BA_ "SPN" SG_ 2566730750 Aftrtrtmnt2DslExhstFldPmpPwrRely 8481;
BA_ "SPN" SG_ 2566730750 Aftrtrtmnt2DslExhaustFluidPump 7108;
BA_ "SPN" SG_ 2566730750 Aft2DslExhstFldTnkDrainVlvCmd 5439;
BA_ "SPN" SG_ 2566730750 Aft2DslExhstFldDsngUnit2DivVlv 7537;
BA_ "SPN" SG_ 2566731006 Aftrtrtmnt2DslExhstFldTank2Level 4433;
BA_ "SPN" SG_ 2566731006 Aftrtrtmnt2DslExhstFldTnk2Temp 4434;
BA_ "SPN" SG_ 2566731006 Aftrtrtmnt2DslExhstFldTank2Lvl2 4435;
BA_ "SPN" SG_ 2566731006 Aft2DslExhstFldTnk2LvlPrelimFMI 4436;
BA_ "SPN" SG_ 2566731006 Aft2DslExhstFldTnk2TempPrelimFMI 4437;
BA_ "SPN" SG_ 2566731006 Aftrtrtmnt2DslExhstFldTank2Htr 4438;
BA_ "SPN" SG_ 2566731006 Aft2DslExhstFldTnk2HtrPrelimFMI 4439;
BA_ "SPN" SG_ 2566731262 Aftrtrtmnt2DslExhstFldTankLevel 4426;
BA_ "SPN" SG_ 2566731262 Aftrtrtmnt2DslExhstFldTnkTemp 4427;
BA_ "SPN" SG_ 2566731262 Aftrtrtmnt2DslExhstFldTankLevel2 4428;
BA_ "SPN" SG_ 2566731262 Aft2DslExhstFldTnkLvlPrelimFMI 4429;
BA_ "SPN" SG_ 2566731262 Aft2DslExhstFldTnk1TempPrelimFMI 4430;
BA_ "SPN" SG_ 2566731262 Aftrtrtmnt2DslExhstFldTankHeater 4431;
BA_ "SPN" SG_ 2566731262 Aft2DslExhstFldTnk1HtrPrelimFMI 4432;
BA_ "SPN" SG_ 2566731518 Aftrtrtmnt2DslExhstFldTemp2 4420;
BA_ "SPN" SG_ 2566731518 Aft2DslExhstFldConcentration 4421;
BA_ "SPN" SG_ 2566731518 Aft2DslExhstFldConductivity 4422;
BA_ "SPN" SG_ 2566731518 Aft2DslExhstFldTemp2PrelimFMI 4423;
BA_ "SPN" SG_ 2566731518 Aft2DslExhstFldPropPrelimFMI 4424;
BA_ "SPN" SG_ 2566731518 Aftrtrtmnt2DslExhaustFluidType 4425;
BA_ "SPN" SG_ 2566731774 Aft2DslExhstFldAvrgCnsmptn 4417;
BA_ "SPN" SG_ 2566731774 Aft2SCRCmdedDslExhstFldCnsmptn 4418;
BA_ "SPN" SG_ 2566731774 Aftrtrtmnt2SCRCnvrsnEfficiency 4419;
BA_ "SPN" SG_ 2566731774 Aftrtrtmnt2SCRSystemSulfationLvl 7849;
BA_ "SPN" SG_ 2566732030 Aftrtrtmnt2SCRIntakeTemperature 4413;
BA_ "SPN" SG_ 2566732030 Aftrtrtmnt2SCRIntkTempPrelimFMI 4414;
BA_ "SPN" SG_ 2566732030 Aftrtrtmnt2SCROutletTemperature 4415;
BA_ "SPN" SG_ 2566732030 Aftrtrtmnt2SCROtltTempPrelimFMI 4416;
BA_ "SPN" SG_ 2566732286 Aftrtrtmnt2SCRDiffPressure 4411;
BA_ "SPN" SG_ 2566732286 Aftrtrtmnt2SCRDiffPressPrelimFMI 4412;
BA_ "SPN" SG_ 2566732286 Aftertreatment2SCRIntakePressure 6587;
BA_ "SPN" SG_ 2566732286 Aftrtrtmnt2SCRIntakeAbsPressure 6798;
BA_ "SPN" SG_ 2566732542 Aft2DslExhstFldDsrFltSupPrsionRq 4405;
BA_ "SPN" SG_ 2566732542 Aft2DslExhstFldDoserHeatingMdeRq 4406;
BA_ "SPN" SG_ 2566732542 Aftrtrtmnt2DslExhstFldLineHtr1 4407;
BA_ "SPN" SG_ 2566732542 Aftrtrtmnt2DslExhstFldLineHtr2 4408;
BA_ "SPN" SG_ 2566732542 Aftrtrtmnt2DslExhstFldLineHtr3 4409;
BA_ "SPN" SG_ 2566732542 Aftrtrtmnt2DslExhstFldLineHtr4 4410;
BA_ "SPN" SG_ 2566732542 Aftrtrtmnt2DslExhstFldTankHtrCmd 5138;
BA_ "SPN" SG_ 2566732542 Aftrtrtmnt2DslExhstFldTnk2HtrCmd 5415;
BA_ "SPN" SG_ 2566732542 Aft2DslExhstFldLineHtrRely1 5973;
BA_ "SPN" SG_ 2566732542 Aft2DslExhstFldLineHtrRely2 7526;
BA_ "SPN" SG_ 2566732542 Aft2DslExhstFldLineHtrRely3 7527;
BA_ "SPN" SG_ 2566732542 Aftrtrtmnt2DslExhstFldLineHtr5 5490;
BA_ "SPN" SG_ 2566732542 Aftrtrtmnt2DslExhstFldLineHtr6 7567;
BA_ "SPN" SG_ 2566732542 Aftrtrtmnt2DslExhstFldLineHtr7 7568;
BA_ "SPN" SG_ 2566732542 Aftrtrtmnt2DslExhstFldLineHtr8 7569;
BA_ "SPN" SG_ 2566732542 Aftrtrtmnt2DslExhstFldLineHtr9 7570;
BA_ "SPN" SG_ 2566732542 Aftrtrtmnt2DslExhstFldLineHtr10 7571;
BA_ "SPN" SG_ 2566732798 Aft2SCRDsngAirAssistAbsPress 4388;
BA_ "SPN" SG_ 2566732798 Aftrtrtmnt2SCRDsngAirAssistValve 4389;
BA_ "SPN" SG_ 2566732798 Aftrtrtmnt2DslExhstFldDsngTemp 4390;
BA_ "SPN" SG_ 2566732798 Aft2SCRDsngVlvExhstTempRedRq 4391;
BA_ "SPN" SG_ 2566732798 Aftrtrtmnt2SCRFeedbackCtrlStatus 4392;
BA_ "SPN" SG_ 2566732798 Aft2DslExhstFldLineHtr1Stat 4393;
BA_ "SPN" SG_ 2566732798 Aft2DslExhstFldLineHtr1PrelimFMI 4394;
BA_ "SPN" SG_ 2566732798 Aft2DslExhstFldLineHtr2Stat 4395;
BA_ "SPN" SG_ 2566732798 Aft2DslExhstFldLineHtr2PrelimFMI 4396;
BA_ "SPN" SG_ 2566732798 Aft2DslExhstFldLineHtr3Stat 4397;
BA_ "SPN" SG_ 2566732798 Aft2DslExhstFldLineHtr3PrelimFMI 4398;
BA_ "SPN" SG_ 2566732798 Aft2DslExhstFldLineHtr4Stat 4399;
BA_ "SPN" SG_ 2566732798 Aft2DslExhstFldLineHtr4PrelimFMI 4400;
BA_ "SPN" SG_ 2566733054 Aftrtrtmnt1DslExhstFldPmpMtrSpd 4374;
BA_ "SPN" SG_ 2566733054 Aft1DslExhstFldPmpDrvPrcntage 4375;
BA_ "SPN" SG_ 2566733054 Aftrtrtmnt1DslExhstFldReturnVlv 4376;
BA_ "SPN" SG_ 2566733054 Aft1DslExhstFldTnkFillVlvCmd 5434;
BA_ "SPN" SG_ 2566733054 Aftrtrtmnt1DslExhstFldPumpState 5435;
BA_ "SPN" SG_ 2566733054 Aftrtrtmnt1DslExhstFldPmpPwrRely 7416;
BA_ "SPN" SG_ 2566733054 Aftrtrtmnt1DslExhaustFluidPump 7107;
BA_ "SPN" SG_ 2566733054 Aft1DslExhstFldTnkDrainVlvCmd 5436;
BA_ "SPN" SG_ 2566733054 Aft1DslExhstFldDsngUnit2DivVlv 7536;
BA_ "SPN" SG_ 2566733310 Aftrtrtmnt1DslExhstFldTank2Level 4367;
BA_ "SPN" SG_ 2566733310 Aftrtrtmnt1DslExhstFldTnk2Temp 4368;
BA_ "SPN" SG_ 2566733310 Aftrtrtmnt1DslExhstFldTank2Lvl2 4369;
BA_ "SPN" SG_ 2566733310 Aft1DslExhstFldTnk2LvlPrelimFMI 4370;
BA_ "SPN" SG_ 2566733310 Aft1DslExhstFldTnk2TempPrelimFMI 4371;
BA_ "SPN" SG_ 2566733310 Aftrtrtmnt1DslExhstFldTank2Htr 4372;
BA_ "SPN" SG_ 2566733310 Aft1DslExhstFldTnk2HtrPrelimFMI 4373;
BA_ "SPN" SG_ 2499624702 Aftrtrtmnt1SCRIntakeTemperature 4360;
BA_ "SPN" SG_ 2499624702 Aftrtrtmnt1SCRIntkTempPrelimFMI 4361;
BA_ "SPN" SG_ 2499624702 Aftrtrtmnt1SCROutletTemperature 4363;
BA_ "SPN" SG_ 2499624702 Aftrtrtmnt1SCROtltTempPrelimFMI 4362;
BA_ "SPN" SG_ 2566733822 Aftrtrtmnt1SCRDiffPressure 4358;
BA_ "SPN" SG_ 2566733822 Aftrtrtmnt1SCRDiffPressPrelimFMI 4359;
BA_ "SPN" SG_ 2566733822 Aftertreatment1SCRIntakePressure 6586;
BA_ "SPN" SG_ 2566733822 Aftrtrtmnt1SCRIntakeAbsPressure 6797;
BA_ "SPN" SG_ 2566734078 Aft1DslExhstFldDsrFltSupPrsionRq 4352;
BA_ "SPN" SG_ 2566734078 Aft1DslExhstFldDoserHeatingMdeRq 4353;
BA_ "SPN" SG_ 2566734078 Aftrtrtmnt1DslExhstFldLineHtr1 4354;
BA_ "SPN" SG_ 2566734078 Aftrtrtmnt1DslExhstFldLineHtr2 4355;
BA_ "SPN" SG_ 2566734078 Aftrtrtmnt1DslExhstFldLineHtr3 4356;
BA_ "SPN" SG_ 2566734078 Aftrtrtmnt1DslExhstFldLineHtr4 4357;
BA_ "SPN" SG_ 2566734078 Aftrtrtmnt1DslExhstFldTankHtrCmd 5137;
BA_ "SPN" SG_ 2566734078 Aftrtrtmnt1DslExhstFldTnk2HtrCmd 5414;
BA_ "SPN" SG_ 2566734078 Aftrtrtmnt1DslExhstFldPumpHtrCmd 5707;
BA_ "SPN" SG_ 2566734078 Aft1DslExhstFldLineHtrRely1 5491;
BA_ "SPN" SG_ 2566734078 Aft1DslExhstFldLineHtrRely2 7069;
BA_ "SPN" SG_ 2566734078 Aft1DslExhstFldLineHtrRely3 7540;
BA_ "SPN" SG_ 2566734078 Aftrtrtmnt1DslExhstFldLineHtr5 7561;
BA_ "SPN" SG_ 2566734078 Aftrtrtmnt1DslExhstFldLineHtr6 7562;
BA_ "SPN" SG_ 2566734078 Aftrtrtmnt1DslExhstFldLineHtr7 7563;
BA_ "SPN" SG_ 2566734078 Aftrtrtmnt1DslExhstFldLineHtr8 7564;
BA_ "SPN" SG_ 2566734078 Aftrtrtmnt1DslExhstFldLineHtr9 7565;
BA_ "SPN" SG_ 2566734078 Aftrtrtmnt1DslExhstFldLineHtr10 7566;
BA_ "SPN" SG_ 2566734334 Aft1SCRDsngAirAssistAbsPress 4335;
BA_ "SPN" SG_ 2566734334 Aftrtrtmnt1SCRDsngAirAssistValve 4336;
BA_ "SPN" SG_ 2566734334 Aftrtrtmnt1DslExhstFldDsngTemp 4337;
BA_ "SPN" SG_ 2566734334 Aft1SCRDsngVlvExhstTempRedRq 4338;
BA_ "SPN" SG_ 2566734334 Aftrtrtmnt1SCRFeedbackCtrlStatus 4339;
BA_ "SPN" SG_ 2566734334 Aft1DslExhstFldLineHtr1Stat 4340;
BA_ "SPN" SG_ 2566734334 Aft1DslExhstFldLineHtr1PrelimFMI 4341;
BA_ "SPN" SG_ 2566734334 Aft1DslExhstFldLineHtr2Stat 4342;
BA_ "SPN" SG_ 2566734334 Aft1DslExhstFldLineHtr2PrelimFMI 4343;
BA_ "SPN" SG_ 2566734334 Aft1DslExhstFldLineHtr3Stat 4344;
BA_ "SPN" SG_ 2566734334 Aft1DslExhstFldLineHtr3PrelimFMI 4345;
BA_ "SPN" SG_ 2566734334 Aft1DslExhstFldLineHtr4Stat 4346;
BA_ "SPN" SG_ 2566734334 Aft1DslExhstFldLineHtr4PrelimFMI 4347;
BA_ "SPN" SG_ 2566735102 Aftertreatment2FuelPressure2 4303;
BA_ "SPN" SG_ 2566735102 Aftrtrtmnt2FuelPumpRelayControl 5426;
BA_ "SPN" SG_ 2566735102 Aft2FuelFlwDiverterVlvCtrl 5427;
BA_ "SPN" SG_ 2566735102 Aftrtrtmnt2FuelPressure2Control 5428;
BA_ "SPN" SG_ 2566735358 Aftrtrtmnt23WyCtlystIntkTemp 4295;
BA_ "SPN" SG_ 2566735358 Aftrtrtmnt23WyCtlystOtltTemp 4296;
BA_ "SPN" SG_ 2566735358 Aftrtrtmnt23WyCtlystDiffPress 4297;
BA_ "SPN" SG_ 2566735358 Aft23WyCtlystIntkTempPrelimFMI 4298;
BA_ "SPN" SG_ 2566735358 Aft23WyCtlystOtltTempPrelimFMI 4299;
BA_ "SPN" SG_ 2566735358 Aft23WyCtlytcCnvDiffPressPrlmFMI 4300;
BA_ "SPN" SG_ 2566735614 Aftrtrtmnt13WyCtlystIntkTemp 4289;
BA_ "SPN" SG_ 2566735614 Aftrtrtmnt13WyCtlystOtltTemp 4290;
BA_ "SPN" SG_ 2566735614 Aftrtrtmnt13WyCtlystDiffPress 4291;
BA_ "SPN" SG_ 2566735614 Aft13WyCtlystIntkTempPrelimFMI 4292;
BA_ "SPN" SG_ 2566735614 Aft13WyCtlystOtltTempPrelimFMI 4293;
BA_ "SPN" SG_ 2566735614 Aft13WyCtlytcCnvDiffPressPrlmFMI 4294;
BA_ "SPN" SG_ 2566736126 LongTermFuelTrimBank2 4239;
BA_ "SPN" SG_ 2566736126 ShortTermFuelTrimBank2 4238;
BA_ "SPN" SG_ 2566736126 EngExhstBnk2O2SensorClsdLpOp 4241;
BA_ "SPN" SG_ 2566736382 LongTermFuelTrimBank1 4237;
BA_ "SPN" SG_ 2566736382 ShortTermFuelTrimBank1 4236;
BA_ "SPN" SG_ 2566736382 EngExhstBnk1O2SensorClsdLpOp 4240;
BA_ "SPN" SG_ 2432520702 AftercoolerCoolantThermostatMode 4198;
BA_ "SPN" SG_ 2432520702 DsrdAftrclrCoolntIntkTemperature 4199;
BA_ "SPN" SG_ 2432520702 DsrdAftrclrCoolntThrmsttOpening 4200;
BA_ "SPN" SG_ 2432520702 EngineChrgAirCoolBypssValve1Cmd 7421;
BA_ "SPN" SG_ 2432520702 EngineChrgAirCoolBypssValve2Cmd 7422;
BA_ "SPN" SG_ 2432520958 EngineCoolantThermostatMode 4195;
BA_ "SPN" SG_ 2432520958 DsrdEngCoolntPumpOtltTemperature 4196;
BA_ "SPN" SG_ 2432520958 DsrdEngCoolntThermostatOpening 4197;
BA_ "SPN" SG_ 2432520958 EngineAuxCoolSupplyValve1ActrCmd 5546;
BA_ "SPN" SG_ 2432520958 EngineAuxCoolSupplyValve2ActrCmd 5547;
BA_ "SPN" SG_ 2499630078 EngineExhaustTemperatureAverage 4151;
BA_ "SPN" SG_ 2499630078 EngineExhaustBnk1TemperatureAvrg 4153;
BA_ "SPN" SG_ 2499630078 EngineExhaustBnk2TemperatureAvrg 4152;
BA_ "SPN" SG_ 2566739198 ProtectLamp 987;
BA_ "SPN" SG_ 2566739198 AmberWarningLamp 624;
BA_ "SPN" SG_ 2566739198 RedStopLamp 623;
BA_ "SPN" SG_ 2566739198 MalfunctionIndicatorLamp 1213;
BA_ "SPN" SG_ 2566739198 FlashProtectLamp 3041;
BA_ "SPN" SG_ 2566739198 FlashAmberWarningLamp 3040;
BA_ "SPN" SG_ 2566739198 FlashRedStopLamp 3039;
BA_ "SPN" SG_ 2566739198 FlashMalfunctionIndicatorLamp 3038;
BA_ "SPN" SG_ 2566739198 SuspectParameterNumber 1214;
BA_ "SPN" SG_ 2566739198 FailureModeIdentifier 1215;
BA_ "SPN" SG_ 2566739198 OccurrenceCount 1216;
BA_ "SPN" SG_ 2566739198 SPNConversionMethod 1706;
BA_ "SPN" SG_ 2566739454 ProtectLamp 987;
BA_ "SPN" SG_ 2566739454 AmberWarningLamp 624;
BA_ "SPN" SG_ 2566739454 RedStopLamp 623;
BA_ "SPN" SG_ 2566739454 MalfunctionIndicatorLamp 1213;
BA_ "SPN" SG_ 2566739454 FlashProtectLamp 3041;
BA_ "SPN" SG_ 2566739454 FlashAmberWarningLamp 3040;
BA_ "SPN" SG_ 2566739454 FlashRedStopLamp 3039;
BA_ "SPN" SG_ 2566739454 FlashMalfunctionIndicatorLamp 3038;
BA_ "SPN" SG_ 2566739454 SuspectParameterNumber 1214;
BA_ "SPN" SG_ 2566739454 FailureModeIdentifier 1215;
BA_ "SPN" SG_ 2566739454 OccurrenceCount 1216;
BA_ "SPN" SG_ 2566739454 SPNConversionMethod 1706;
BA_ "SPN" SG_ 2566739710 ProtectLamp 987;
BA_ "SPN" SG_ 2566739710 AmberWarningLamp 624;
BA_ "SPN" SG_ 2566739710 RedStopLamp 623;
BA_ "SPN" SG_ 2566739710 MalfunctionIndicatorLamp 1213;
BA_ "SPN" SG_ 2566739710 FlashProtectLamp 3041;
BA_ "SPN" SG_ 2566739710 FlashAmberWarningLamp 3040;
BA_ "SPN" SG_ 2566739710 FlashRedStopLamp 3039;
BA_ "SPN" SG_ 2566739710 FlashMalfunctionIndicatorLamp 3038;
BA_ "SPN" SG_ 2566739710 SuspectParameterNumber 1214;
BA_ "SPN" SG_ 2566739710 FailureModeIdentifier 1215;
BA_ "SPN" SG_ 2566739710 OccurrenceCount 1216;
BA_ "SPN" SG_ 2566739710 SPNConversionMethod 1706;
BA_ "SPN" SG_ 2566739966 ProtectLamp 987;
BA_ "SPN" SG_ 2566739966 AmberWarningLamp 624;
BA_ "SPN" SG_ 2566739966 RedStopLamp 623;
BA_ "SPN" SG_ 2566739966 MalfunctionIndicatorLamp 1213;
BA_ "SPN" SG_ 2566739966 FlashProtectLamp 3041;
BA_ "SPN" SG_ 2566739966 FlashAmberWarningLamp 3040;
BA_ "SPN" SG_ 2566739966 FlashRedStopLamp 3039;
BA_ "SPN" SG_ 2566739966 FlashMalfunctionIndicatorLamp 3038;
BA_ "SPN" SG_ 2566739966 SuspectParameterNumber 1214;
BA_ "SPN" SG_ 2566739966 FailureModeIdentifier 1215;
BA_ "SPN" SG_ 2566739966 OccurrenceCount 1216;
BA_ "SPN" SG_ 2566739966 SPNConversionMethod 1706;
BA_ "SPN" SG_ 2566740222 ProtectLamp 987;
BA_ "SPN" SG_ 2566740222 AmberWarningLamp 624;
BA_ "SPN" SG_ 2566740222 RedStopLamp 623;
BA_ "SPN" SG_ 2566740222 MalfunctionIndicatorLamp 1213;
BA_ "SPN" SG_ 2566740222 FlashProtectLamp 3041;
BA_ "SPN" SG_ 2566740222 FlashAmberWarningLamp 3040;
BA_ "SPN" SG_ 2566740222 FlashRedStopLamp 3039;
BA_ "SPN" SG_ 2566740222 FlashMalfunctionIndicatorLamp 3038;
BA_ "SPN" SG_ 2566740222 SuspectParameterNumber 1214;
BA_ "SPN" SG_ 2566740222 FailureModeIdentifier 1215;
BA_ "SPN" SG_ 2566740222 OccurrenceCount 1216;
BA_ "SPN" SG_ 2566740222 SPNConversionMethod 1706;
BA_ "SPN" SG_ 2566740478 ProtectLamp 987;
BA_ "SPN" SG_ 2566740478 AmberWarningLamp 624;
BA_ "SPN" SG_ 2566740478 RedStopLamp 623;
BA_ "SPN" SG_ 2566740478 MalfunctionIndicatorLamp 1213;
BA_ "SPN" SG_ 2566740478 FlashProtectLamp 3041;
BA_ "SPN" SG_ 2566740478 FlashAmberWarningLamp 3040;
BA_ "SPN" SG_ 2566740478 FlashRedStopLamp 3039;
BA_ "SPN" SG_ 2566740478 FlashMalfunctionIndicatorLamp 3038;
BA_ "SPN" SG_ 2566740478 SuspectParameterNumber 1214;
BA_ "SPN" SG_ 2566740478 FailureModeIdentifier 1215;
BA_ "SPN" SG_ 2566740478 OccurrenceCount 1216;
BA_ "SPN" SG_ 2566740478 SPNConversionMethod 1706;
BA_ "SPN" SG_ 2566740734 ProtectLamp 987;
BA_ "SPN" SG_ 2566740734 AmberWarningLamp 624;
BA_ "SPN" SG_ 2566740734 RedStopLamp 623;
BA_ "SPN" SG_ 2566740734 MalfunctionIndicatorLamp 1213;
BA_ "SPN" SG_ 2566740734 FlashProtectLamp 3041;
BA_ "SPN" SG_ 2566740734 FlashAmberWarningLamp 3040;
BA_ "SPN" SG_ 2566740734 FlashRedStopLamp 3039;
BA_ "SPN" SG_ 2566740734 FlashMalfunctionIndicatorLamp 3038;
BA_ "SPN" SG_ 2566740734 SuspectParameterNumber 1214;
BA_ "SPN" SG_ 2566740734 FailureModeIdentifier 1215;
BA_ "SPN" SG_ 2566740734 OccurrenceCount 1216;
BA_ "SPN" SG_ 2566740734 SPNConversionMethod 1706;
BA_ "SPN" SG_ 2566740990 ProtectLamp 987;
BA_ "SPN" SG_ 2566740990 AmberWarningLamp 624;
BA_ "SPN" SG_ 2566740990 RedStopLamp 623;
BA_ "SPN" SG_ 2566740990 MalfunctionIndicatorLamp 1213;
BA_ "SPN" SG_ 2566740990 FlashProtectLamp 3041;
BA_ "SPN" SG_ 2566740990 FlashAmberWarningLamp 3040;
BA_ "SPN" SG_ 2566740990 FlashRedStopLamp 3039;
BA_ "SPN" SG_ 2566740990 FlashMalfunctionIndicatorLamp 3038;
BA_ "SPN" SG_ 2566740990 SuspectParameterNumber 1214;
BA_ "SPN" SG_ 2566740990 FailureModeIdentifier 1215;
BA_ "SPN" SG_ 2566740990 OccurrenceCount 1216;
BA_ "SPN" SG_ 2566740990 SPNConversionMethod 1706;
BA_ "SPN" SG_ 2566741246 ProtectLamp 987;
BA_ "SPN" SG_ 2566741246 AmberWarningLamp 624;
BA_ "SPN" SG_ 2566741246 RedStopLamp 623;
BA_ "SPN" SG_ 2566741246 MalfunctionIndicatorLamp 1213;
BA_ "SPN" SG_ 2566741246 FlashProtectLamp 3041;
BA_ "SPN" SG_ 2566741246 FlashAmberWarningLamp 3040;
BA_ "SPN" SG_ 2566741246 FlashRedStopLamp 3039;
BA_ "SPN" SG_ 2566741246 FlashMalfunctionIndicatorLamp 3038;
BA_ "SPN" SG_ 2566741246 SuspectParameterNumber 1214;
BA_ "SPN" SG_ 2566741246 FailureModeIdentifier 1215;
BA_ "SPN" SG_ 2566741246 OccurrenceCount 1216;
BA_ "SPN" SG_ 2566741246 SPNConversionMethod 1706;
BA_ "SPN" SG_ 2566741502 ProtectLamp 987;
BA_ "SPN" SG_ 2566741502 AmberWarningLamp 624;
BA_ "SPN" SG_ 2566741502 RedStopLamp 623;
BA_ "SPN" SG_ 2566741502 MalfunctionIndicatorLamp 1213;
BA_ "SPN" SG_ 2566741502 FlashProtectLamp 3041;
BA_ "SPN" SG_ 2566741502 FlashAmberWarningLamp 3040;
BA_ "SPN" SG_ 2566741502 FlashRedStopLamp 3039;
BA_ "SPN" SG_ 2566741502 FlashMalfunctionIndicatorLamp 3038;
BA_ "SPN" SG_ 2566741502 SuspectParameterNumber 1214;
BA_ "SPN" SG_ 2566741502 FailureModeIdentifier 1215;
BA_ "SPN" SG_ 2566741502 OccurrenceCount 1216;
BA_ "SPN" SG_ 2566741502 SPNConversionMethod 1706;
BA_ "SPN" SG_ 2566741758 ProtectLamp 987;
BA_ "SPN" SG_ 2566741758 AmberWarningLamp 624;
BA_ "SPN" SG_ 2566741758 RedStopLamp 623;
BA_ "SPN" SG_ 2566741758 MalfunctionIndicatorLamp 1213;
BA_ "SPN" SG_ 2566741758 FlashProtectLamp 3041;
BA_ "SPN" SG_ 2566741758 FlashAmberWarningLamp 3040;
BA_ "SPN" SG_ 2566741758 FlashRedStopLamp 3039;
BA_ "SPN" SG_ 2566741758 FlashMalfunctionIndicatorLamp 3038;
BA_ "SPN" SG_ 2566741758 SuspectParameterNumber 1214;
BA_ "SPN" SG_ 2566741758 FailureModeIdentifier 1215;
BA_ "SPN" SG_ 2566741758 OccurrenceCount 1216;
BA_ "SPN" SG_ 2566741758 SPNConversionMethod 1706;
BA_ "SPN" SG_ 2566742014 ProtectLamp 987;
BA_ "SPN" SG_ 2566742014 AmberWarningLamp 624;
BA_ "SPN" SG_ 2566742014 RedStopLamp 623;
BA_ "SPN" SG_ 2566742014 MalfunctionIndicatorLamp 1213;
BA_ "SPN" SG_ 2566742014 FlashProtectLamp 3041;
BA_ "SPN" SG_ 2566742014 FlashAmberWarningLamp 3040;
BA_ "SPN" SG_ 2566742014 FlashRedStopLamp 3039;
BA_ "SPN" SG_ 2566742014 FlashMalfunctionIndicatorLamp 3038;
BA_ "SPN" SG_ 2566742014 SuspectParameterNumber 1214;
BA_ "SPN" SG_ 2566742014 FailureModeIdentifier 1215;
BA_ "SPN" SG_ 2566742014 OccurrenceCount 1216;
BA_ "SPN" SG_ 2566742014 SPNConversionMethod 1706;
BA_ "SPN" SG_ 2566742270 SuspectParameterNumber 1214;
BA_ "SPN" SG_ 2566742270 FailureModeIdentifier 1215;
BA_ "SPN" SG_ 2566742270 FailureSpecificB1Counter 4147;
BA_ "SPN" SG_ 2566742526 SystemCumulativeContinuousMITime 4145;
BA_ "SPN" SG_ 2566742526 SystemGreatestB1Counter 4146;
BA_ "SPN" SG_ 2566742782 GloblTechnicalRegulationDescript 4144;
BA_ "SPN" SG_ 2566743038 SystemNonRoadworthyComponentCnt 4139;
BA_ "SPN" SG_ 2566743038 SystemMalfnctnIndictrActvtnMode 4142;
BA_ "SPN" SG_ 2566743038 SysMalfctIndictrDisplayStrategy 4141;
BA_ "SPN" SG_ 2566743038 SystemCntnsMalfunctionIndicator 4140;
BA_ "SPN" SG_ 2566743038 SystemIncompleteMonitorCount 4143;
BA_ "SPN" SG_ 2566743294 VehicleCurrentMIAccumulatedTime 4138;
BA_ "SPN" SG_ 2566743550 Aftertreatment1FuelPressure2 4077;
BA_ "SPN" SG_ 2566743550 Aftrtrtmnt1FuelPumpRelayControl 5423;
BA_ "SPN" SG_ 2566743550 Aft1FuelFlwDiverterVlvCtrl 5424;
BA_ "SPN" SG_ 2566743550 Aftrtrtmnt1FuelPressure2ActrCtrl 5425;
BA_ "SPN" SG_ 2566743550 Aft1HydrocarbonDoserIntkFuelTemp 5456;
BA_ "SPN" SG_ 2566743806 EngineCoolantTemperature2 4076;
BA_ "SPN" SG_ 2566743806 EngCoolntPumpOutletTemperature 4193;
BA_ "SPN" SG_ 2566743806 EngineCoolantThermostatOpening 4194;
BA_ "SPN" SG_ 2566743806 EngExhstValveActSysOilTemp 4288;
BA_ "SPN" SG_ 2566743806 EngExhstGasRecirc1MixerIntkTemp 5020;
BA_ "SPN" SG_ 2566743806 EngineCoolantTemperature3 6209;
BA_ "SPN" SG_ 2566744062 ZeroNetVehicleWeightChange 4075;
BA_ "SPN" SG_ 2499635454 GrossCombinationWeight 417;
BA_ "SPN" SG_ 2499635454 NetVehicleWeightChange 413;
BA_ "SPN" SG_ 2633853438 AxleGroupLocation 4074;
BA_ "SPN" SG_ 2633853438 AdditionalAxleGroupLocation 5936;
BA_ "SPN" SG_ 2633853438 AxleGroupEmptyWeightCalibration 408;
BA_ "SPN" SG_ 2633853438 AxleGroupFullWeightCalibration 407;
BA_ "SPN" SG_ 2499635966 AxleGroupLocation 4073;
BA_ "SPN" SG_ 2499635966 AdditionalAxleGroupLocation 5935;
BA_ "SPN" SG_ 2499635966 AxleGroupWeight 409;
BA_ "SPN" SG_ 2566745086 SoleOrFrwdMostSteerAxlGrpWghtAvl 4059;
BA_ "SPN" SG_ 2566745086 LiftAxleGroupWeightAvailable 4060;
BA_ "SPN" SG_ 2566745086 SoleOrFrwdMostDrvAxlGrpWeightAvl 4061;
BA_ "SPN" SG_ 2566745086 TagAxleGroupWeightAvailable 4062;
BA_ "SPN" SG_ 2566745086 AddtnlTractorAxlGroupWeightAvail 4063;
BA_ "SPN" SG_ 2566745086 TrailerAAxleGroupWeightAvailable 4064;
BA_ "SPN" SG_ 2566745086 TrailerBAxleGroupWeightAvailable 4065;
BA_ "SPN" SG_ 2566745086 TrailerCAxleGroupWeightAvailable 4066;
BA_ "SPN" SG_ 2566745086 TrailerDAxleGroupWeightAvailable 4067;
BA_ "SPN" SG_ 2566745086 TrailerEAxleGroupWeightAvailable 4068;
BA_ "SPN" SG_ 2566745086 TrailerFAxleGroupWeightAvailable 4069;
BA_ "SPN" SG_ 2566745086 TrailerGAxleGroupWeightAvailable 4070;
BA_ "SPN" SG_ 2566745086 TrailerHAxleGroupWeightAvailable 4071;
BA_ "SPN" SG_ 2566745086 AddtnlTrailerAxlGroupWeightAvail 4072;
BA_ "SPN" SG_ 2566745086 RearSteerAxleGroupWeightAvail 5933;
BA_ "SPN" SG_ 2566745086 RearDriveAxleGroupWeightAvail 5934;
BA_ "SPN" SG_ 2566745342 Aftrtrtmnt2SecondaryAirDiffPress 3833;
BA_ "SPN" SG_ 2566745342 Aftrtrtmnt2SecAirTemperature 3834;
BA_ "SPN" SG_ 2566745342 Aftrtrtmnt2SecAirMassFlwRate 3835;
BA_ "SPN" SG_ 2566745342 Aftrtrtmnt2SecondaryAirPressure 3838;
BA_ "SPN" SG_ 2566745598 Aftrtrtmnt1SecondaryAirDiffPress 3830;
BA_ "SPN" SG_ 2566745598 Aftrtrtmnt1SecAirTemperature 3831;
BA_ "SPN" SG_ 2566745598 Aftrtrtmnt1SecAirMassFlwRate 3832;
BA_ "SPN" SG_ 2566745598 Aftrtrtmnt1SecondaryAirPressure 3837;
BA_ "SPN" SG_ 2566745854 Aft1DslExhstFldAvrgCnsmptn 3826;
BA_ "SPN" SG_ 2566745854 Aft1SCRCmdedDslExhstFldCnsmptn 3828;
BA_ "SPN" SG_ 2566745854 Aftrtrtmnt1SCRCnvrsnEfficiency 4364;
BA_ "SPN" SG_ 2566745854 AftSCROprtrIndcmntActvTrvledDist 5463;
BA_ "SPN" SG_ 2566745854 Aftrtrtmnt1SCRSystemSulfationLvl 7504;
BA_ "SPN" SG_ 2566746110 EngExhstGasRecirc1Valve2Ctrl 3821;
BA_ "SPN" SG_ 2566746110 EngExhstGasRecirc1CoolIntkTemp 4750;
BA_ "SPN" SG_ 2566746110 EngExhstGasRecirc1ClIntkAbsPress 4751;
BA_ "SPN" SG_ 2566746110 EngExhstGasRecirculation1CoolEff 4752;
BA_ "SPN" SG_ 2566746366 RetractStatusOfRamp1 3810;
BA_ "SPN" SG_ 2566746366 EnableStatusOfRamp1 3811;
BA_ "SPN" SG_ 2566746366 MovementStatusOfRamp1 3812;
BA_ "SPN" SG_ 2566746366 RetractStatusOfRamp2 3813;
BA_ "SPN" SG_ 2566746366 EnableStatusOfRamp2 3814;
BA_ "SPN" SG_ 2566746366 MovementStatusOfRamp2 3815;
BA_ "SPN" SG_ 2566746366 RetractStatusOfRamp3 3816;
BA_ "SPN" SG_ 2566746366 EnableStatusOfRamp3 3817;
BA_ "SPN" SG_ 2566746366 MovementStatusOfRamp3 3818;
BA_ "SPN" SG_ 2566746366 RetractStatusOfRamp4 4454;
BA_ "SPN" SG_ 2566746366 EnableStatusOfRamp4 4455;
BA_ "SPN" SG_ 2566746366 MovementStatusOfRamp4 4456;
BA_ "SPN" SG_ 2566746366 RetractStatusOfRamp5 4457;
BA_ "SPN" SG_ 2566746366 EnableStatusOfRamp5 4458;
BA_ "SPN" SG_ 2566746366 MovementStatusOfRamp5 4459;
BA_ "SPN" SG_ 2566746622 TractorBrakeStrokeAxle1Left 3785;
BA_ "SPN" SG_ 2566746622 TractorBrakeStrokeAxle1Right 3786;
BA_ "SPN" SG_ 2566746622 TractorBrakeStrokeAxle2Left 3787;
BA_ "SPN" SG_ 2566746622 TractorBrakeStrokeAxle2Right 3788;
BA_ "SPN" SG_ 2566746622 TractorBrakeStrokeAxle3Left 3789;
BA_ "SPN" SG_ 2566746622 TractorBrakeStrokeAxle3Right 3790;
BA_ "SPN" SG_ 2566746622 TractorBrakeStrokeAxle4Left 3791;
BA_ "SPN" SG_ 2566746622 TractorBrakeStrokeAxle4Right 3792;
BA_ "SPN" SG_ 2566746622 TractorBrakeStrokeAxle5Left 3793;
BA_ "SPN" SG_ 2566746622 TractorBrakeStrokeAxle5Right 3794;
BA_ "SPN" SG_ 2566746622 TrailerBrakeStrokeAxle1Left 3795;
BA_ "SPN" SG_ 2566746622 TrailerBrakeStrokeAxle1Right 3796;
BA_ "SPN" SG_ 2566746622 TrailerBrakeStrokeAxle2Left 3797;
BA_ "SPN" SG_ 2566746622 TrailerBrakeStrokeAxle2Right 3798;
BA_ "SPN" SG_ 2566746622 TrailerBrakeStrokeAxle3Left 3799;
BA_ "SPN" SG_ 2566746622 TrailerBrakeStrokeAxle3Right 3800;
BA_ "SPN" SG_ 2566746622 TrailerBrakeStrokeAxle4Left 3801;
BA_ "SPN" SG_ 2566746622 TrailerBrakeStrokeAxle4Right 3802;
BA_ "SPN" SG_ 2566746622 TrailerBrakeStrokeAxle5Left 3803;
BA_ "SPN" SG_ 2566746622 TrailerBrakeStrokeAxle5Right 3804;
BA_ "SPN" SG_ 2566746878 EngineSparkPlug21 1314;
BA_ "SPN" SG_ 2566746878 EngineSparkPlug22 1315;
BA_ "SPN" SG_ 2566746878 EngineSparkPlug23 1316;
BA_ "SPN" SG_ 2566746878 EngineSparkPlug24 1317;
BA_ "SPN" SG_ 2566747134 EngineSparkPlug17 1310;
BA_ "SPN" SG_ 2566747134 EngineSparkPlug18 1311;
BA_ "SPN" SG_ 2566747134 EngineSparkPlug19 1312;
BA_ "SPN" SG_ 2566747134 EngineSparkPlug20 1313;
BA_ "SPN" SG_ 2566747390 EngineSparkPlug13 1306;
BA_ "SPN" SG_ 2566747390 EngineSparkPlug14 1307;
BA_ "SPN" SG_ 2566747390 EngineSparkPlug15 1308;
BA_ "SPN" SG_ 2566747390 EngineSparkPlug16 1309;
BA_ "SPN" SG_ 2566747646 EngineSparkPlug9 1302;
BA_ "SPN" SG_ 2566747646 EngineSparkPlug10 1303;
BA_ "SPN" SG_ 2566747646 EngineSparkPlug11 1304;
BA_ "SPN" SG_ 2566747646 EngineSparkPlug12 1305;
BA_ "SPN" SG_ 2566747902 EngineSparkPlug5 1298;
BA_ "SPN" SG_ 2566747902 EngineSparkPlug6 1299;
BA_ "SPN" SG_ 2566747902 EngineSparkPlug7 1300;
BA_ "SPN" SG_ 2566747902 EngineSparkPlug8 1301;
BA_ "SPN" SG_ 2566748158 EngineSparkPlug1 1294;
BA_ "SPN" SG_ 2566748158 EngineSparkPlug2 1295;
BA_ "SPN" SG_ 2566748158 EngineSparkPlug3 1296;
BA_ "SPN" SG_ 2566748158 EngineSparkPlug4 1297;
BA_ "SPN" SG_ 2566748414 Aftrtrtmnt2DslPFTripFuelUsed 3741;
BA_ "SPN" SG_ 2566748414 Aftrtrtmnt2DslPFTripActvRegenTme 3742;
BA_ "SPN" SG_ 2566748414 Aftrtrtmnt2DslPFTripDisabledTime 3743;
BA_ "SPN" SG_ 2566748414 Aft2DslPFTrpNoOfActvRegens 3744;
BA_ "SPN" SG_ 2566748414 Aft2DslPFTrpPassiveRegenTme 3745;
BA_ "SPN" SG_ 2566748414 Aft2DslPFTrpNoOfPassiveRegens 3746;
BA_ "SPN" SG_ 2566748414 Aft2DslPFTrpNoOfActRegenInhbtRqs 3747;
BA_ "SPN" SG_ 2566748414 Aft2DslPFTrpNoOfActvRegenManRqs 3748;
BA_ "SPN" SG_ 2566748670 Aftrtrtmnt1DslPFTripFuelUsed 3733;
BA_ "SPN" SG_ 2566748670 Aftrtrtmnt1DslPFTripActvRegenTme 3734;
BA_ "SPN" SG_ 2566748670 Aftrtrtmnt1DslPFTripDisabledTime 3735;
BA_ "SPN" SG_ 2566748670 Aft1DslPFTrpNoOfActvRegens 3736;
BA_ "SPN" SG_ 2566748670 Aft1DslPFTrpPassiveRegenTme 3737;
BA_ "SPN" SG_ 2566748670 Aft1DslPFTrpNoOfPassiveRegens 3738;
BA_ "SPN" SG_ 2566748670 Aft1DslPFTrpNoOfActRegenInhbtRqs 3739;
BA_ "SPN" SG_ 2566748670 Aft1DslPFTrpNoOfActvRegenManRqs 3740;
BA_ "SPN" SG_ 2566748926 Aftrtrtmnt2DslPFSootLoadPercent 3722;
BA_ "SPN" SG_ 2566748926 Aftrtrtmnt2DslPFAshLoadPercent 3723;
BA_ "SPN" SG_ 2566748926 Aft2DslPFTmeSncLastActvRegen 3724;
BA_ "SPN" SG_ 2566748926 Aft2DslPFSootLoadRegenTrshld 5467;
BA_ "SPN" SG_ 2566749182 Aftrtrtmnt1DslPFSootLoadPercent 3719;
BA_ "SPN" SG_ 2566749182 Aftrtrtmnt1DslPFAshLoadPercent 3720;
BA_ "SPN" SG_ 2566749182 Aft1DslPFTmeSncLastActvRegen 3721;
BA_ "SPN" SG_ 2566749182 Aft1DslPFSootLoadRegenTrshld 5466;
BA_ "SPN" SG_ 2566749438 DieselParticulateFilterLampCmd 3697;
BA_ "SPN" SG_ 2566749438 DslPFActvRegenAvailabilityStatus 8857;
BA_ "SPN" SG_ 2566749438 AftrtrtmntDslPFPassiveRegenStat 3699;
BA_ "SPN" SG_ 2566749438 AftrtrtmntDslPFActvRegenStatus 3700;
BA_ "SPN" SG_ 2566749438 AftrtrtmntDslPFStatus 3701;
BA_ "SPN" SG_ 2566749438 DslPFActvRegenInhbtdStatus 3702;
BA_ "SPN" SG_ 2566749438 DslPFActvRegenInhbtdDTInhbtSw 3703;
BA_ "SPN" SG_ 2566749438 DslPFActRegenInhbtdDTCltchDiseng 3704;
BA_ "SPN" SG_ 2566749438 DslPFActRegenInhbtdDTSrvcBrkActv 3705;
BA_ "SPN" SG_ 2566749438 DslPFActvRegenInhbtdDTPTOActv 3706;
BA_ "SPN" SG_ 2566749438 DPFActRegenInhbtdDTAcclPdlOffIdl 3707;
BA_ "SPN" SG_ 2566749438 DslPFActvRegenInhbtdDTOutOfNtrl 3708;
BA_ "SPN" SG_ 2566749438 DPFActRegInhDTVhclSpdAbvAllwdSpd 3709;
BA_ "SPN" SG_ 2566749438 DPFActRegenInhbtdDTPrkBrkNotSet 3710;
BA_ "SPN" SG_ 2566749438 DPFActRegenInhbtdDTLowExhstTemp 3711;
BA_ "SPN" SG_ 2566749438 DslPFActRegenInhbtdDTSysFaultAct 3712;
BA_ "SPN" SG_ 2566749438 DslPFActvRegenInhbtdDTSysTimeout 3713;
BA_ "SPN" SG_ 2566749438 DPFActRegenInhbtdDTTmprySysLckt 3714;
BA_ "SPN" SG_ 2566749438 DPFActRegenInhbtdDTPrmntSysLckt 3715;
BA_ "SPN" SG_ 2566749438 DPFActRegInhbtdDTEngNotWarmedUp 3716;
BA_ "SPN" SG_ 2566749438 DPFActRegInhDTVhclSpdBlwAllwdSpd 3717;
BA_ "SPN" SG_ 2566749438 DslPFAutoActvRegenInitConf 3718;
BA_ "SPN" SG_ 2566749438 ExhstSystemHghTemperatureLampCmd 3698;
BA_ "SPN" SG_ 2566749438 DslPFActvRegenForcedStatus 4175;
BA_ "SPN" SG_ 2566749438 HydrocarbonDoserPurgingEnable 5504;
BA_ "SPN" SG_ 2566749438 DPFActRegenInhbtdDTLowExhstPress 5629;
BA_ "SPN" SG_ 2566749438 Aft1DPFConditionsNotMetForActReg 3750;
BA_ "SPN" SG_ 2566749950 LeftHeadlampDynamicBendingLight 3691;
BA_ "SPN" SG_ 2566749950 RightHeadlampDynamicBendingLight 3692;
BA_ "SPN" SG_ 2566749950 LeftHeadlampLightDistribution 3693;
BA_ "SPN" SG_ 2566749950 RightHeadlampLightDistribution 3694;
BA_ "SPN" SG_ 2566750206 MaxCrankAttmptsPerStartAttmpt 3670;
BA_ "SPN" SG_ 2566750206 NoOfCombustionCyclesForAveraging 6394;
BA_ "SPN" SG_ 2566750206 EngineConfIdentification 6395;
BA_ "SPN" SG_ 2566750206 TrnsmIdlGvrnrFuelngInhbtSupp 7830;
BA_ "SPN" SG_ 2566750462 ProtectLamp 987;
BA_ "SPN" SG_ 2566750462 AmberWarningLamp 624;
BA_ "SPN" SG_ 2566750462 RedStopLamp 623;
BA_ "SPN" SG_ 2566750462 MalfunctionIndicatorLamp 1213;
BA_ "SPN" SG_ 2566750462 FlashProtectLamp 3041;
BA_ "SPN" SG_ 2566750462 FlashAmberWarningLamp 3040;
BA_ "SPN" SG_ 2566750462 FlashRedStopLamp 3039;
BA_ "SPN" SG_ 2566750462 FlashMalfunctionIndicatorLamp 3038;
BA_ "SPN" SG_ 2566750462 SuspectParameterNumber 1214;
BA_ "SPN" SG_ 2566750462 FailureModeIdentifier 1215;
BA_ "SPN" SG_ 2566750462 OccurrenceCount 1216;
BA_ "SPN" SG_ 2566750462 SPNConversionMethod 1706;
BA_ "SPN" SG_ 2499641854 EGR1CoolerBypassActuatorPostion 3672;
BA_ "SPN" SG_ 2566750974 ProtectLamp 987;
BA_ "SPN" SG_ 2566750974 AmberWarningLamp 624;
BA_ "SPN" SG_ 2566750974 RedStopLamp 623;
BA_ "SPN" SG_ 2566750974 MalfunctionIndicatorLamp 1213;
BA_ "SPN" SG_ 2566750974 FlashProtectLamp 3041;
BA_ "SPN" SG_ 2566750974 FlashAmberWarningLamp 3040;
BA_ "SPN" SG_ 2566750974 FlashRedStopLamp 3039;
BA_ "SPN" SG_ 2566750974 FlashMalfunctionIndicatorLamp 3038;
BA_ "SPN" SG_ 2566750974 SuspectParameterNumber 1214;
BA_ "SPN" SG_ 2566750974 FailureModeIdentifier 1215;
BA_ "SPN" SG_ 2566750974 OccurrenceCount 1216;
BA_ "SPN" SG_ 2566750974 SPNConversionMethod 1706;
BA_ "SPN" SG_ 2566751230 TransferCaseStatus 3645;
BA_ "SPN" SG_ 2566751230 TransferCaseDirectionStatus 8849;
BA_ "SPN" SG_ 2566751486 EngIntkValveActOilPressForCyl17 3640;
BA_ "SPN" SG_ 2566751486 EngIntkValveActOilPressForCyl18 3641;
BA_ "SPN" SG_ 2566751486 EngIntkValveActOilPressForCyl19 3642;
BA_ "SPN" SG_ 2566751486 EngIntkValveActOilPressForCyl20 3643;
BA_ "SPN" SG_ 2566751742 EngIntkValveActOilPressForCyl13 3636;
BA_ "SPN" SG_ 2566751742 EngIntkValveActOilPressForCyl14 3637;
BA_ "SPN" SG_ 2566751742 EngIntkValveActOilPressForCyl15 3638;
BA_ "SPN" SG_ 2566751742 EngIntkValveActOilPressForCyl16 3639;
BA_ "SPN" SG_ 2566751998 EngIntkValveActOilPressForCyl9 3632;
BA_ "SPN" SG_ 2566751998 EngIntkValveActOilPressForCyl10 3633;
BA_ "SPN" SG_ 2566751998 EngIntkValveActOilPressForCyl11 3634;
BA_ "SPN" SG_ 2566751998 EngIntkValveActOilPressForCyl12 3635;
BA_ "SPN" SG_ 2566752254 EngIntkValveActOilPressForCyl5 3628;
BA_ "SPN" SG_ 2566752254 EngIntkValveActOilPressForCyl6 3629;
BA_ "SPN" SG_ 2566752254 EngIntkValveActOilPressForCyl7 3630;
BA_ "SPN" SG_ 2566752254 EngIntkValveActOilPressForCyl8 3631;
BA_ "SPN" SG_ 2566752510 EngIntkValveActOilPressForCyl1 3624;
BA_ "SPN" SG_ 2566752510 EngIntkValveActOilPressForCyl2 3625;
BA_ "SPN" SG_ 2566752510 EngIntkValveActOilPressForCyl3 3626;
BA_ "SPN" SG_ 2566752510 EngIntkValveActOilPressForCyl4 3627;
BA_ "SPN" SG_ 2566752766 VehicleRoll 3623;
BA_ "SPN" SG_ 2633861886 NumberOfJ2012DTCs 3619;
BA_ "SPN" SG_ 2633861886 J2012DTC 3620;
BA_ "SPN" SG_ 2633861886 J2012DTCStatus 3621;
BA_ "SPN" SG_ 2633861886 J2012DTCOccurrenceCount 3622;
BA_ "SPN" SG_ 2566753278 Aftrtrtmnt2DslPFIntkPressure 3611;
BA_ "SPN" SG_ 2566753278 Aftrtrtmnt2DslPFOtltPressure 3612;
BA_ "SPN" SG_ 2566753534 Aftrtrtmnt1DslPFIntkPressure 3609;
BA_ "SPN" SG_ 2566753534 Aftrtrtmnt1DslPFOtltPressure 3610;
BA_ "SPN" SG_ 2566753790 UtilityTotalKVArHoursExport 3595;
BA_ "SPN" SG_ 2566753790 UtilityTotalKVArHoursImport 3596;
BA_ "SPN" SG_ 2566754046 GeneratorTotalKVArHoursExport 3593;
BA_ "SPN" SG_ 2566754046 GeneratorTotalKVArHoursImport 3594;
BA_ "SPN" SG_ 2566754302 GeneratorTotalPercentKW 3590;
BA_ "SPN" SG_ 2566754302 GeneratorTotalPercentKVA 3591;
BA_ "SPN" SG_ 2566754302 GeneratorTotalPercentKVAr 3592;
BA_ "SPN" SG_ 2566754558 AETCDataCollectionStandard 3558;
BA_ "SPN" SG_ 2566754558 NumberOfAETCDataPoints 3559;
BA_ "SPN" SG_ 2566754814 GeneratorCircuitBreakerStatus 3545;
BA_ "SPN" SG_ 2566754814 UtilityCircuitBreakerStatus 3546;
BA_ "SPN" SG_ 2566754814 AutomaticTransferSwitchStatus 3547;
BA_ "SPN" SG_ 2566754814 EngineSpeedGovernorMode 7840;
BA_ "SPN" SG_ 2566754814 BusTieBreaker1 7841;
BA_ "SPN" SG_ 2566754814 BusTieBreaker2 7842;
BA_ "SPN" SG_ 2566754814 EngineLoadGroup 7843;
BA_ "SPN" SG_ 2365428478 EngineOperatingState 3543;
BA_ "SPN" SG_ 2365428478 FuelPumpPrimerControl 4082;
BA_ "SPN" SG_ 2365428478 EngineStarterMotorRelayControl 6385;
BA_ "SPN" SG_ 2365428478 TimeRemainingInEngOperatingState 3544;
BA_ "SPN" SG_ 2365428478 EngineFuelShutoffVentControl 3608;
BA_ "SPN" SG_ 2365428478 EngineFuelShutoff1Control 632;
BA_ "SPN" SG_ 2365428478 EngineFuelShutoff2Control 2807;
BA_ "SPN" SG_ 2365428478 EngFuelShutoffValveLeakTestCtrl 3601;
BA_ "SPN" SG_ 2365428478 EngineOilPrimingPumpControl 3589;
BA_ "SPN" SG_ 2365428478 EngineOilPreHeaterControl 3602;
BA_ "SPN" SG_ 2365428478 EngElectrclSystemPwrConservCtrl 3603;
BA_ "SPN" SG_ 2365428478 EnginePreHeaterControl 3604;
BA_ "SPN" SG_ 2365428478 EngineCoolantPumpControl 3605;
BA_ "SPN" SG_ 2365428478 EngineControlledShutdownRequest 3606;
BA_ "SPN" SG_ 2365428478 EngineEmrgncyShutdownIndication 3607;
BA_ "SPN" SG_ 2365428478 EngColdAmbientElevatedIdleStatus 6884;
BA_ "SPN" SG_ 2365428478 EngineDesiredTorqueRequest 6807;
BA_ "SPN" SG_ 2365428478 EngineDerateRequest 3644;
BA_ "SPN" SG_ 2365428734 RequestedEngineControlMode 3542;
BA_ "SPN" SG_ 2365428734 GeneratorCtrlNotInAutoStartState 3567;
BA_ "SPN" SG_ 2365428734 GenNotReadyToAutoParallelState 3568;
BA_ "SPN" SG_ 2365428734 GeneratorAlternatorEfficiency 4078;
BA_ "SPN" SG_ 2365428734 GeneratorGoverningSpeedCommand 4079;
BA_ "SPN" SG_ 2365428734 GeneratorFrequencySelection 4080;
BA_ "SPN" SG_ 2365428734 EngineSpeedGovernorGainAdjust 5567;
BA_ "SPN" SG_ 2365428734 EngineSpeedGovernorDroop 5568;
BA_ "SPN" SG_ 2566755582 EngExhstGasRecirc1ValvePos 27;
BA_ "SPN" SG_ 2566755582 EngExhstGasRecirc1Valve2Pos 3822;
BA_ "SPN" SG_ 2566755582 EngCrankCsBrearOilSeparatorSpd 5444;
BA_ "SPN" SG_ 2566755582 EngIntakeManifoldCmdedPressure 5312;
BA_ "SPN" SG_ 2566755838 TrnsmOilFilterRestrictionSw 3359;
BA_ "SPN" SG_ 2566755838 TransmissionOilLevelSwitch 3533;
BA_ "SPN" SG_ 2566755838 TransmissionOverheatIndicator 5345;
BA_ "SPN" SG_ 2566755838 TransmissionTorqueCnvOilOtltTemp 3823;
BA_ "SPN" SG_ 2566755838 TransmissionOilLifeRemaining 4177;
BA_ "SPN" SG_ 2566755838 TransmissionOilTemperature2 5913;
BA_ "SPN" SG_ 2566755838 TransmissionOilLevel2HighLow 5914;
BA_ "SPN" SG_ 2566755838 TransmissionOilLvl2CntdownTimer 5915;
BA_ "SPN" SG_ 2566755838 TransmissionOilLvl2MeasureStatus 5916;
BA_ "SPN" SG_ 2566756094 EngineFuelSupplyFlowRate 2773;
BA_ "SPN" SG_ 2566756094 EngineFuelReturnFlowRate 2774;
BA_ "SPN" SG_ 2566756350 EngineFuelSupplyTemperature 2775;
BA_ "SPN" SG_ 2566756350 EngineFuelReturnTemperature 2776;
BA_ "SPN" SG_ 2566756606 Aftertreatment1TotalFuelUsed 3522;
BA_ "SPN" SG_ 2566756606 Aftrtrtmnt1TotalRegenerationTime 3523;
BA_ "SPN" SG_ 2566756606 Aftertreatment1TotalDisabledTime 3524;
BA_ "SPN" SG_ 2566756606 Aftrtrtmnt1TotalNoOfActvRegens 3525;
BA_ "SPN" SG_ 2566756606 Aft1DslPFTotalPassiveRegenTme 3725;
BA_ "SPN" SG_ 2566756606 Aft1DslPFTotalNoOfPassiveRegens 3726;
BA_ "SPN" SG_ 2566756606 Aft1DPFTotalNoOfActRegenInhbtRqs 3727;
BA_ "SPN" SG_ 2566756606 Aft1DslPFTotalNoOfActRegenManRqs 3728;
BA_ "SPN" SG_ 2566756606 Aft1DPFAvrgTmeBetweenActvRegens 5454;
BA_ "SPN" SG_ 2566756606 Aft1DPFAvrgDistBetweenActvRegens 5827;
BA_ "SPN" SG_ 2566756862 Aftertreatment2TotalFuelUsed 3526;
BA_ "SPN" SG_ 2566756862 Aftrtrtmnt2TotalRegenerationTime 3527;
BA_ "SPN" SG_ 2566756862 Aftertreatment2TotalDisabledTime 3528;
BA_ "SPN" SG_ 2566756862 Aftrtrtmnt2TotalNoOfActvRegens 3529;
BA_ "SPN" SG_ 2566756862 Aft2DslPFTotalPassiveRegenTme 3729;
BA_ "SPN" SG_ 2566756862 Aft2DslPFTotalNoOfPassiveRegens 3730;
BA_ "SPN" SG_ 2566756862 Aft2DPFTotalNoOfActRegenInhbtRqs 3731;
BA_ "SPN" SG_ 2566756862 Aft2DslPFTotalNoOfActRegenManRqs 3732;
BA_ "SPN" SG_ 2566756862 Aft2DPFAvrgTmeBetweenActvRegens 5455;
BA_ "SPN" SG_ 2566756862 Aft2DPFAvrgDistBetweenActvRegens 5828;
BA_ "SPN" SG_ 2566757374 Aftrtrtmnt1DslExhstFldTemp2 3515;
BA_ "SPN" SG_ 2566757374 Aft1DslExhstFldConcentration 3516;
BA_ "SPN" SG_ 2566757374 Aft1DslExhstFldConductivity 3518;
BA_ "SPN" SG_ 2566757374 Aft1DslExhstFldTemp2PrelimFMI 3519;
BA_ "SPN" SG_ 2566757374 Aft1DslExhstFldPropPrelimFMI 3520;
BA_ "SPN" SG_ 2566757374 Aftrtrtmnt1DslExhstFluidProperty 3521;
BA_ "SPN" SG_ 2566757374 DieselExhaustFluidSpeedOfSound 7346;
BA_ "SPN" SG_ 2566757630 SensorSupplyVoltage5 3513;
BA_ "SPN" SG_ 2566757630 SensorSupplyVoltage6 3514;
BA_ "SPN" SG_ 2566757630 SensorSupplyVoltage7 5125;
BA_ "SPN" SG_ 2566757630 SensorSupplyVoltage8 5126;
BA_ "SPN" SG_ 2566757886 SensorSupplyVoltage1 3509;
BA_ "SPN" SG_ 2566757886 SensorSupplyVoltage2 3510;
BA_ "SPN" SG_ 2566757886 SensorSupplyVoltage3 3511;
BA_ "SPN" SG_ 2566757886 SensorSupplyVoltage4 3512;
BA_ "SPN" SG_ 2566758142 Aftertreatment2SupplyAirPressure 3499;
BA_ "SPN" SG_ 2566758142 Aftertreatment2PurgeAirPressure 3500;
BA_ "SPN" SG_ 2566758142 Aftrtrtmnt2AirPressureControl 3501;
BA_ "SPN" SG_ 2566758142 Aftrtrtmnt2AirPressureActrPos 3502;
BA_ "SPN" SG_ 2566758142 Aftertreatment2AirSystemRelay 3506;
BA_ "SPN" SG_ 2566758142 Aftrtrtmnt2AtomizationAirActr 3505;
BA_ "SPN" SG_ 2566758142 Aftertreatment2PurgeAirActuator 3504;
BA_ "SPN" SG_ 2566758142 Aftertreatment2AirEnableActuator 3503;
BA_ "SPN" SG_ 2566758398 Aftertreatment1SupplyAirPressure 3485;
BA_ "SPN" SG_ 2566758398 Aftertreatment1PurgeAirPressure 3486;
BA_ "SPN" SG_ 2566758398 Aftrtrtmnt1AirPressureControl 3487;
BA_ "SPN" SG_ 2566758398 Aftrtrtmnt1AirPressureActrPos 3488;
BA_ "SPN" SG_ 2566758398 Aftertreatment1AirSystemRelay 3492;
BA_ "SPN" SG_ 2566758398 Aftrtrtmnt1AtomizationAirActr 3491;
BA_ "SPN" SG_ 2566758398 Aftertreatment1PurgeAirActuator 3490;
BA_ "SPN" SG_ 2566758398 Aftertreatment1AirEnableActuator 3489;
BA_ "SPN" SG_ 2566758654 Aftertreatment2FuelPressure1 3494;
BA_ "SPN" SG_ 2566758654 Aftertreatment2FuelRate 3495;
BA_ "SPN" SG_ 2566758654 Aftrtrtmnt2FuelPressure1Control 3493;
BA_ "SPN" SG_ 2566758654 Aftertreatment2FuelDrainActuator 4098;
BA_ "SPN" SG_ 2566758654 Aftertreatment2Ignition 3498;
BA_ "SPN" SG_ 2566758654 Aftrtrtmnt2RegenerationStatus 3497;
BA_ "SPN" SG_ 2566758654 Aftertreatment2FuelEnableActr 3496;
BA_ "SPN" SG_ 2566758654 Aftrtrtmnt2FuelInjector1HtrCtrl 4302;
BA_ "SPN" SG_ 2566758910 Aftertreatment1FuelPressure1 3480;
BA_ "SPN" SG_ 2566758910 Aftertreatment1FuelRate 3481;
BA_ "SPN" SG_ 2566758910 Aftrtrtmnt1FuelPressure1Control 3479;
BA_ "SPN" SG_ 2566758910 Aftertreatment1FuelDrainActuator 4097;
BA_ "SPN" SG_ 2566758910 Aftertreatment1Ignition 3484;
BA_ "SPN" SG_ 2566758910 Aftrtrtmnt1RegenerationStatus 3483;
BA_ "SPN" SG_ 2566758910 Aftertreatment1FuelEnableActr 3482;
BA_ "SPN" SG_ 2566758910 Aftrtrtmnt1FuelInjector1HtrCtrl 4301;
BA_ "SPN" SG_ 2432541438 EngFuelValve2IntakeAbsPressure 3466;
BA_ "SPN" SG_ 2432541438 EngineFuelSystem2GasMassFlowRate 3467;
BA_ "SPN" SG_ 2432541438 EngineFuelTemperature2 3468;
BA_ "SPN" SG_ 2432541438 EngFuelValve2OutletAbsPressure 3469;
BA_ "SPN" SG_ 2432541694 EngTurboCmprssorBypssActr1Cmd 3470;
BA_ "SPN" SG_ 2432541694 EngVariableGmtryTurboActr1 641;
BA_ "SPN" SG_ 2432541694 EngTurboCmprssorBypssActr1Pos 3675;
BA_ "SPN" SG_ 2432541694 EngTurboCmprssorBypssActr2Cmd 5369;
BA_ "SPN" SG_ 2432541694 EngTurboCmprBypssActr1DsrdPos 5366;
BA_ "SPN" SG_ 2432541694 EngTurboCmprBypssActr1PrelimFMI 5367;
BA_ "SPN" SG_ 2432541694 EngTurboCmprBypssActr1TempStat 5368;
BA_ "SPN" SG_ 2566759678 EnblSwitchTransferCsOutptShftPTO 3455;
BA_ "SPN" SG_ 2566759678 EnblSwTransmissionOutptShftPTO 3454;
BA_ "SPN" SG_ 2566759678 EnblSwTransmissionInputShftPTO2 3453;
BA_ "SPN" SG_ 2566759678 EnblSwTransmissionInputShftPTO1 3452;
BA_ "SPN" SG_ 2566759678 EnableSwitchPTOEngineFlywheel 3939;
BA_ "SPN" SG_ 2566759678 EnableSwitchPTOEngineAccssryDrv1 3942;
BA_ "SPN" SG_ 2566759678 EnableSwitchPTOEngineAccssryDrv2 3945;
BA_ "SPN" SG_ 2566759678 EngmntConsntTrnsfrCsOutptShftPTO 3459;
BA_ "SPN" SG_ 2566759678 EngmntConsntTrnsmOutptShftPTO 3458;
BA_ "SPN" SG_ 2566759678 EngmntConsntTrnsmInputShftPTO2 3457;
BA_ "SPN" SG_ 2566759678 EngmntConsntTrnsmInputShftPTO1 3456;
BA_ "SPN" SG_ 2566759678 EngmntConsntPTOEngineFlywheel 3940;
BA_ "SPN" SG_ 2566759678 EngmntConsntPTOEngineAccssryDrv1 3943;
BA_ "SPN" SG_ 2566759678 EngmntConsntPTOEngineAccssryDrv2 3946;
BA_ "SPN" SG_ 2566759678 EngmntStatTransferCsOutptShftPTO 3463;
BA_ "SPN" SG_ 2566759678 EngmntStatTrnsmOutptShftPTO 3462;
BA_ "SPN" SG_ 2566759678 EngmntStatTrnsmInputShftPTO2 3461;
BA_ "SPN" SG_ 2566759678 EngmntStatTrnsmInputShftPTO1 3460;
BA_ "SPN" SG_ 2566759678 EngmntStatusPTOEngineFlywheel 3941;
BA_ "SPN" SG_ 2566759678 EngmntStatusPTOEngineAccssryDrv1 3944;
BA_ "SPN" SG_ 2566759678 EngmntStatusPTOEngineAccssryDrv2 3947;
BA_ "SPN" SG_ 2566759678 AtLeastOnePTOEngaged 3948;
BA_ "SigType" SG_ 2566742782 GloblTechnicalRegulationDescript 3;
BA_ "SigType" SG_ 2633861886 J2012DTC 3;
VAL_ 2365402110 Jystck6GrpXAxsNtrlPositionStatus 0 "Not in Neutral Position" 1 "In Neutral Position" 2 "Error Indicator" 3 "Not Available" ;
VAL_ 2365402110 Jystck6GrpXAxsLvrLftNegPosStatus 0 "Not on negative side of Neutral" 1 "On negative side of Neutral" 2 "Error Indicator" 3 "Not Available" ;
VAL_ 2365402110 Jystck6GrpXAxsLvrRghtPstvPosStat 0 "Not on Positive side of Neutral" 1 "On positive side of Neutral" 2 "Error Indicator" 3 "Not Available" ;
VAL_ 2365402110 Jystck6GrpYAxsNtrlPositionStatus 0 "Not in Neutral Position" 1 "In Neutral Position" 2 "Error Indicator" 3 "Not Available" ;
VAL_ 2365402110 Jystck6GrpYAxsLvrBackNegPosStat 0 "Not on negative side of Neutral" 1 "On negative side of Neutral" 2 "Error Indicator" 3 "Not Available" ;
VAL_ 2365402110 Jystck6GrpYAxsLvrFrwdPstvPosStat 0 "Not on Positive side of Neutral" 1 "On positive side of Neutral" 2 "Error Indicator" 3 "Not Available" ;
VAL_ 2365402110 Jystck6ThetaAxsNtrlPosStatus 0 "Not in Neutral Position" 1 "In Neutral Position" 2 "Error Indicator" 3 "Not Available" ;
VAL_ 2365402110 Jystck6ThtAxsCntrClckwsNegPsStat 0 "Not on negative side of Neutral" 1 "On negative side of Neutral" 2 "Error Indicator" 3 "Not Available" ;
VAL_ 2365402110 Jystck6ThetaAxsClckwsPstvPosStat 0 "Not on Positive side of Neutral" 1 "On positive side of Neutral" 2 "Error Indicator" 3 "Not Available" ;
VAL_ 2365402110 Jystck6ThetaAxsDetentPosStatus 0 "Not in the Detent Position" 1 "In the Detent Position" 2 "Error Indicator" 3 "Not Available" ;
VAL_ 2365402110 Jystck6GrpYAxsDetentPosStatus 0 "Not in the Detent Position" 1 "In the Detent Position" 2 "Error Indicator" 3 "Not Available" ;
VAL_ 2365402110 Jystck6GrpXAxsDetentPosStatus 0 "Not in the Detent Position" 1 "In the Detent Position" 2 "Error Indicator" 3 "Not Available" ;
VAL_ 2365402110 Joystick6Button16PressedStatus 0 "Button not pressed" 1 "Button pressed" 2 "Error Indicator" 3 "Not Available" ;
VAL_ 2365402110 Joystick6Button15PressedStatus 0 "Button not pressed" 1 "Button pressed" 2 "Error Indicator" 3 "Not Available" ;
VAL_ 2365402110 Joystick6Button14PressedStatus 0 "Button not pressed" 1 "Button pressed" 2 "Error Indicator" 3 "Not Available" ;
VAL_ 2365402110 Joystick6Button13PressedStatus 0 "Button not pressed" 1 "Button pressed" 2 "Error Indicator" 3 "Not Available" ;
VAL_ 2365402366 Jystck6XAxsNeutralPositionStatus 0 "Not in Neutral Position" 1 "In Neutral Position" 2 "Error Indicator" 3 "Not Available" ;
VAL_ 2365402366 Jystck6XAxsLvrLftNegPosStatus 0 "Not on negative side of Neutral" 1 "On negative side of Neutral" 2 "Error Indicator" 3 "Not Available" ;
VAL_ 2365402366 Jystck6XAxsLvrRightPstvPosStatus 0 "Not on Positive side of Neutral" 1 "On positive side of Neutral" 2 "Error Indicator" 3 "Not Available" ;
VAL_ 2365402366 Jystck6YAxsNeutralPositionStatus 0 "Not in Neutral Position" 1 "In Neutral Position" 2 "Error Indicator" 3 "Not Available" ;
VAL_ 2365402366 Jystck6YAxsLvrBackNegPosStatus 0 "Not on negative side of Neutral" 1 "On negative side of Neutral" 2 "Error Indicator" 3 "Not Available" ;
VAL_ 2365402366 Jystck6YAxsLvrFrwdPstvPosStatus 0 "Not on Positive side of Neutral" 1 "On positive side of Neutral" 2 "Error Indicator" 3 "Not Available" ;
VAL_ 2365402366 Jystck6YAxsDetentPositionStatus 0 "Not in the Detent Position" 1 "In the Detent Position" 2 "Error Indicator" 3 "Not Available" ;
VAL_ 2365402366 Jystck6XAxsDetentPositionStatus 0 "Not in the Detent Position" 1 "In the Detent Position" 2 "Error Indicator" 3 "Not Available" ;
VAL_ 2365402366 Joystick6Button4PressedStatus 0 "Button not pressed" 1 "Button pressed" 2 "Error Indicator" 3 "Not Available" ;
VAL_ 2365402366 Joystick6Button3PressedStatus 0 "Button not pressed" 1 "Button pressed" 2 "Error Indicator" 3 "Not Available" ;
VAL_ 2365402366 Joystick6Button2PressedStatus 0 "Button not pressed" 1 "Button pressed" 2 "Error Indicator" 3 "Not Available" ;
VAL_ 2365402366 Joystick6Button1PressedStatus 0 "Button not pressed" 1 "Button pressed" 2 "Error Indicator" 3 "Not Available" ;
VAL_ 2365402366 Joystick6Button8PressedStatus 0 "Button not pressed" 1 "Button pressed" 2 "Error Indicator" 3 "Not Available" ;
VAL_ 2365402366 Joystick6Button7PressedStatus 0 "Button not pressed" 1 "Button pressed" 2 "Error Indicator" 3 "Not Available" ;
VAL_ 2365402366 Joystick6Button6PressedStatus 0 "Button not pressed" 1 "Button pressed" 2 "Error Indicator" 3 "Not Available" ;
VAL_ 2365402366 Joystick6Button5PressedStatus 0 "Button not pressed" 1 "Button pressed" 2 "Error Indicator" 3 "Not Available" ;
VAL_ 2365402366 Joystick6Button12PressedStatus 0 "Button not pressed" 1 "Button pressed" 2 "Error Indicator" 3 "Not Available" ;
VAL_ 2365402366 Joystick6Button11PressedStatus 0 "Button not pressed" 1 "Button pressed" 2 "Error Indicator" 3 "Not Available" ;
VAL_ 2365402366 Joystick6Button10PressedStatus 0 "Button not pressed" 1 "Button pressed" 2 "Error Indicator" 3 "Not Available" ;
VAL_ 2365402366 Joystick6Button9PressedStatus 0 "Button not pressed" 1 "Button pressed" 2 "Error Indicator" 3 "Not Available" ;
VAL_ 2365402622 Jystck5GrpXAxsNtrlPositionStatus 0 "Not in Neutral Position" 1 "In Neutral Position" 2 "Error Indicator" 3 "Not Available" ;
VAL_ 2365402622 Jystck5GrpXAxsLvrLftNegPosStatus 0 "Not on negative side of Neutral" 1 "On negative side of Neutral" 2 "Error Indicator" 3 "Not Available" ;
VAL_ 2365402622 Jystck5GrpXAxsLvrRghtPstvPosStat 0 "Not on Positive side of Neutral" 1 "On positive side of Neutral" 2 "Error Indicator" 3 "Not Available" ;
VAL_ 2365402622 Jystck5GrpYAxsNtrlPositionStatus 0 "Not in Neutral Position" 1 "In Neutral Position" 2 "Error Indicator" 3 "Not Available" ;
VAL_ 2365402622 Jystck5GrpYAxsLvrBackNegPosStat 0 "Not on negative side of Neutral" 1 "On negative side of Neutral" 2 "Error Indicator" 3 "Not Available" ;
VAL_ 2365402622 Jystck5GrpYAxsLvrFrwdPstvPosStat 0 "Not on Positive side of Neutral" 1 "On positive side of Neutral" 2 "Error Indicator" 3 "Not Available" ;
VAL_ 2365402622 Jystck5ThetaAxsNtrlPosStatus 0 "Not in Neutral Position" 1 "In Neutral Position" 2 "Error Indicator" 3 "Not Available" ;
VAL_ 2365402622 Jystck5ThtAxsCntrClckwsNegPsStat 0 "Not on negative side of Neutral" 1 "On negative side of Neutral" 2 "Error Indicator" 3 "Not Available" ;
VAL_ 2365402622 Jystck5ThetaAxsClckwsPstvPosStat 0 "Not on Positive side of Neutral" 1 "On positive side of Neutral" 2 "Error Indicator" 3 "Not Available" ;
VAL_ 2365402622 Jystck5ThetaAxsDetentPosStatus 0 "Not in the Detent Position" 1 "In the Detent Position" 2 "Error Indicator" 3 "Not Available" ;
VAL_ 2365402622 Jystck5GrpYAxsDetentPosStatus 0 "Not in the Detent Position" 1 "In the Detent Position" 2 "Error Indicator" 3 "Not Available" ;
VAL_ 2365402622 Jystck5GrpXAxsDetentPosStatus 0 "Not in the Detent Position" 1 "In the Detent Position" 2 "Error Indicator" 3 "Not Available" ;
VAL_ 2365402622 Joystick5Button16PressedStatus 0 "Button not pressed" 1 "Button pressed" 2 "Error Indicator" 3 "Not Available" ;
VAL_ 2365402622 Joystick5Button15PressedStatus 0 "Button not pressed" 1 "Button pressed" 2 "Error Indicator" 3 "Not Available" ;
VAL_ 2365402622 Joystick5Button14PressedStatus 0 "Button not pressed" 1 "Button pressed" 2 "Error Indicator" 3 "Not Available" ;
VAL_ 2365402622 Joystick5Button13PressedStatus 0 "Button not pressed" 1 "Button pressed" 2 "Error Indicator" 3 "Not Available" ;
VAL_ 2365402878 Jystck5XAxsNeutralPositionStatus 0 "Not in Neutral Position" 1 "In Neutral Position" 2 "Error Indicator" 3 "Not Available" ;
VAL_ 2365402878 Jystck5XAxsLvrLftNegPosStatus 0 "Not on negative side of Neutral" 1 "On negative side of Neutral" 2 "Error Indicator" 3 "Not Available" ;
VAL_ 2365402878 Jystck5XAxsLvrRightPstvPosStatus 0 "Not on Positive side of Neutral" 1 "On positive side of Neutral" 2 "Error Indicator" 3 "Not Available" ;
VAL_ 2365402878 Jystck5YAxsNeutralPositionStatus 0 "Not in Neutral Position" 1 "In Neutral Position" 2 "Error Indicator" 3 "Not Available" ;
VAL_ 2365402878 Jystck5YAxsLvrBackNegPosStatus 0 "Not on negative side of Neutral" 1 "On negative side of Neutral" 2 "Error Indicator" 3 "Not Available" ;
VAL_ 2365402878 Jystck5YAxsLvrFrwdPstvPosStatus 0 "Not on Positive side of Neutral" 1 "On positive side of Neutral" 2 "Error Indicator" 3 "Not Available" ;
VAL_ 2365402878 Jystck5YAxsDetentPositionStatus 0 "Not in the Detent Position" 1 "In the Detent Position" 2 "Error Indicator" 3 "Not Available" ;
VAL_ 2365402878 Jystck5XAxsDetentPositionStatus 0 "Not in the Detent Position" 1 "In the Detent Position" 2 "Error Indicator" 3 "Not Available" ;
VAL_ 2365402878 Joystick5Button4PressedStatus 0 "Button not pressed" 1 "Button pressed" 2 "Error Indicator" 3 "Not Available" ;
VAL_ 2365402878 Joystick5Button3PressedStatus 0 "Button not pressed" 1 "Button pressed" 2 "Error Indicator" 3 "Not Available" ;
VAL_ 2365402878 Joystick5Button2PressedStatus 0 "Button not pressed" 1 "Button pressed" 2 "Error Indicator" 3 "Not Available" ;
VAL_ 2365402878 Joystick5Button1PressedStatus 0 "Button not pressed" 1 "Button pressed" 2 "Error Indicator" 3 "Not Available" ;
VAL_ 2365402878 Joystick5Button8PressedStatus 0 "Button not pressed" 1 "Button pressed" 2 "Error Indicator" 3 "Not Available" ;
VAL_ 2365402878 Joystick5Button7PressedStatus 0 "Button not pressed" 1 "Button pressed" 2 "Error Indicator" 3 "Not Available" ;
VAL_ 2365402878 Joystick5Button6PressedStatus 0 "Button not pressed" 1 "Button pressed" 2 "Error Indicator" 3 "Not Available" ;
VAL_ 2365402878 Joystick5Button5PressedStatus 0 "Button not pressed" 1 "Button pressed" 2 "Error Indicator" 3 "Not Available" ;
VAL_ 2365402878 Joystick5Button12PressedStatus 0 "Button not pressed" 1 "Button pressed" 2 "Error Indicator" 3 "Not Available" ;
VAL_ 2365402878 Joystick5Button11PressedStatus 0 "Button not pressed" 1 "Button pressed" 2 "Error Indicator" 3 "Not Available" ;
VAL_ 2365402878 Joystick5Button10PressedStatus 0 "Button not pressed" 1 "Button pressed" 2 "Error Indicator" 3 "Not Available" ;
VAL_ 2365402878 Joystick5Button9PressedStatus 0 "Button not pressed" 1 "Button pressed" 2 "Error Indicator" 3 "Not Available" ;
VAL_ 2365403134 Jystck4GrpXAxsNtrlPositionStatus 0 "Not in Neutral Position" 1 "In Neutral Position" 2 "Error Indicator" 3 "Not Available" ;
VAL_ 2365403134 Jystck4GrpXAxsLvrLftNegPosStatus 0 "Not on negative side of Neutral" 1 "On negative side of Neutral" 2 "Error Indicator" 3 "Not Available" ;
VAL_ 2365403134 Jystck4GrpXAxsLvrRghtPstvPosStat 0 "Not on Positive side of Neutral" 1 "On positive side of Neutral" 2 "Error Indicator" 3 "Not Available" ;
VAL_ 2365403134 Jystck4GrpYAxsNtrlPositionStatus 0 "Not in Neutral Position" 1 "In Neutral Position" 2 "Error Indicator" 3 "Not Available" ;
VAL_ 2365403134 Jystck4GrpYAxsLvrBackNegPosStat 0 "Not on negative side of Neutral" 1 "On negative side of Neutral" 2 "Error Indicator" 3 "Not Available" ;
VAL_ 2365403134 Jystck4GrpYAxsLvrFrwdPstvPosStat 0 "Not on Positive side of Neutral" 1 "On positive side of Neutral" 2 "Error Indicator" 3 "Not Available" ;
VAL_ 2365403134 Jystck4ThetaAxsNtrlPosStatus 0 "Not in Neutral Position" 1 "In Neutral Position" 2 "Error Indicator" 3 "Not Available" ;
VAL_ 2365403134 Jystck4ThtAxsCntrClckwsNegPsStat 0 "Not on negative side of Neutral" 1 "On negative side of Neutral" 2 "Error Indicator" 3 "Not Available" ;
VAL_ 2365403134 Jystck4ThetaAxsClckwsPstvPosStat 0 "Not on Positive side of Neutral" 1 "On positive side of Neutral" 2 "Error Indicator" 3 "Not Available" ;
VAL_ 2365403134 Jystck4ThetaAxsDetentPosStatus 0 "Not in the Detent Position" 1 "In the Detent Position" 2 "Error Indicator" 3 "Not Available" ;
VAL_ 2365403134 Jystck4GrpYAxsDetentPosStatus 0 "Not in the Detent Position" 1 "In the Detent Position" 2 "Error Indicator" 3 "Not Available" ;
VAL_ 2365403134 Jystck4GrpXAxsDetentPosStatus 0 "Not in the Detent Position" 1 "In the Detent Position" 2 "Error Indicator" 3 "Not Available" ;
VAL_ 2365403134 Joystick4Button16PressedStatus 0 "Button not pressed" 1 "Button pressed" 2 "Error Indicator" 3 "Not Available" ;
VAL_ 2365403134 Joystick4Button15PressedStatus 0 "Button not pressed" 1 "Button pressed" 2 "Error Indicator" 3 "Not Available" ;
VAL_ 2365403134 Joystick4Button14PressedStatus 0 "Button not pressed" 1 "Button pressed" 2 "Error Indicator" 3 "Not Available" ;
VAL_ 2365403134 Joystick4Button13PressedStatus 0 "Button not pressed" 1 "Button pressed" 2 "Error Indicator" 3 "Not Available" ;
VAL_ 2365403390 Jystck4XAxsNeutralPositionStatus 0 "Not in Neutral Position" 1 "In Neutral Position" 2 "Error Indicator" 3 "Not Available" ;
VAL_ 2365403390 Jystck4XAxsLvrLftNegPosStatus 0 "Not on negative side of Neutral" 1 "On negative side of Neutral" 2 "Error Indicator" 3 "Not Available" ;
VAL_ 2365403390 Jystck4XAxsLvrRightPstvPosStatus 0 "Not on Positive side of Neutral" 1 "On positive side of Neutral" 2 "Error Indicator" 3 "Not Available" ;
VAL_ 2365403390 Jystck4YAxsNeutralPositionStatus 0 "Not in Neutral Position" 1 "In Neutral Position" 2 "Error Indicator" 3 "Not Available" ;
VAL_ 2365403390 Jystck4YAxsLvrBackNegPosStatus 0 "Not on negative side of Neutral" 1 "On negative side of Neutral" 2 "Error Indicator" 3 "Not Available" ;
VAL_ 2365403390 Jystck4YAxsLvrFrwdPstvPosStatus 0 "Not on Positive side of Neutral" 1 "On positive side of Neutral" 2 "Error Indicator" 3 "Not Available" ;
VAL_ 2365403390 Jystck4YAxsDetentPositionStatus 0 "Not in the Detent Position" 1 "In the Detent Position" 2 "Error Indicator" 3 "Not Available" ;
VAL_ 2365403390 Jystck4XAxsDetentPositionStatus 0 "Not in the Detent Position" 1 "In the Detent Position" 2 "Error Indicator" 3 "Not Available" ;
VAL_ 2365403390 Joystick4Button4PressedStatus 0 "Button not pressed" 1 "Button pressed" 2 "Error Indicator" 3 "Not Available" ;
VAL_ 2365403390 Joystick4Button3PressedStatus 0 "Button not pressed" 1 "Button pressed" 2 "Error Indicator" 3 "Not Available" ;
VAL_ 2365403390 Joystick4Button2PressedStatus 0 "Button not pressed" 1 "Button pressed" 2 "Error Indicator" 3 "Not Available" ;
VAL_ 2365403390 Joystick4Button1PressedStatus 0 "Button not pressed" 1 "Button pressed" 2 "Error Indicator" 3 "Not Available" ;
VAL_ 2365403390 Joystick4Button8PressedStatus 0 "Button not pressed" 1 "Button pressed" 2 "Error Indicator" 3 "Not Available" ;
VAL_ 2365403390 Joystick4Button7PressedStatus 0 "Button not pressed" 1 "Button pressed" 2 "Error Indicator" 3 "Not Available" ;
VAL_ 2365403390 Joystick4Button6PressedStatus 0 "Button not pressed" 1 "Button pressed" 2 "Error Indicator" 3 "Not Available" ;
VAL_ 2365403390 Joystick4Button5PressedStatus 0 "Button not pressed" 1 "Button pressed" 2 "Error Indicator" 3 "Not Available" ;
VAL_ 2365403390 Joystick4Button12PressedStatus 0 "Button not pressed" 1 "Button pressed" 2 "Error Indicator" 3 "Not Available" ;
VAL_ 2365403390 Joystick4Button11PressedStatus 0 "Button not pressed" 1 "Button pressed" 2 "Error Indicator" 3 "Not Available" ;
VAL_ 2365403390 Joystick4Button10PressedStatus 0 "Button not pressed" 1 "Button pressed" 2 "Error Indicator" 3 "Not Available" ;
VAL_ 2365403390 Joystick4Button9PressedStatus 0 "Button not pressed" 1 "Button pressed" 2 "Error Indicator" 3 "Not Available" ;
VAL_ 2566730238 Fan2DriveState 0 "Fan off" 1 "Engine system-General" 2 "Excessive engine air temperature" 3 "Excessive engine oil temperature" 4 "Excessive engine coolant temperature" 5 "Excessive transmission oil temperature" 6 "Excessive hydraulic oil temperature" 7 "Default Operation" 8 "Reverse Operation" 9 "Manual control" 10 "Transmission retarder" 11 "A/C system" 12 "Timer" 13 "Engine brake" 14 "Other" 15 "Not available" ;
VAL_ 2566730750 Aftrtrtmnt2DslExhstFldPumpState 0 "pump operational" 1 "pump error" 2 "reserved for SAE assignment" 3 "not available" ;
VAL_ 2566730750 Aftrtrtmnt2DslExhstFldPmpPwrRely 0 "not active" 1 "active" 2 "error" 3 "not available" ;
VAL_ 2566730750 Aftrtrtmnt2DslExhaustFluidPump 0 "Off" 1 "On" 2 "Error" 3 "Not available" ;
VAL_ 2566731518 Aftrtrtmnt2DslExhaustFluidType 0 "Urea concentration too high" 1 "Urea concentration too low" 2 "Fluid is diesel" 3 "Diesel exhaust fluid is proper mixture" 12 "Diesel exhaust fluid, but concentration cannot be determined" 13 "Not able to determine fluid property" 14 "Error with diesel exhaust fluid property detection" 15 "Not available" ;
VAL_ 2566732542 Aft2DslExhstFldDsrFltSupPrsionRq 0 "Error suppression off" 1 "Error suppression on" 2 "Reserved" 3 "Not available" ;
VAL_ 2566732542 Aft2DslExhstFldDoserHeatingMdeRq 0 "Heater off" 1 "Heater economy mode" 2 "Heater automatic mode" 3 "Heater on" 7 "Not available" ;
VAL_ 2566732542 Aftrtrtmnt2DslExhstFldLineHtr1 0 "request for heater to be inactive " 1 "request for heater to be active " 2 "reserved for future assignment by SAE " 3 "not available" ;
VAL_ 2566732542 Aftrtrtmnt2DslExhstFldLineHtr2 0 "request for heater to be inactive " 1 "request for heater to be active " 2 "reserved for future assignment by SAE " 3 "not available" ;
VAL_ 2566732542 Aftrtrtmnt2DslExhstFldLineHtr3 0 "request for heater to be inactive " 1 "request for heater to be active " 2 "reserved for future assignment by SAE " 3 "not available" ;
VAL_ 2566732542 Aftrtrtmnt2DslExhstFldLineHtr4 0 "request for heater to be inactive " 1 "request for heater to be active " 2 "reserved for future assignment by SAE " 3 "not available" ;
VAL_ 2566732542 Aft2DslExhstFldLineHtrRely1 0 "Off" 1 "On" 2 "Error" 3 "Not available" ;
VAL_ 2566732542 Aft2DslExhstFldLineHtrRely2 0 "Off" 1 "On" 2 "Error" 3 "Not available" ;
VAL_ 2566732542 Aft2DslExhstFldLineHtrRely3 0 "Off" 1 "On" 2 "Error" 3 "Not available" ;
VAL_ 2566732542 Aftrtrtmnt2DslExhstFldLineHtr5 0 "request for heater to be inactive " 1 "request for heater to be active " 2 "reserved for future assignment by SAE " 3 "not available" ;
VAL_ 2566732542 Aftrtrtmnt2DslExhstFldLineHtr6 0 "request for heater to be inactive" 1 "request for heater to be active" 2 "reserved for future assignment by SAE" 3 "not available" ;
VAL_ 2566732542 Aftrtrtmnt2DslExhstFldLineHtr7 0 "request for heater to be inactive" 1 "request for heater to be active" 2 "reserved for future assignment by SAE" 3 "not available" ;
VAL_ 2566732542 Aftrtrtmnt2DslExhstFldLineHtr8 0 "request for heater to be inactive" 1 "request for heater to be active" 2 "reserved for future assignment by SAE" 3 "not available" ;
VAL_ 2566732542 Aftrtrtmnt2DslExhstFldLineHtr9 0 "request for heater to be inactive" 1 "request for heater to be active" 2 "reserved for future assignment by SAE" 3 "not available" ;
VAL_ 2566732542 Aftrtrtmnt2DslExhstFldLineHtr10 0 "request for heater to be inactive" 1 "request for heater to be active" 2 "reserved for future assignment by SAE" 3 "not available" ;
VAL_ 2566732798 Aft2SCRDsngVlvExhstTempRedRq 0 "no request " 1 "reduction request stage 1" 2 "reduction request stage 2" 3 "reserved for future assignment by SAE" 4 "reserved for future assignment by SAE" 5 "reserved for future assignment by SAE" 6 "error" 7 "not available" ;
VAL_ 2566732798 Aftrtrtmnt2SCRFeedbackCtrlStatus 0 "open loop control active " 1 "closed loop control active " 6 "error " 7 "not available" ;
VAL_ 2566732798 Aft2DslExhstFldLineHtr1Stat 0 "heater inactive " 1 "heater active " 2 "error " 3 "not available" ;
VAL_ 2566732798 Aft2DslExhstFldLineHtr2Stat 0 "heater inactive " 1 "heater active " 2 "error " 3 "not available" ;
VAL_ 2566732798 Aft2DslExhstFldLineHtr3Stat 0 "heater inactive " 1 "heater active " 2 "error " 3 "not available" ;
VAL_ 2566732798 Aft2DslExhstFldLineHtr4Stat 0 "heater inactive " 1 "heater active " 2 "error " 3 "not available" ;
VAL_ 2566733054 Aftrtrtmnt1DslExhstFldPumpState 0 "pump operational" 1 "pump error" 2 "reserved for SAE assignment" 3 "not available" ;
VAL_ 2566733054 Aftrtrtmnt1DslExhstFldPmpPwrRely 0 "not active" 1 "active" 2 "error" 3 "not available" ;
VAL_ 2566733054 Aftrtrtmnt1DslExhaustFluidPump 0 "Off" 1 "On" 2 "Error" 3 "Not available" ;
VAL_ 2566734078 Aft1DslExhstFldDsrFltSupPrsionRq 0 "Error suppression off" 1 "Error suppression on" 2 "Reserved" 3 "Not available" ;
VAL_ 2566734078 Aft1DslExhstFldDoserHeatingMdeRq 0 "Heater off" 1 "Heater economy mode" 2 "Heater automatic mode" 3 "Heater on" 7 "Not available" ;
VAL_ 2566734078 Aftrtrtmnt1DslExhstFldLineHtr1 0 "request for heater to be inactive " 1 "request for heater to be active " 2 "reserved for future assignment by SAE " 3 "not available" ;
VAL_ 2566734078 Aftrtrtmnt1DslExhstFldLineHtr2 0 "request for heater to be inactive " 1 "request for heater to be active " 2 "reserved for future assignment by SAE " 3 "not available" ;
VAL_ 2566734078 Aftrtrtmnt1DslExhstFldLineHtr3 0 "request for heater to be inactive " 1 "request for heater to be active " 2 "reserved for future assignment by SAE " 3 "not available" ;
VAL_ 2566734078 Aftrtrtmnt1DslExhstFldLineHtr4 0 "request for heater to be inactive " 1 "request for heater to be active " 2 "reserved for future assignment by SAE " 3 "not available" ;
VAL_ 2566734078 Aft1DslExhstFldLineHtrRely1 0 "Off" 1 "On" 2 "Error" 3 "Not available" ;
VAL_ 2566734078 Aft1DslExhstFldLineHtrRely2 0 "Off" 1 "On" 2 "Error" 3 "Not available" ;
VAL_ 2566734078 Aft1DslExhstFldLineHtrRely3 0 "Off" 1 "On" 2 "Error" 3 "Not available" ;
VAL_ 2566734078 Aftrtrtmnt1DslExhstFldLineHtr5 0 "request for heater to be inactive" 1 "request for heater to be active" 2 "reserved for future assignment by SAE" 3 "not available" ;
VAL_ 2566734078 Aftrtrtmnt1DslExhstFldLineHtr6 0 "request for heater to be inactive" 1 "request for heater to be active" 2 "reserved for future assignment by SAE" 3 "not available" ;
VAL_ 2566734078 Aftrtrtmnt1DslExhstFldLineHtr7 0 "request for heater to be inactive" 1 "request for heater to be active" 2 "reserved for future assignment by SAE" 3 "not available" ;
VAL_ 2566734078 Aftrtrtmnt1DslExhstFldLineHtr8 0 "request for heater to be inactive" 1 "request for heater to be active" 2 "reserved for future assignment by SAE" 3 "not available" ;
VAL_ 2566734078 Aftrtrtmnt1DslExhstFldLineHtr9 0 "request for heater to be inactive" 1 "request for heater to be active" 2 "reserved for future assignment by SAE" 3 "not available" ;
VAL_ 2566734078 Aftrtrtmnt1DslExhstFldLineHtr10 0 "request for heater to be inactive" 1 "request for heater to be active" 2 "reserved for future assignment by SAE" 3 "not available" ;
VAL_ 2566734334 Aft1SCRDsngVlvExhstTempRedRq 0 "no request " 1 "reduction request stage 1" 2 "reduction request stage 2" 3 "reserved for future assignment by SAE" 4 "reserved for future assignment by SAE" 5 "reserved for future assignment by SAE" 6 "error" 7 "not available" ;
VAL_ 2566734334 Aftrtrtmnt1SCRFeedbackCtrlStatus 0 "open loop control active " 1 "closed loop control active " 6 "error " 7 "not available" ;
VAL_ 2566734334 Aft1DslExhstFldLineHtr1Stat 0 "heater inactive " 1 "heater active " 2 "error " 3 "not available" ;
VAL_ 2566734334 Aft1DslExhstFldLineHtr2Stat 0 "heater inactive " 1 "heater active " 2 "error " 3 "not available" ;
VAL_ 2566734334 Aft1DslExhstFldLineHtr3Stat 0 "heater inactive " 1 "heater active " 2 "error " 3 "not available" ;
VAL_ 2566734334 Aft1DslExhstFldLineHtr4Stat 0 "heater inactive " 1 "heater active " 2 "error " 3 "not available" ;
VAL_ 2566735102 Aftrtrtmnt2FuelPumpRelayControl 0 "off" 1 "on" 2 "reserved for SAE assignment" 3 "not available" ;
VAL_ 2566735102 Aft2FuelFlwDiverterVlvCtrl 0 "off" 1 "on" 2 "reserved for SAE assignment" 3 "not available" ;
VAL_ 2566736382 EngExhstBnk1O2SensorClsdLpOp 0 "Open loop" 1 "Closed loop" 2 "Open loop due to driving conditions" 3 "Open loop" 4 "Closed loop, but fault with at least one oxygen sensor" 15 "not supported" ;
VAL_ 2432520702 AftercoolerCoolantThermostatMode 0 "temperature control mode" 1 "position control mode" 2 "reserved" 3 "don't care/reserved" ;
VAL_ 2432520702 EngineChrgAirCoolBypssValve1Cmd 0 "No air is bypassed" 100 "Full bypass capacity" ;
VAL_ 2432520702 EngineChrgAirCoolBypssValve2Cmd 0 "No air is bypassed" 100 "Full bypass capacity" ;
VAL_ 2432520958 EngineCoolantThermostatMode 0 "temperature control mode" 1 "position control mode" 2 "reserved" 3 "don't care/reserved" ;
VAL_ 2566739198 ProtectLamp 0 "Lamp Off" 1 "Lamp On" 2 "Reserved" 3 "Not available" ;
VAL_ 2566739198 AmberWarningLamp 0 "Lamp Off" 1 "Lamp On" 2 "Reserved" 3 "Not available" ;
VAL_ 2566739198 RedStopLamp 0 "Lamp Off" 1 "Lamp On" 2 "Reserved" 3 "Not available" ;
VAL_ 2566739198 MalfunctionIndicatorLamp 0 "Lamp Off" 1 "Lamp On" 2 "Short MIL for WWH OBD" 3 "Not available" ;
VAL_ 2566739198 FlashProtectLamp 0 "Slow Flash (1 Hz, 50 % duty cycle)" 1 "Fast Flash (2 Hz or faster, 50% duty cycle)" 2 "Reserved" 3 "Unavailable / Do Not Flash" ;
VAL_ 2566739198 FlashAmberWarningLamp 0 "Slow Flash (1 Hz, 50 % duty cycle)" 1 "Fast Flash (2 Hz or faster, 50% duty cycle)" 2 "Reserved" 3 "Unavailable / Do Not Flash" ;
VAL_ 2566739198 FlashRedStopLamp 0 "Slow Flash (1 Hz, 50 % duty cycle)" 1 "Fast Flash (2 Hz or faster, 50% duty cycle)" 2 "Reserved" 3 "Unavailable / Do Not Flash" ;
VAL_ 2566739198 FlashMalfunctionIndicatorLamp 0 "Slow Flash (1 Hz, 50 % duty cycle)" 1 "Fast Flash (2 Hz or faster, 50% duty cycle)" 2 "Class C DTC  " 3 "Unavailable / Do Not Flash" ;
VAL_ 2566739198 SPNConversionMethod 0 "Convert SPN per Version 4" 1 "Convert SPN per Version 1, 2 or 3" ;
VAL_ 2566739454 ProtectLamp 0 "Lamp Off" 1 "Lamp On" 2 "Reserved" 3 "Not available" ;
VAL_ 2566739454 AmberWarningLamp 0 "Lamp Off" 1 "Lamp On" 2 "Reserved" 3 "Not available" ;
VAL_ 2566739454 RedStopLamp 0 "Lamp Off" 1 "Lamp On" 2 "Reserved" 3 "Not available" ;
VAL_ 2566739454 MalfunctionIndicatorLamp 0 "Lamp Off" 1 "Lamp On" 2 "Short MIL for WWH OBD" 3 "Not available" ;
VAL_ 2566739454 FlashProtectLamp 0 "Slow Flash (1 Hz, 50 % duty cycle)" 1 "Fast Flash (2 Hz or faster, 50% duty cycle)" 2 "Reserved" 3 "Unavailable / Do Not Flash" ;
VAL_ 2566739454 FlashAmberWarningLamp 0 "Slow Flash (1 Hz, 50 % duty cycle)" 1 "Fast Flash (2 Hz or faster, 50% duty cycle)" 2 "Reserved" 3 "Unavailable / Do Not Flash" ;
VAL_ 2566739454 FlashRedStopLamp 0 "Slow Flash (1 Hz, 50 % duty cycle)" 1 "Fast Flash (2 Hz or faster, 50% duty cycle)" 2 "Reserved" 3 "Unavailable / Do Not Flash" ;
VAL_ 2566739454 FlashMalfunctionIndicatorLamp 0 "Slow Flash (1 Hz, 50 % duty cycle)" 1 "Fast Flash (2 Hz or faster, 50% duty cycle)" 2 "Class C DTC  " 3 "Unavailable / Do Not Flash" ;
VAL_ 2566739454 SPNConversionMethod 0 "Convert SPN per Version 4" 1 "Convert SPN per Version 1, 2 or 3" ;
VAL_ 2566739710 ProtectLamp 0 "Lamp Off" 1 "Lamp On" 2 "Reserved" 3 "Not available" ;
VAL_ 2566739710 AmberWarningLamp 0 "Lamp Off" 1 "Lamp On" 2 "Reserved" 3 "Not available" ;
VAL_ 2566739710 RedStopLamp 0 "Lamp Off" 1 "Lamp On" 2 "Reserved" 3 "Not available" ;
VAL_ 2566739710 MalfunctionIndicatorLamp 0 "Lamp Off" 1 "Lamp On" 2 "Short MIL for WWH OBD" 3 "Not available" ;
VAL_ 2566739710 FlashProtectLamp 0 "Slow Flash (1 Hz, 50 % duty cycle)" 1 "Fast Flash (2 Hz or faster, 50% duty cycle)" 2 "Reserved" 3 "Unavailable / Do Not Flash" ;
VAL_ 2566739710 FlashAmberWarningLamp 0 "Slow Flash (1 Hz, 50 % duty cycle)" 1 "Fast Flash (2 Hz or faster, 50% duty cycle)" 2 "Reserved" 3 "Unavailable / Do Not Flash" ;
VAL_ 2566739710 FlashRedStopLamp 0 "Slow Flash (1 Hz, 50 % duty cycle)" 1 "Fast Flash (2 Hz or faster, 50% duty cycle)" 2 "Reserved" 3 "Unavailable / Do Not Flash" ;
VAL_ 2566739710 FlashMalfunctionIndicatorLamp 0 "Slow Flash (1 Hz, 50 % duty cycle)" 1 "Fast Flash (2 Hz or faster, 50% duty cycle)" 2 "Class C DTC  " 3 "Unavailable / Do Not Flash" ;
VAL_ 2566739710 SPNConversionMethod 0 "Convert SPN per Version 4" 1 "Convert SPN per Version 1, 2 or 3" ;
VAL_ 2566739966 ProtectLamp 0 "Lamp Off" 1 "Lamp On" 2 "Reserved" 3 "Not available" ;
VAL_ 2566739966 AmberWarningLamp 0 "Lamp Off" 1 "Lamp On" 2 "Reserved" 3 "Not available" ;
VAL_ 2566739966 RedStopLamp 0 "Lamp Off" 1 "Lamp On" 2 "Reserved" 3 "Not available" ;
VAL_ 2566739966 MalfunctionIndicatorLamp 0 "Lamp Off" 1 "Lamp On" 2 "Short MIL for WWH OBD" 3 "Not available" ;
VAL_ 2566739966 FlashProtectLamp 0 "Slow Flash (1 Hz, 50 % duty cycle)" 1 "Fast Flash (2 Hz or faster, 50% duty cycle)" 2 "Reserved" 3 "Unavailable / Do Not Flash" ;
VAL_ 2566739966 FlashAmberWarningLamp 0 "Slow Flash (1 Hz, 50 % duty cycle)" 1 "Fast Flash (2 Hz or faster, 50% duty cycle)" 2 "Reserved" 3 "Unavailable / Do Not Flash" ;
VAL_ 2566739966 FlashRedStopLamp 0 "Slow Flash (1 Hz, 50 % duty cycle)" 1 "Fast Flash (2 Hz or faster, 50% duty cycle)" 2 "Reserved" 3 "Unavailable / Do Not Flash" ;
VAL_ 2566739966 FlashMalfunctionIndicatorLamp 0 "Slow Flash (1 Hz, 50 % duty cycle)" 1 "Fast Flash (2 Hz or faster, 50% duty cycle)" 2 "Class C DTC  " 3 "Unavailable / Do Not Flash" ;
VAL_ 2566739966 SPNConversionMethod 0 "Convert SPN per Version 4" 1 "Convert SPN per Version 1, 2 or 3" ;
VAL_ 2566740222 ProtectLamp 0 "Lamp Off" 1 "Lamp On" 2 "Reserved" 3 "Not available" ;
VAL_ 2566740222 AmberWarningLamp 0 "Lamp Off" 1 "Lamp On" 2 "Reserved" 3 "Not available" ;
VAL_ 2566740222 RedStopLamp 0 "Lamp Off" 1 "Lamp On" 2 "Reserved" 3 "Not available" ;
VAL_ 2566740222 MalfunctionIndicatorLamp 0 "Lamp Off" 1 "Lamp On" 2 "Short MIL for WWH OBD" 3 "Not available" ;
VAL_ 2566740222 FlashProtectLamp 0 "Slow Flash (1 Hz, 50 % duty cycle)" 1 "Fast Flash (2 Hz or faster, 50% duty cycle)" 2 "Reserved" 3 "Unavailable / Do Not Flash" ;
VAL_ 2566740222 FlashAmberWarningLamp 0 "Slow Flash (1 Hz, 50 % duty cycle)" 1 "Fast Flash (2 Hz or faster, 50% duty cycle)" 2 "Reserved" 3 "Unavailable / Do Not Flash" ;
VAL_ 2566740222 FlashRedStopLamp 0 "Slow Flash (1 Hz, 50 % duty cycle)" 1 "Fast Flash (2 Hz or faster, 50% duty cycle)" 2 "Reserved" 3 "Unavailable / Do Not Flash" ;
VAL_ 2566740222 FlashMalfunctionIndicatorLamp 0 "Slow Flash (1 Hz, 50 % duty cycle)" 1 "Fast Flash (2 Hz or faster, 50% duty cycle)" 2 "Class C DTC  " 3 "Unavailable / Do Not Flash" ;
VAL_ 2566740222 SPNConversionMethod 0 "Convert SPN per Version 4" 1 "Convert SPN per Version 1, 2 or 3" ;
VAL_ 2566740478 ProtectLamp 0 "Lamp Off" 1 "Lamp On" 2 "Reserved" 3 "Not available" ;
VAL_ 2566740478 AmberWarningLamp 0 "Lamp Off" 1 "Lamp On" 2 "Reserved" 3 "Not available" ;
VAL_ 2566740478 RedStopLamp 0 "Lamp Off" 1 "Lamp On" 2 "Reserved" 3 "Not available" ;
VAL_ 2566740478 MalfunctionIndicatorLamp 0 "Lamp Off" 1 "Lamp On" 2 "Short MIL for WWH OBD" 3 "Not available" ;
VAL_ 2566740478 FlashProtectLamp 0 "Slow Flash (1 Hz, 50 % duty cycle)" 1 "Fast Flash (2 Hz or faster, 50% duty cycle)" 2 "Reserved" 3 "Unavailable / Do Not Flash" ;
VAL_ 2566740478 FlashAmberWarningLamp 0 "Slow Flash (1 Hz, 50 % duty cycle)" 1 "Fast Flash (2 Hz or faster, 50% duty cycle)" 2 "Reserved" 3 "Unavailable / Do Not Flash" ;
VAL_ 2566740478 FlashRedStopLamp 0 "Slow Flash (1 Hz, 50 % duty cycle)" 1 "Fast Flash (2 Hz or faster, 50% duty cycle)" 2 "Reserved" 3 "Unavailable / Do Not Flash" ;
VAL_ 2566740478 FlashMalfunctionIndicatorLamp 0 "Slow Flash (1 Hz, 50 % duty cycle)" 1 "Fast Flash (2 Hz or faster, 50% duty cycle)" 2 "Class C DTC  " 3 "Unavailable / Do Not Flash" ;
VAL_ 2566740478 SPNConversionMethod 0 "Convert SPN per Version 4" 1 "Convert SPN per Version 1, 2 or 3" ;
VAL_ 2566740734 ProtectLamp 0 "Lamp Off" 1 "Lamp On" 2 "Reserved" 3 "Not available" ;
VAL_ 2566740734 AmberWarningLamp 0 "Lamp Off" 1 "Lamp On" 2 "Reserved" 3 "Not available" ;
VAL_ 2566740734 RedStopLamp 0 "Lamp Off" 1 "Lamp On" 2 "Reserved" 3 "Not available" ;
VAL_ 2566740734 MalfunctionIndicatorLamp 0 "Lamp Off" 1 "Lamp On" 2 "Short MIL for WWH OBD" 3 "Not available" ;
VAL_ 2566740734 FlashProtectLamp 0 "Slow Flash (1 Hz, 50 % duty cycle)" 1 "Fast Flash (2 Hz or faster, 50% duty cycle)" 2 "Reserved" 3 "Unavailable / Do Not Flash" ;
VAL_ 2566740734 FlashAmberWarningLamp 0 "Slow Flash (1 Hz, 50 % duty cycle)" 1 "Fast Flash (2 Hz or faster, 50% duty cycle)" 2 "Reserved" 3 "Unavailable / Do Not Flash" ;
VAL_ 2566740734 FlashRedStopLamp 0 "Slow Flash (1 Hz, 50 % duty cycle)" 1 "Fast Flash (2 Hz or faster, 50% duty cycle)" 2 "Reserved" 3 "Unavailable / Do Not Flash" ;
VAL_ 2566740734 FlashMalfunctionIndicatorLamp 0 "Slow Flash (1 Hz, 50 % duty cycle)" 1 "Fast Flash (2 Hz or faster, 50% duty cycle)" 2 "Class C DTC  " 3 "Unavailable / Do Not Flash" ;
VAL_ 2566740734 SPNConversionMethod 0 "Convert SPN per Version 4" 1 "Convert SPN per Version 1, 2 or 3" ;
VAL_ 2566740990 ProtectLamp 0 "Lamp Off" 1 "Lamp On" 2 "Reserved" 3 "Not available" ;
VAL_ 2566740990 AmberWarningLamp 0 "Lamp Off" 1 "Lamp On" 2 "Reserved" 3 "Not available" ;
VAL_ 2566740990 RedStopLamp 0 "Lamp Off" 1 "Lamp On" 2 "Reserved" 3 "Not available" ;
VAL_ 2566740990 MalfunctionIndicatorLamp 0 "Lamp Off" 1 "Lamp On" 2 "Short MIL for WWH OBD" 3 "Not available" ;
VAL_ 2566740990 FlashProtectLamp 0 "Slow Flash (1 Hz, 50 % duty cycle)" 1 "Fast Flash (2 Hz or faster, 50% duty cycle)" 2 "Reserved" 3 "Unavailable / Do Not Flash" ;
VAL_ 2566740990 FlashAmberWarningLamp 0 "Slow Flash (1 Hz, 50 % duty cycle)" 1 "Fast Flash (2 Hz or faster, 50% duty cycle)" 2 "Reserved" 3 "Unavailable / Do Not Flash" ;
VAL_ 2566740990 FlashRedStopLamp 0 "Slow Flash (1 Hz, 50 % duty cycle)" 1 "Fast Flash (2 Hz or faster, 50% duty cycle)" 2 "Reserved" 3 "Unavailable / Do Not Flash" ;
VAL_ 2566740990 FlashMalfunctionIndicatorLamp 0 "Slow Flash (1 Hz, 50 % duty cycle)" 1 "Fast Flash (2 Hz or faster, 50% duty cycle)" 2 "Class C DTC  " 3 "Unavailable / Do Not Flash" ;
VAL_ 2566740990 SPNConversionMethod 0 "Convert SPN per Version 4" 1 "Convert SPN per Version 1, 2 or 3" ;
VAL_ 2566741246 ProtectLamp 0 "Lamp Off" 1 "Lamp On" 2 "Reserved" 3 "Not available" ;
VAL_ 2566741246 AmberWarningLamp 0 "Lamp Off" 1 "Lamp On" 2 "Reserved" 3 "Not available" ;
VAL_ 2566741246 RedStopLamp 0 "Lamp Off" 1 "Lamp On" 2 "Reserved" 3 "Not available" ;
VAL_ 2566741246 MalfunctionIndicatorLamp 0 "Lamp Off" 1 "Lamp On" 2 "Short MIL for WWH OBD" 3 "Not available" ;
VAL_ 2566741246 FlashProtectLamp 0 "Slow Flash (1 Hz, 50 % duty cycle)" 1 "Fast Flash (2 Hz or faster, 50% duty cycle)" 2 "Reserved" 3 "Unavailable / Do Not Flash" ;
VAL_ 2566741246 FlashAmberWarningLamp 0 "Slow Flash (1 Hz, 50 % duty cycle)" 1 "Fast Flash (2 Hz or faster, 50% duty cycle)" 2 "Reserved" 3 "Unavailable / Do Not Flash" ;
VAL_ 2566741246 FlashRedStopLamp 0 "Slow Flash (1 Hz, 50 % duty cycle)" 1 "Fast Flash (2 Hz or faster, 50% duty cycle)" 2 "Reserved" 3 "Unavailable / Do Not Flash" ;
VAL_ 2566741246 FlashMalfunctionIndicatorLamp 0 "Slow Flash (1 Hz, 50 % duty cycle)" 1 "Fast Flash (2 Hz or faster, 50% duty cycle)" 2 "Class C DTC  " 3 "Unavailable / Do Not Flash" ;
VAL_ 2566741246 SPNConversionMethod 0 "Convert SPN per Version 4" 1 "Convert SPN per Version 1, 2 or 3" ;
VAL_ 2566741502 ProtectLamp 0 "Lamp Off" 1 "Lamp On" 2 "Reserved" 3 "Not available" ;
VAL_ 2566741502 AmberWarningLamp 0 "Lamp Off" 1 "Lamp On" 2 "Reserved" 3 "Not available" ;
VAL_ 2566741502 RedStopLamp 0 "Lamp Off" 1 "Lamp On" 2 "Reserved" 3 "Not available" ;
VAL_ 2566741502 MalfunctionIndicatorLamp 0 "Lamp Off" 1 "Lamp On" 2 "Short MIL for WWH OBD" 3 "Not available" ;
VAL_ 2566741502 FlashProtectLamp 0 "Slow Flash (1 Hz, 50 % duty cycle)" 1 "Fast Flash (2 Hz or faster, 50% duty cycle)" 2 "Reserved" 3 "Unavailable / Do Not Flash" ;
VAL_ 2566741502 FlashAmberWarningLamp 0 "Slow Flash (1 Hz, 50 % duty cycle)" 1 "Fast Flash (2 Hz or faster, 50% duty cycle)" 2 "Reserved" 3 "Unavailable / Do Not Flash" ;
VAL_ 2566741502 FlashRedStopLamp 0 "Slow Flash (1 Hz, 50 % duty cycle)" 1 "Fast Flash (2 Hz or faster, 50% duty cycle)" 2 "Reserved" 3 "Unavailable / Do Not Flash" ;
VAL_ 2566741502 FlashMalfunctionIndicatorLamp 0 "Slow Flash (1 Hz, 50 % duty cycle)" 1 "Fast Flash (2 Hz or faster, 50% duty cycle)" 2 "Class C DTC  " 3 "Unavailable / Do Not Flash" ;
VAL_ 2566741502 SPNConversionMethod 0 "Convert SPN per Version 4" 1 "Convert SPN per Version 1, 2 or 3" ;
VAL_ 2566741758 ProtectLamp 0 "Lamp Off" 1 "Lamp On" 2 "Reserved" 3 "Not available" ;
VAL_ 2566741758 AmberWarningLamp 0 "Lamp Off" 1 "Lamp On" 2 "Reserved" 3 "Not available" ;
VAL_ 2566741758 RedStopLamp 0 "Lamp Off" 1 "Lamp On" 2 "Reserved" 3 "Not available" ;
VAL_ 2566741758 MalfunctionIndicatorLamp 0 "Lamp Off" 1 "Lamp On" 2 "Short MIL for WWH OBD" 3 "Not available" ;
VAL_ 2566741758 FlashProtectLamp 0 "Slow Flash (1 Hz, 50 % duty cycle)" 1 "Fast Flash (2 Hz or faster, 50% duty cycle)" 2 "Reserved" 3 "Unavailable / Do Not Flash" ;
VAL_ 2566741758 FlashAmberWarningLamp 0 "Slow Flash (1 Hz, 50 % duty cycle)" 1 "Fast Flash (2 Hz or faster, 50% duty cycle)" 2 "Reserved" 3 "Unavailable / Do Not Flash" ;
VAL_ 2566741758 FlashRedStopLamp 0 "Slow Flash (1 Hz, 50 % duty cycle)" 1 "Fast Flash (2 Hz or faster, 50% duty cycle)" 2 "Reserved" 3 "Unavailable / Do Not Flash" ;
VAL_ 2566741758 FlashMalfunctionIndicatorLamp 0 "Slow Flash (1 Hz, 50 % duty cycle)" 1 "Fast Flash (2 Hz or faster, 50% duty cycle)" 2 "Class C DTC  " 3 "Unavailable / Do Not Flash" ;
VAL_ 2566741758 SPNConversionMethod 0 "Convert SPN per Version 4" 1 "Convert SPN per Version 1, 2 or 3" ;
VAL_ 2566742014 ProtectLamp 0 "Lamp Off" 1 "Lamp On" 2 "Reserved" 3 "Not available" ;
VAL_ 2566742014 AmberWarningLamp 0 "Lamp Off" 1 "Lamp On" 2 "Reserved" 3 "Not available" ;
VAL_ 2566742014 RedStopLamp 0 "Lamp Off" 1 "Lamp On" 2 "Reserved" 3 "Not available" ;
VAL_ 2566742014 MalfunctionIndicatorLamp 0 "Lamp Off" 1 "Lamp On" 2 "Short MIL for WWH OBD" 3 "Not available" ;
VAL_ 2566742014 FlashProtectLamp 0 "Slow Flash (1 Hz, 50 % duty cycle)" 1 "Fast Flash (2 Hz or faster, 50% duty cycle)" 2 "Reserved" 3 "Unavailable / Do Not Flash" ;
VAL_ 2566742014 FlashAmberWarningLamp 0 "Slow Flash (1 Hz, 50 % duty cycle)" 1 "Fast Flash (2 Hz or faster, 50% duty cycle)" 2 "Reserved" 3 "Unavailable / Do Not Flash" ;
VAL_ 2566742014 FlashRedStopLamp 0 "Slow Flash (1 Hz, 50 % duty cycle)" 1 "Fast Flash (2 Hz or faster, 50% duty cycle)" 2 "Reserved" 3 "Unavailable / Do Not Flash" ;
VAL_ 2566742014 FlashMalfunctionIndicatorLamp 0 "Slow Flash (1 Hz, 50 % duty cycle)" 1 "Fast Flash (2 Hz or faster, 50% duty cycle)" 2 "Class C DTC  " 3 "Unavailable / Do Not Flash" ;
VAL_ 2566742014 SPNConversionMethod 0 "Convert SPN per Version 4" 1 "Convert SPN per Version 1, 2 or 3" ;
VAL_ 2566743038 SystemMalfnctnIndictrActvtnMode 0 "MI Activation Mode 1 (MI Off)" 1 "MI Activation Mode 2 (On Demand MI)" 2 "MI Activation Mode 3 (Short MI)" 3 "MI Activation Mode 4 (Continuous MI)" 14 "Error" 15 "Not available/Not required" ;
VAL_ 2566743038 SysMalfctIndictrDisplayStrategy 0 "System employs a non-discriminatory MI display" 1 "System employs a discriminatory MI display" 2 "Reserved" 3 "Not available/Not required" ;
VAL_ 2566743038 SystemCntnsMalfunctionIndicator 0 "System MI is not continuous" 1 "System MI is continuous" 2 "Reserved" 3 "Not available/Not required" ;
VAL_ 2566743550 Aftrtrtmnt1FuelPumpRelayControl 0 "off" 1 "on" 2 "reserved for SAE assignment" 3 "not available" ;
VAL_ 2566743550 Aft1FuelFlwDiverterVlvCtrl 0 "off" 1 "on" 2 "reserved for SAE assignment" 3 "not available" ;
VAL_ 2566744062 ZeroNetVehicleWeightChange 0 "No change to Net Vehicle Weight Change " 1 "Zero Net Vehicle Weight Change" 2 "Reserved" 3 "Not available / Not applicable" ;
VAL_ 2633853438 AxleGroupLocation 0 "Reserved" 1 "Sole or Forward-most Steer axle group" 2 "Lift axle group" 3 "Sole or Forward-most Drive axle group" 4 "Tag axle group" 5 "Additional tractor axle group" 6 "Trailer A axle group" 7 "Trailer B axle group" 8 "Trailer C axle group" 9 "Trailer D axle group" 10 "Trailer E axle group" 11 "Trailer F axle group" 12 "Trailer G axle group" 13 "Trailer H axle group" 14 "Additional trailer axle group" 15 "Reserved" ;
VAL_ 2633853438 AdditionalAxleGroupLocation 0 "Reserved" 1 "Rear Steer axle group" 2 "Rear Drive axle group" ;
VAL_ 2499635966 AxleGroupLocation 0 "Reserved" 1 "Sole or Forward-most Steer axle group" 2 "Lift axle group" 3 "Sole or Forward-most Drive axle group" 4 "Tag axle group" 5 "Additional tractor axle group" 6 "Trailer A axle group" 7 "Trailer B axle group" 8 "Trailer C axle group" 9 "Trailer D axle group" 10 "Trailer E axle group" 11 "Trailer F axle group" 12 "Trailer G axle group" 13 "Trailer H axle group" 14 "Additional trailer axle group" 15 "Reserved" ;
VAL_ 2499635966 AdditionalAxleGroupLocation 0 "Reserved" 1 "Rear Steer axle group" 2 "Rear Drive axle group" ;
VAL_ 2566745086 SoleOrFrwdMostSteerAxlGrpWghtAvl 0 "Steer axle group not present" 1 "Steer axle group present" 2 "Reserved" 3 "Not available / not applicable" ;
VAL_ 2566745086 LiftAxleGroupWeightAvailable 0 "Lift axle group not present" 1 "Lift axle group present" 2 "Reserved" 3 "Not available / not applicable" ;
VAL_ 2566745086 SoleOrFrwdMostDrvAxlGrpWeightAvl 0 "Drive axle group not present" 1 "Drive axle group present" 2 "Reserved" 3 "Not available / not applicable" ;
VAL_ 2566745086 TagAxleGroupWeightAvailable 0 "Tag axle group not present" 1 "Tag axle group present" 2 "Reserved" 3 "Not available / not applicable" ;
VAL_ 2566745086 AddtnlTractorAxlGroupWeightAvail 0 "Additional tractor axle group not present" 1 "Additional tractor axle group present" 2 "Reserved" 3 "Not available / not applicable" ;
VAL_ 2566745086 TrailerAAxleGroupWeightAvailable 0 "Trailer A axle group not present" 1 "Trailer A axle group present" 2 "Reserved" 3 "Not available / not applicable" ;
VAL_ 2566745086 TrailerBAxleGroupWeightAvailable 0 "Trailer B axle group not present" 1 "Trailer B axle group present" 2 "Reserved" 3 "Not available / not applicable" ;
VAL_ 2566745086 TrailerCAxleGroupWeightAvailable 0 "Trailer C axle group not present" 1 "Trailer C axle group present" 2 "Reserved" 3 "Not available / not applicable" ;
VAL_ 2566745086 TrailerDAxleGroupWeightAvailable 0 "Trailer D axle group not present" 1 "Trailer D axle group present" 2 "Reserved" 3 "Not available / not applicable" ;
VAL_ 2566745086 TrailerEAxleGroupWeightAvailable 0 "Trailer E axle group not present" 1 "Trailer E axle group present" 2 "Reserved" 3 "Not available / not applicable" ;
VAL_ 2566745086 TrailerFAxleGroupWeightAvailable 0 "Trailer F axle group not present" 1 "Trailer F axle group present" 2 "Reserved" 3 "Not available / not applicable" ;
VAL_ 2566745086 TrailerGAxleGroupWeightAvailable 0 "Trailer G axle group not present" 1 "Trailer G axle group present" 2 "Reserved" 3 "Not available / not applicable" ;
VAL_ 2566745086 TrailerHAxleGroupWeightAvailable 0 "Trailer H axle group not present" 1 "Trailer H axle group present" 2 "Reserved" 3 "Not available / not applicable" ;
VAL_ 2566745086 AddtnlTrailerAxlGroupWeightAvail 0 "Additional trailer axle group not present" 1 "Additional trailer axle group present" 2 "Reserved" 3 "Not available / not applicable" ;
VAL_ 2566745086 RearSteerAxleGroupWeightAvail 0 "Rear Steer axle group not present" 1 "Rear Steer axle group present" 2 "Reserved" 3 "Not available / not applicable" ;
VAL_ 2566745086 RearDriveAxleGroupWeightAvail 0 "Rear drive axle group not present" 1 "Rear drive axle group present" 2 "Reserved" 3 "Not available / not applicable" ;
VAL_ 2566746366 RetractStatusOfRamp1 0 "ramp retracted" 1 "ramp extended " 2 "error " 3 "not available" ;
VAL_ 2566746366 EnableStatusOfRamp1 0 "ramp disabled" 1 "ramp enabled " 2 "error " 3 "not available" ;
VAL_ 2566746366 MovementStatusOfRamp1 0 "ramp not being moved" 1 "ramp being moved" 2 "error" 3 "not available" ;
VAL_ 2566746366 RetractStatusOfRamp2 0 "ramp retracted" 1 "ramp extended " 2 "error " 3 "not available" ;
VAL_ 2566746366 EnableStatusOfRamp2 0 "ramp disabled" 1 "ramp enabled " 2 "error " 3 "not available" ;
VAL_ 2566746366 MovementStatusOfRamp2 0 "ramp not being moved" 1 "ramp being moved" 2 "error" 3 "not available" ;
VAL_ 2566746366 RetractStatusOfRamp3 0 "ramp retracted" 1 "ramp extended " 2 "error " 3 "not available" ;
VAL_ 2566746366 EnableStatusOfRamp3 0 "ramp disabled" 1 "ramp enabled " 2 "error " 3 "not available" ;
VAL_ 2566746366 MovementStatusOfRamp3 0 "ramp not being moved" 1 "ramp being moved" 2 "error" 3 "not available" ;
VAL_ 2566746366 RetractStatusOfRamp4 0 "ramp retracted" 1 "ramp extended " 2 "error " 3 "not available" ;
VAL_ 2566746366 EnableStatusOfRamp4 0 "ramp disabled" 1 "ramp enabled " 2 "error " 3 "not available" ;
VAL_ 2566746366 MovementStatusOfRamp4 0 "ramp not being moved" 1 "ramp being moved" 2 "error" 3 "not available" ;
VAL_ 2566746366 RetractStatusOfRamp5 0 "ramp retracted" 1 "ramp extended " 2 "error " 3 "not available" ;
VAL_ 2566746366 EnableStatusOfRamp5 0 "ramp disabled" 1 "ramp enabled " 2 "error " 3 "not available" ;
VAL_ 2566746366 MovementStatusOfRamp5 0 "ramp not being moved" 1 "ramp being moved" 2 "error" 3 "not available" ;
VAL_ 2566746622 TractorBrakeStrokeAxle1Left 0 "OK (Normal operation)  " 1 "Non-functioning" 2 "Overstroke " 3 "Dragging brake" 4 "Reserved" 5 "Reserved" 6 "Sensor error" 7 "Not available" ;
VAL_ 2566746622 TractorBrakeStrokeAxle1Right 0 "OK (Normal operation)" 1 "Non-functioning" 2 "Overstroke" 3 "Dragging brake" 4 "Reserved" 5 "Reserved" 6 "Sensor error" 7 "Not available" ;
VAL_ 2566746622 TractorBrakeStrokeAxle2Left 0 "OK (Normal operation)" 1 "Non-functioning" 2 "Overstroke" 3 "Dragging brake" 4 "Reserved" 5 "Reserved" 6 "Sensor error" 7 "Not available" ;
VAL_ 2566746622 TractorBrakeStrokeAxle2Right 0 "OK (Normal operation)" 1 "Non-functioning" 2 "Overstroke" 3 "Dragging brake" 4 "Reserved" 5 "Reserved" 6 "Sensor error" 7 "Not available" ;
VAL_ 2566746622 TractorBrakeStrokeAxle3Left 0 "OK (Normal operation)" 1 "Non-functioning" 2 "Overstroke" 3 "Dragging brake" 4 "Reserved" 5 "Reserved" 6 "Sensor error" 7 "Not available" ;
VAL_ 2566746622 TractorBrakeStrokeAxle3Right 0 "OK (Normal operation)" 1 "Non-functioning" 2 "Overstroke" 3 "Dragging brake" 4 "Reserved" 5 "Reserved" 6 "Sensor error" 7 "Not available" ;
VAL_ 2566746622 TractorBrakeStrokeAxle4Left 0 "OK (Normal operation)" 1 "Non-functioning" 2 "Overstroke" 3 "Dragging brake" 4 "Reserved" 5 "Reserved" 6 "Sensor error" 7 "Not available" ;
VAL_ 2566746622 TractorBrakeStrokeAxle4Right 0 "OK (Normal operation)" 1 "Non-functioning" 2 "Overstroke" 3 "Dragging brake" 4 "Reserved" 5 "Reserved" 6 "Sensor error" 7 "Not available" ;
VAL_ 2566746622 TractorBrakeStrokeAxle5Left 0 "OK (Normal operation)" 1 "Non-functioning" 2 "Overstroke" 3 "Dragging brake" 4 "Reserved" 5 "Reserved" 6 "Sensor error" 7 "Not available" ;
VAL_ 2566746622 TractorBrakeStrokeAxle5Right 0 "OK (Normal operation)" 1 "Non-functioning" 2 "Overstroke" 3 "Dragging brake" 4 "Reserved" 5 "Reserved" 6 "Sensor error" 7 "Not available" ;
VAL_ 2566746622 TrailerBrakeStrokeAxle1Left 0 "OK (Normal operation)" 1 "Non-functioning" 2 "Overstroke" 3 "Dragging brake" 4 "Reserved" 5 "Reserved" 6 "Sensor error" 7 "Not available" ;
VAL_ 2566746622 TrailerBrakeStrokeAxle1Right 0 "OK (Normal operation)" 1 "Non-functioning" 2 "Overstroke" 3 "Dragging brake" 4 "Reserved" 5 "Reserved" 6 "Sensor error" 7 "Not available" ;
VAL_ 2566746622 TrailerBrakeStrokeAxle2Left 0 "OK (Normal operation)" 1 "Non-functioning" 2 "Overstroke" 3 "Dragging brake" 4 "Reserved" 5 "Reserved" 6 "Sensor error" 7 "Not available" ;
VAL_ 2566746622 TrailerBrakeStrokeAxle2Right 0 "OK (Normal operation)" 1 "Non-functioning" 2 "Overstroke" 3 "Dragging brake" 4 "Reserved" 5 "Reserved" 6 "Sensor error" 7 "Not available" ;
VAL_ 2566746622 TrailerBrakeStrokeAxle3Left 0 "OK (Normal operation)" 1 "Non-functioning" 2 "Overstroke" 3 "Dragging brake" 4 "Reserved" 5 "Reserved" 6 "Sensor error" 7 "Not available" ;
VAL_ 2566746622 TrailerBrakeStrokeAxle3Right 0 "OK (Normal operation)" 1 "Non-functioning" 2 "Overstroke" 3 "Dragging brake" 4 "Reserved" 5 "Reserved" 6 "Sensor error" 7 "Not available" ;
VAL_ 2566746622 TrailerBrakeStrokeAxle4Left 0 "OK (Normal operation)" 1 "Non-functioning" 2 "Overstroke" 3 "Dragging brake" 4 "Reserved" 5 "Reserved" 6 "Sensor error" 7 "Not available" ;
VAL_ 2566746622 TrailerBrakeStrokeAxle4Right 0 "OK (Normal operation)" 1 "Non-functioning" 2 "Overstroke" 3 "Dragging brake" 4 "Reserved" 5 "Reserved" 6 "Sensor error" 7 "Not available" ;
VAL_ 2566746622 TrailerBrakeStrokeAxle5Left 0 "OK (Normal operation)" 1 "Non-functioning" 2 "Overstroke" 3 "Dragging brake" 4 "Reserved" 5 "Reserved" 6 "Sensor error" 7 "Not available" ;
VAL_ 2566746622 TrailerBrakeStrokeAxle5Right 0 "OK (Normal operation)" 1 "Non-functioning" 2 "Overstroke" 3 "Dragging brake" 4 "Reserved" 5 "Reserved" 6 "Sensor error" 7 "Not available" ;
VAL_ 2566749438 DieselParticulateFilterLampCmd 0 "Off" 1 "On - solid" 2 "reserved for SAE assignment " 3 "reserved for SAE assignment" 4 "On - fast blink (1 HZ)" 5 "reserved for SAE assignment" 6 "reserved for SAE assignment" 7 "not available" ;
VAL_ 2566749438 DslPFActvRegenAvailabilityStatus 0 "Not ready for initiation" 1 "Ready for initiation" 2 "Reserved" 3 "Not Available" ;
VAL_ 2566749438 AftrtrtmntDslPFPassiveRegenStat 0 "Not active" 1 "Active" 2 "Reserved for SAE assignment" 3 "Not available" ;
VAL_ 2566749438 AftrtrtmntDslPFActvRegenStatus 0 "not active" 1 "active" 2 "regeneration needed" 3 "not available" ;
VAL_ 2566749438 AftrtrtmntDslPFStatus 0 "Regeneration not needed" 1 "Regeneration needed - lowest level" 2 "Regeneration needed - moderate level" 3 "Regeneration needed - highest level" 4 "reserved for SAE assignment" 5 "reserved for SAE assignment" 6 "reserved for SAE assignment" 7 "not available" ;
VAL_ 2566749438 DslPFActvRegenInhbtdStatus 0 "Not Inhibited" 1 "Inhibited" 2 "Reserved for SAE assignment" 3 "Not Available" ;
VAL_ 2566749438 DslPFActvRegenInhbtdDTInhbtSw 0 "Not Inhibited" 1 "Inhibited" 2 "Reserved for SAE assignment" 3 "Not Available" ;
VAL_ 2566749438 DslPFActRegenInhbtdDTCltchDiseng 0 "Not Inhibited" 1 "Inhibited" 2 "Reserved for SAE assignment" 3 "Not Available" ;
VAL_ 2566749438 DslPFActRegenInhbtdDTSrvcBrkActv 0 "Not Inhibited" 1 "Inhibited" 2 "Reserved for SAE assignment" 3 "Not Available" ;
VAL_ 2566749438 DslPFActvRegenInhbtdDTPTOActv 0 "Not Inhibited" 1 "Inhibited" 2 "Reserved for SAE assignment" 3 "Not Available" ;
VAL_ 2566749438 DPFActRegenInhbtdDTAcclPdlOffIdl 0 "Not Inhibited" 1 "Inhibited" 2 "Reserved for SAE assignment" 3 "Not Available" ;
VAL_ 2566749438 DslPFActvRegenInhbtdDTOutOfNtrl 0 "Not Inhibited" 1 "Inhibited" 2 "Reserved for SAE assignment" 3 "Not Available" ;
VAL_ 2566749438 DPFActRegInhDTVhclSpdAbvAllwdSpd 0 "Not Inhibited" 1 "Inhibited" 2 "Reserved for SAE assignment" 3 "Not Available" ;
VAL_ 2566749438 DPFActRegenInhbtdDTPrkBrkNotSet 0 "Not Inhibited" 1 "Inhibited" 2 "Reserved for SAE assignment" 3 "Not Available" ;
VAL_ 2566749438 DPFActRegenInhbtdDTLowExhstTemp 0 "Not Inhibited" 1 "Inhibited" 2 "Reserved for SAE assignment" 3 "Not Available" ;
VAL_ 2566749438 DslPFActRegenInhbtdDTSysFaultAct 0 "Not Inhibited" 1 "Inhibited" 2 "Reserved for SAE assignment" 3 "Not Available" ;
VAL_ 2566749438 DslPFActvRegenInhbtdDTSysTimeout 0 "Not Inhibited" 1 "Inhibited" 2 "Reserved for SAE assignment" 3 "Not Available" ;
VAL_ 2566749438 DPFActRegenInhbtdDTTmprySysLckt 0 "Not Inhibited" 1 "Inhibited" 2 "Reserved for SAE assignment" 3 "Not Available" ;
VAL_ 2566749438 DPFActRegenInhbtdDTPrmntSysLckt 0 "Not Inhibited" 1 "Inhibited" 2 "Reserved for SAE assignment" 3 "Not Available" ;
VAL_ 2566749438 DPFActRegInhbtdDTEngNotWarmedUp 0 "Not Inhibited" 1 "Inhibited" 2 "Reserved for SAE assignment" 3 "Not Available" ;
VAL_ 2566749438 DPFActRegInhDTVhclSpdBlwAllwdSpd 0 "Not Inhibited" 1 "Inhibited" 2 "Reserved for SAE assignment" 3 "Not Available" ;
VAL_ 2566749438 DslPFAutoActvRegenInitConf 0 "not enabled" 1 "enabled" 2 "reserved for SAE assignment" 3 "not available" ;
VAL_ 2566749438 ExhstSystemHghTemperatureLampCmd 0 "Off" 1 "On - solid " 2 "reserved for SAE assignment " 3 "reserved for SAE assignment" 4 "reserved for SAE assignment" 5 "reserved for SAE assignment" 6 "reserved for SAE assignment" 7 "not available" ;
VAL_ 2566749438 DslPFActvRegenForcedStatus 0 "Not Active" 1 "Active - Forced by Switch (See SPN 3696)" 2 "Active - Forced by Service Tool " 3 "Reserved for SAE Assignment" 4 "Reserved for SAE Assignment" 5 "Reserved for SAE Assignment" 6 "Reserved for SAE Assignment" 7 "not available" ;
VAL_ 2566749438 HydrocarbonDoserPurgingEnable 0 "Purging not enabled" 1 "Purging enabled" 2 "Purging enabled" 3 "Not available" ;
VAL_ 2566749438 DPFActRegenInhbtdDTLowExhstPress 0 "Not Inhibited" 1 "Inhibited" 2 "Reserved for SAE assignment" 3 "Not Available" ;
VAL_ 2566749438 Aft1DPFConditionsNotMetForActReg 0 "active DPF regeneration not inhibited" 1 "active DPF regeneration inhibited" 2 "reserved for SAE assignment" 3 "not available" ;
VAL_ 2566749950 LeftHeadlampDynamicBendingLight 0 "Dynamic bending light deactivated" 1 "Dynamic bending light is working properly" 2 "Dynamic bending light fail safe position" 3 "Dynamic bending light failure" 7 "Not available" ;
VAL_ 2566749950 RightHeadlampDynamicBendingLight 0 "Dynamic bending light deactivated" 1 "Dynamic bending light is working properly" 2 "Dynamic bending light fail safe position" 3 "Dynamic bending light failure" 7 "Not available" ;
VAL_ 2566749950 LeftHeadlampLightDistribution 0 "Light distribution town" 1 "Light distribution country" 2 "Light distribution motorway" 3 "Light distribution high beam" 4 "Light distribution adverse weather" 5 "Light distribution fail safe position" 6 "Light distribution failure" 7 "Different light distributions not available" 15 "Not available" ;
VAL_ 2566749950 RightHeadlampLightDistribution 0 "Light distribution town" 1 "Light distribution country" 2 "Light distribution motorway" 3 "Light distribution high beam" 4 "Light distribution adverse weather" 5 "Light distribution fail safe position" 6 "Light distribution failure" 7 "Different light distributions not available" 15 "Not available" ;
VAL_ 2566750206 TrnsmIdlGvrnrFuelngInhbtSupp 0 "The engine does not support the 'Transmission Idle Governor Fueling Inhibit'" 1 "The engine will respond to a 'Transmission Idle Governor Fueling Inhibit' command from the Transmission, should it be received" 2 "Reserved for future SAE use" 3 "Not supported" ;
VAL_ 2566750462 ProtectLamp 0 "Lamp Off" 1 "Lamp On" 2 "Reserved" 3 "Not available" ;
VAL_ 2566750462 AmberWarningLamp 0 "Lamp Off" 1 "Lamp On" 2 "Reserved" 3 "Not available" ;
VAL_ 2566750462 RedStopLamp 0 "Lamp Off" 1 "Lamp On" 2 "Reserved" 3 "Not available" ;
VAL_ 2566750462 MalfunctionIndicatorLamp 0 "Lamp Off" 1 "Lamp On" 2 "Short MIL for WWH OBD" 3 "Not available" ;
VAL_ 2566750462 FlashProtectLamp 0 "Slow Flash (1 Hz, 50 % duty cycle)" 1 "Fast Flash (2 Hz or faster, 50% duty cycle)" 2 "Reserved" 3 "Unavailable / Do Not Flash" ;
VAL_ 2566750462 FlashAmberWarningLamp 0 "Slow Flash (1 Hz, 50 % duty cycle)" 1 "Fast Flash (2 Hz or faster, 50% duty cycle)" 2 "Reserved" 3 "Unavailable / Do Not Flash" ;
VAL_ 2566750462 FlashRedStopLamp 0 "Slow Flash (1 Hz, 50 % duty cycle)" 1 "Fast Flash (2 Hz or faster, 50% duty cycle)" 2 "Reserved" 3 "Unavailable / Do Not Flash" ;
VAL_ 2566750462 FlashMalfunctionIndicatorLamp 0 "Slow Flash (1 Hz, 50 % duty cycle)" 1 "Fast Flash (2 Hz or faster, 50% duty cycle)" 2 "Class C DTC  " 3 "Unavailable / Do Not Flash" ;
VAL_ 2566750462 SPNConversionMethod 0 "Convert SPN per Version 4" 1 "Convert SPN per Version 1, 2 or 3" ;
VAL_ 2566750974 ProtectLamp 0 "Lamp Off" 1 "Lamp On" 2 "Reserved" 3 "Not available" ;
VAL_ 2566750974 AmberWarningLamp 0 "Lamp Off" 1 "Lamp On" 2 "Reserved" 3 "Not available" ;
VAL_ 2566750974 RedStopLamp 0 "Lamp Off" 1 "Lamp On" 2 "Reserved" 3 "Not available" ;
VAL_ 2566750974 MalfunctionIndicatorLamp 0 "Lamp Off" 1 "Lamp On" 2 "Short MIL for WWH OBD" 3 "Not available" ;
VAL_ 2566750974 FlashProtectLamp 0 "Slow Flash (1 Hz, 50 % duty cycle)" 1 "Fast Flash (2 Hz or faster, 50% duty cycle)" 2 "Reserved" 3 "Unavailable / Do Not Flash" ;
VAL_ 2566750974 FlashAmberWarningLamp 0 "Slow Flash (1 Hz, 50 % duty cycle)" 1 "Fast Flash (2 Hz or faster, 50% duty cycle)" 2 "Reserved" 3 "Unavailable / Do Not Flash" ;
VAL_ 2566750974 FlashRedStopLamp 0 "Slow Flash (1 Hz, 50 % duty cycle)" 1 "Fast Flash (2 Hz or faster, 50% duty cycle)" 2 "Reserved" 3 "Unavailable / Do Not Flash" ;
VAL_ 2566750974 FlashMalfunctionIndicatorLamp 0 "Slow Flash (1 Hz, 50 % duty cycle)" 1 "Fast Flash (2 Hz or faster, 50% duty cycle)" 2 "Class C DTC  " 3 "Unavailable / Do Not Flash" ;
VAL_ 2566750974 SPNConversionMethod 0 "Convert SPN per Version 4" 1 "Convert SPN per Version 1, 2 or 3" ;
VAL_ 2566751230 TransferCaseStatus 0 "2 wheel high" 1 "4 wheel high" 2 "Neutral" 3 "2 wheel low" 4 "4 wheel low" 5 "Transfer Case Shift in Progress" 6 "Error" 7 "Not available" ;
VAL_ 2566751230 TransferCaseDirectionStatus 0 "Forward" 1 "Reverse" 2 "Error" 3 "Not Available" ;
VAL_ 2633861886 J2012DTCStatus 0 "DTC is previously active" 1 "DTC is active" ;
VAL_ 2566754558 AETCDataCollectionStandard 0 "SAE J1995" 15 "Not Available" ;
VAL_ 2566754814 GeneratorCircuitBreakerStatus 0 "Open" 1 "Closed" 2 "Locked Out" 3 "Transitioning to Open state" 4 "Transitioning to Closed state" 5 "Available for SAE assignment" 6 "Error" 7 "Not Available" ;
VAL_ 2566754814 UtilityCircuitBreakerStatus 0 "Open" 1 "Closed" 2 "Locked Out" 3 "Transitioning to Open state" 4 "Transitioning to Closed state" 5 "Available for SAE assignment" 6 "Error" 7 "Not Available" ;
VAL_ 2566754814 AutomaticTransferSwitchStatus 0 "Normal position" 1 "Emergency position" 2 "Available for SAE assignment" 3 "Transitioning to Normal position" 4 "Transitioning to Emergency position" 5 "Available for SAE assignment" 6 "Error" 7 "Not Available" ;
VAL_ 2566754814 EngineSpeedGovernorMode 0 "Isochronous Mode" 1 "Droop Mode" 2 "Error" 3 "Not Available" ;
VAL_ 2566754814 BusTieBreaker1 0 "Open" 1 "Closed" 2 "Locked Out" 3 "Transitioning to Open state" 4 "Transitioning to Closed state" 5 "Available for SAE assignment" 6 "Error" 7 "Not Available" ;
VAL_ 2566754814 BusTieBreaker2 0 "Open" 1 "Closed" 2 "Locked Out" 3 "Transitioning to Open state" 4 "Transitioning to Closed state" 5 "Available for SAE assignment" 6 "Error" 7 "Not Available" ;
VAL_ 2365428478 EngineOperatingState 0 "Engine Stopped" 1 "Pre-Start" 2 "Starting" 3 "Warm-Up" 4 "Running" 5 "Cool-down" 6 "Engine Stopping" 7 "Post-Run" 14 "<reserved>" 15 "not available" ;
VAL_ 2365428478 FuelPumpPrimerControl 0 "Deactivate" 1 "Activate" 2 "Reserved" 3 "Unavailable" ;
VAL_ 2365428478 EngineStarterMotorRelayControl 0 "Off" 1 "On" 2 "Reserved for SAE assignment" 3 "Don't care/take no action" ;
VAL_ 2365428478 EngineFuelShutoffVentControl 0 "Closed" 1 "Open" 2 "Reserved" 3 "Don't care / take no action" ;
VAL_ 2365428478 EngineFuelShutoff1Control 0 "Open (fuel supplied to engine)" 1 "Closed (no fuel supplied to engine)" 2 "Reserved" 3 "Don't care / take no action" ;
VAL_ 2365428478 EngineFuelShutoff2Control 0 "Open (fuel supplied to engine)" 1 "Closed (no fuel supplied to engine)" 2 "Reserved" 3 "Don't care / take no action" ;
VAL_ 2365428478 EngFuelShutoffValveLeakTestCtrl 0 "Off (reset / no test in process)" 1 "On (test in process / test complete)" 2 "Reserved" 3 "Don't care / take no action" ;
VAL_ 2365428478 EngineOilPrimingPumpControl 0 "Off" 1 "On" 2 "Reserved" 3 "unavailable" ;
VAL_ 2365428478 EngineOilPreHeaterControl 0 "Off" 1 "On" 2 "Reserved" 3 "Don't care / take no action" ;
VAL_ 2365428478 EngElectrclSystemPwrConservCtrl 0 "Off" 1 "On" 2 "Reserved" 3 "unavailable" ;
VAL_ 2365428478 EnginePreHeaterControl 0 "Off " 1 "On" 2 "Reserved" 3 "Unavailable" ;
VAL_ 2365428478 EngineCoolantPumpControl 0 "Off" 1 "On" 2 "Reserved" 3 "Don't care / take no action" ;
VAL_ 2365428478 EngineControlledShutdownRequest 0 "Off" 1 "On" 2 "Reserved" 3 "Don't care / take no action" ;
VAL_ 2365428478 EngineEmrgncyShutdownIndication 0 "Off" 1 "On" 2 "Reserved" 3 "Don't care / take no action" ;
VAL_ 2365428478 EngColdAmbientElevatedIdleStatus 0 "No Idle Elevation Active" 1 "Idle Elevation Active" 2 "Reserved for SAE assignment" 3 "Unavailable" ;
VAL_ 2365428734 RequestedEngineControlMode 0 "Normal Engine Shutdown" 1 "Rapid Engine Shutdown" 2 "Emergency Engine Shutdown" 3 "Normal Engine Start" 4 "Rapid Engine Start" 14 "<reserved>" 15 "Don't Care / Take No Action" ;
VAL_ 2365428734 GeneratorCtrlNotInAutoStartState 0 "inactive" 1 "active" 2 "error" 3 "not available" ;
VAL_ 2365428734 GenNotReadyToAutoParallelState 0 "inactive" 1 "active" 2 "error" 3 "not available" ;
VAL_ 2365428734 GeneratorGoverningSpeedCommand 0 "Rated Speed" 1 "Low Idle Speed" 2 "Reserved" 3 "Don't care / take no action" ;
VAL_ 2365428734 GeneratorFrequencySelection 0 "50 Hz" 1 "60 Hz" 2 "400 Hz" 3 "SAE Reserved" 14 "Unknown" 15 " Don't care /take no action" ;
VAL_ 2566755838 TrnsmOilFilterRestrictionSw 0 "No restriction" 1 "Restriction exists on oil filter" 2 "Error" 3 "Not available" ;
VAL_ 2566755838 TransmissionOilLevelSwitch 0 "Empty" 1 "Full or not empty" 2 "Error" 3 "Not available" ;
VAL_ 2566755838 TransmissionOverheatIndicator 0 "Transmission Overheat Indicator is off" 1 "Transmission Overheat Indicator is on continuously" 2 "Transmission Overheat Indicator is flashing" 3 "Not available" ;
VAL_ 2566755838 TransmissionOilLvl2CntdownTimer 0 "less than 1 minute" 1 "One minute" 2 "Two minutes" 3 "Three minutes" 4 "Four minutes" 5 "Five minutes" 6 "Six minutes" 7 "Seven minutes" 8 "Eight minutes" 9 "Nine minutes" 10 "Ten minutes" 11 "Eleven minutes" 12 "Twelve minutes" 13 "Thirteen minutes" 14 "Error" 15 "Not Available" ;
VAL_ 2566755838 TransmissionOilLvl2MeasureStatus 0 "Conditions valid for transmission oil level measurement" 1 "Conditions not valid - Settling timer still counting down" 2 "Conditions not valid - Transmission in gear" 3 "Conditions not valid - Transmission fluid temperature too low" 4 "Conditions not valid - Transmission fluid temperature too high" 5 "Conditions not valid - Vehicle moving" 6 "Conditions not valid - Vehicle not level" 7 "Conditions not valid - Engine speed too low" 8 "Conditions not valid - Engine speed too high" 9 "Conditions not valid - No request for reading" 10 "Not defined" 11 "Not defined" 12 "Not defined" 13 "Conditions not valid" 14 "Error" 15 "Not available" ;
VAL_ 2566757374 Aftrtrtmnt1DslExhstFluidProperty 0 "Urea concentration too high" 1 "Urea concentration too low" 2 "Fluid is diesel" 3 "Diesel exhaust fluid is proper mixture" 12 "Diesel exhaust fluid, but concentration cannot be determined" 13 "Not able to determine fluid property" 14 "Error with diesel exhaust fluid property detection" 15 "Not available" ;
VAL_ 2566758142 Aftertreatment2AirSystemRelay 0 "Not active" 1 "Active" 2 "Reserved for SAE assignment" 3 "Not available" ;
VAL_ 2566758142 Aftrtrtmnt2AtomizationAirActr 0 "Not active" 1 "Active" 2 "Reserved for SAE assignment" 3 "Not available" ;
VAL_ 2566758142 Aftertreatment2PurgeAirActuator 0 "Not active" 1 "Active" 2 "Reserved for SAE assignment" 3 "Not available" ;
VAL_ 2566758142 Aftertreatment2AirEnableActuator 0 "Not active" 1 "Active" 2 "Reserved for SAE assignment" 3 "Not available" ;
VAL_ 2566758398 Aftertreatment1AirSystemRelay 0 "Not active" 1 "Active" 2 "Reserved for SAE assignment" 3 "Not available" ;
VAL_ 2566758398 Aftrtrtmnt1AtomizationAirActr 0 "Not active" 1 "Active" 2 "Reserved for SAE assignment" 3 "Not available" ;
VAL_ 2566758398 Aftertreatment1PurgeAirActuator 0 "Not active" 1 "Active" 2 "Reserved for SAE assignment" 3 "Not available" ;
VAL_ 2566758398 Aftertreatment1AirEnableActuator 0 "Not active" 1 "Active" 2 "Reserved for SAE assignment" 3 "Not available" ;
VAL_ 2566758654 Aftertreatment2FuelDrainActuator 0 "Not active" 1 "Active" 2 "Reserved for SAE assignment" 3 "Not available" ;
VAL_ 2566758654 Aftertreatment2Ignition 0 "Not active" 1 "Active" 2 "Reserved for SAE assignment" 3 "Not available" ;
VAL_ 2566758654 Aftrtrtmnt2RegenerationStatus 0 "Not active" 1 "Active" 2 "Reserved for SAE assignment" 3 "Not available" ;
VAL_ 2566758654 Aftertreatment2FuelEnableActr 0 "Not active" 1 "Active" 2 "Reserved for SAE assignment" 3 "Not available" ;
VAL_ 2566758910 Aftertreatment1FuelDrainActuator 0 "Not active" 1 "Active" 2 "Reserved for SAE assignment" 3 "Not available" ;
VAL_ 2566758910 Aftertreatment1Ignition 0 "Not active" 1 "Active" 2 "Reserved for SAE assignment" 3 "Not available" ;
VAL_ 2566758910 Aftrtrtmnt1RegenerationStatus 0 "Not active" 1 "Active" 2 "Reserved for SAE assignment" 3 "Not available" ;
VAL_ 2566758910 Aftertreatment1FuelEnableActr 0 "Not active" 1 "Active" 2 "Reserved for SAE assignment" 3 "Not available" ;
VAL_ 2432541694 EngTurboCmprBypssActr1TempStat 0 "High Most severe" 1 "High Least severe" 2 "In Range" 3 "Low Least severe" 4 "Low Most severe" 5 "Not Defined" 6 "Error" 7 "Not available" ;
VAL_ 2566759678 EnblSwitchTransferCsOutptShftPTO 0 "Enable switch off - PTO operation not desired" 1 "Enable switch on - PTO operation desired" 2 "Error" 3 "Not available" ;
VAL_ 2566759678 EnblSwTransmissionOutptShftPTO 0 "Enable switch off - PTO operation not desired" 1 "Enable switch on - PTO operation desired" 2 "Error" 3 "Not available" ;
VAL_ 2566759678 EnblSwTransmissionInputShftPTO2 0 "Enable switch off - PTO operation not desired" 1 "Enable switch on - PTO operation desired" 2 "Error" 3 "Not available" ;
VAL_ 2566759678 EnblSwTransmissionInputShftPTO1 0 "Enable switch off - PTO operation not desired" 1 "Enable switch on - PTO operation desired" 2 "Error" 3 "Not available" ;
VAL_ 2566759678 EnableSwitchPTOEngineFlywheel 0 "Enable switch off - PTO operation not desired" 1 "Enable switch on - PTO operation desired " 2 "Error" 3 "Not available" ;
VAL_ 2566759678 EnableSwitchPTOEngineAccssryDrv1 0 "Enable switch off - PTO operation not desired" 1 "Enable switch on - PTO operation desired" 2 "Error" 3 "Not available" ;
VAL_ 2566759678 EnableSwitchPTOEngineAccssryDrv2 0 "Enable switch off - PTO operation not desired" 1 "Enable switch on - PTO operation desired" 2 "Error" 3 "Not available" ;
VAL_ 2566759678 EngmntConsntTrnsfrCsOutptShftPTO 0 "Consent not given" 1 "Consent given" 2 "Error" 3 "Not available" ;
VAL_ 2566759678 EngmntConsntTrnsmOutptShftPTO 0 "Consent not given" 1 "Consent given" 2 "Error" 3 "Not available" ;
VAL_ 2566759678 EngmntConsntTrnsmInputShftPTO2 0 "Consent not given" 1 "Consent given" 2 "Error" 3 "Not available" ;
VAL_ 2566759678 EngmntConsntTrnsmInputShftPTO1 0 "Consent not given" 1 "Consent given" 2 "Error" 3 "Not available" ;
VAL_ 2566759678 EngmntConsntPTOEngineFlywheel 0 "Consent not given" 1 "Consent given" 2 "Error" 3 "Not available" ;
VAL_ 2566759678 EngmntConsntPTOEngineAccssryDrv1 0 "Consent not given" 1 "Consent given" 2 "Error" 3 "Not available" ;
VAL_ 2566759678 EngmntConsntPTOEngineAccssryDrv2 0 "Consent not given" 1 "Consent given" 2 "Error" 3 "Not available" ;
VAL_ 2566759678 EngmntStatTransferCsOutptShftPTO 0 "Drive not engaged" 1 "Drive is engaged" 2 "Error" 3 "Not available" ;
VAL_ 2566759678 EngmntStatTrnsmOutptShftPTO 0 "Drive not engaged" 1 "Drive is engaged" 2 "Error" 3 "Not available" ;
VAL_ 2566759678 EngmntStatTrnsmInputShftPTO2 0 "Drive not engaged" 1 "Drive is engaged" 2 "Error" 3 "Not available" ;
VAL_ 2566759678 EngmntStatTrnsmInputShftPTO1 0 "Drive not engaged" 1 "Drive is engaged" 2 "Error" 3 "Not available" ;
VAL_ 2566759678 EngmntStatusPTOEngineFlywheel 0 "Drive not engaged" 1 "Drive engaged" 2 "Error" 3 "Not available" ;
VAL_ 2566759678 EngmntStatusPTOEngineAccssryDrv1 0 "Drive not engaged" 1 "Drive engaged" 2 "Error" 3 "Not available" ;
VAL_ 2566759678 EngmntStatusPTOEngineAccssryDrv2 0 "Drive not engaged" 1 "Drive engaged" 2 "Error" 3 "Not available" ;
VAL_ 2566759678 AtLeastOnePTOEngaged 0 "No PTO drive is engaged" 1 "At least one PTO drive is engaged" 2 "Error" 3 "Not available" ;
